VERSION ""

NS_ :

BS_:

BU_: ABS_BASE ATCM_DMSM GENERIC_GWMWakeup PBM IPMB TCU_TBS FDSM GSM TRCM GWM _delete ABS_ESC HUD IPMA CCM SASM PSCM SCCM HCM ATCM SUMA_RLM ATCM_FFSM PCU SECM VDM TBM OCS GENERIC TCCM TSTR RCM

BO_ 963 BCM_Lamp_Stat_HS2: 8 GWM
 SG_ Illuminated_Entry_Stat : 63|2@0+ (1,0) [0|3] "SED"  GENERIC
 SG_ Dr_Courtesy_Light_Stat : 49|2@0+ (1,0) [0|3] "SED"  GENERIC
 SG_ Courtesy_Delay_Status : 51|2@0+ (1,0) [0|3] "SED"  GENERIC
 SG_ ImpactEvntFdbck_D_Stat : 53|2@0+ (1,0) [0|3] "SED"  RCM
 SG_ WrlssAcsyChrgInhbt_B_Rq : 40|1@0+ (1,0) [0|1] "SED"  GENERIC
 SG_ DrTgateLck_D_Stat : 61|2@0+ (1,0) [0|3] "SED"  GENERIC
 SG_ PudLampPsngr_D_Rq : 57|2@0+ (1,0) [0|3] "SED"  GENERIC
 SG_ HeadLampLoOut_B_Stat : 32|1@0+ (1,0) [0|1] "SED"  GENERIC
 SG_ CrnrLghtRight_Pc_Rq : 47|7@0+ (1,0) [0|100] "percent"  HCM,GENERIC
 SG_ CrnrLghtLeft_Pc_Rq : 39|7@0+ (1,0) [0|100] "percent"  HCM,GENERIC
 SG_ HeadLghtHiFdbck_D_Stat : 55|2@0+ (1,0) [0|3] "SED"  SCCM
 SG_ PrkLightChime_B_Rq : 25|1@0+ (1,0) [0|1] "SED"  GENERIC
 SG_ TrnNotInPrkChime_B_Rq : 24|1@0+ (1,0) [0|1] "SED"  GENERIC
 SG_ KeyInIgnWarn_B_Cmd : 27|1@0+ (1,0) [0|1] "SED"  GENERIC
 SG_ HomeSafeLtChime_B_Rq : 28|1@0+ (1,0) [0|1] "SED"  GENERIC
 SG_ StopLghtOn_B_Stat : 8|1@0+ (1,0) [0|1] "SED"  ABS_BASE,HCM,ABS_ESC
 SG_ RvrseLghtOn_B_Stat : 9|1@0+ (1,0) [0|1] "SED"  GENERIC
 SG_ PrkLght_D_Stat : 13|2@0+ (1,0) [0|3] "SED"  GENERIC
 SG_ HeadLghtSwtch_D_Stat : 15|2@0+ (1,0) [0|3] "SED"  HCM,IPMA
 SG_ HeadLampLoFrOn_B_Stat : 2|1@0+ (1,0) [0|1] "SED"  IPMA,HCM,SCCM
 SG_ HeadLampLoFlOn_B_Stat : 3|1@0+ (1,0) [0|1] "SED"  IPMA,HCM,SCCM
 SG_ HeadLampLoActv_B_Stat : 4|1@0+ (1,0) [0|1] "SED"  HCM,IPMA
 SG_ Headlamp_On_Wrning_Cmd : 29|1@0+ (1,0) [0|1] "SED"  GENERIC
 SG_ HeadLghtHiOn_B_Stat : 1|1@0+ (1,0) [0|1] "SED"  HCM,IPMA
 SG_ Park_Brake_Chime_Rqst : 26|1@0+ (1,0) [0|1] "SED"  GENERIC
 SG_ BrkWarnInd_B_Rq : 20|1@0+ (1,0) [0|1] "SED"  GENERIC
 SG_ Brk_Fluid_Lvl_Low : 31|2@0+ (1,0) [0|3] "SED"  GENERIC
 SG_ ReducedGuard_D_Stat : 19|2@0+ (1,0) [0|3] "SED"  GENERIC
 SG_ Perimeter_Alarm_Status : 17|2@0+ (1,0) [0|3] "SED"  TCU_TBS,GENERIC
 SG_ PudLampDrv_D_Rq : 59|2@0+ (1,0) [0|3] "SED"  GENERIC
 SG_ Courtesy_BSave_Stat : 7|2@0+ (1,0) [0|3] "SED"  GENERIC
 SG_ DayRnngLampOn_B_Stat : 5|1@0+ (1,0) [0|1] "SED"  HCM,IPMA
 SG_ WndwGlbl_D_Cmd : 23|3@0+ (1,0) [0|7] "SED"  GENERIC
 SG_ PudLamp_D_Rq : 11|2@0+ (1,0) [0|3] "SED"  GENERIC
 SG_ PerimeterAlarmChimeRq : 0|1@0+ (1,0) [0|1] "SED"  GENERIC

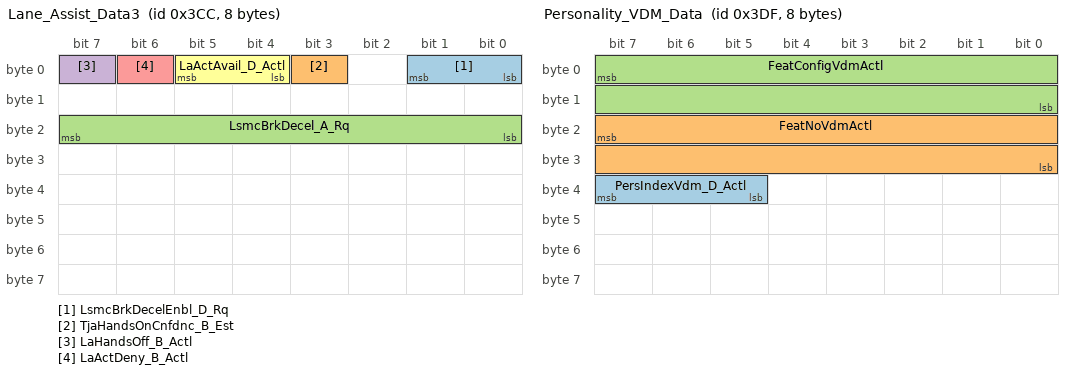
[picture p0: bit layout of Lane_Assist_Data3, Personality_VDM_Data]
BO_ 972 Lane_Assist_Data3: 8 PSCM
 SG_ LsmcBrkDecelEnbl_D_Rq : 1|2@0+ (1,0) [0|3] "SED"  ABS_BASE,ABS_ESC
 SG_ TjaHandsOnCnfdnc_B_Est : 3|1@0+ (1,0) [0|1] "SED"  IPMA
 SG_ LsmcBrkDecel_A_Rq : 23|8@0+ (0.1,0) [0|25.5] "m/s^2"  ABS_BASE,ABS_ESC
 SG_ LaHandsOff_B_Actl : 7|1@0+ (1,0) [0|1] "SED"  GWM,IPMA
 SG_ LaActDeny_B_Actl : 6|1@0+ (1,0) [0|1] "SED"  IPMA,GWM
 SG_ LaActAvail_D_Actl : 5|2@0+ (1,0) [0|3] "SED"  IPMA,GWM

BO_ 991 Personality_VDM_Data: 8 VDM
 SG_ PersIndexVdm_D_Actl : 39|3@0+ (1,0) [0|7] "SED"  GWM
 SG_ FeatNoVdmActl : 23|16@0+ (1,0) [0|65535] "Number"  GWM
 SG_ FeatConfigVdmActl : 7|16@0+ (1,0) [0|65535] "Undefined"  GWM

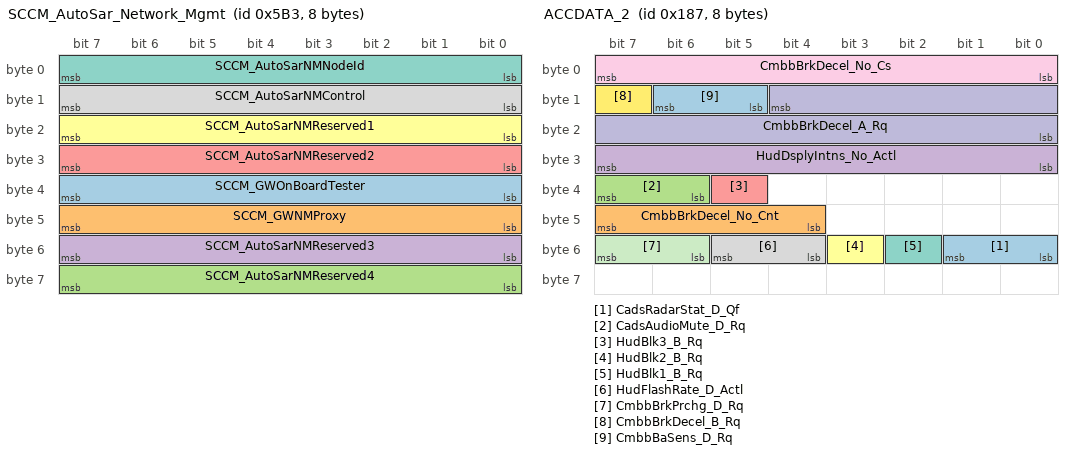
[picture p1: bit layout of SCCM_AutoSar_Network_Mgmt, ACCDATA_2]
BO_ 1459 SCCM_AutoSar_Network_Mgmt: 8 SCCM
 SG_ SCCM_GWOnBoardTester : 39|8@0+ (1,0) [0|255] "unitless"  GWM
 SG_ SCCM_GWNMProxy : 47|8@0+ (1,0) [0|255] "unitless"  GWM
 SG_ SCCM_AutoSarNMReserved4 : 63|8@0+ (1,0) [0|255] "unitless"  GWM
 SG_ SCCM_AutoSarNMReserved3 : 55|8@0+ (1,0) [0|255] "unitless"  GWM
 SG_ SCCM_AutoSarNMReserved2 : 31|8@0+ (1,0) [0|255] "unitless"  GWM
 SG_ SCCM_AutoSarNMReserved1 : 23|8@0+ (1,0) [0|255] "unitless"  GWM
 SG_ SCCM_AutoSarNMNodeId : 7|8@0+ (1,0) [0|255] "unitless"  GWM
 SG_ SCCM_AutoSarNMControl : 15|8@0+ (1,0) [0|255] "unitless"  GWM

BO_ 391 ACCDATA_2: 8 IPMA
 SG_ CadsRadarStat_D_Qf : 49|2@0+ (1,0) [0|3] "SED"  IPMA
 SG_ CmbbBrkDecel_No_Cnt : 47|4@0+ (1,0) [0|15] "Unitless"  ABS_BASE,ABS_ESC
 SG_ CadsAudioMute_D_Rq : 39|2@0+ (1,0) [0|3] "SED"  GWM
 SG_ HudDsplyIntns_No_Actl : 31|8@0+ (0.5,0) [0|100] "%"  HUD
 SG_ HudBlk3_B_Rq : 37|1@0+ (1,0) [0|1] "SED"  HUD
 SG_ HudBlk2_B_Rq : 51|1@0+ (1,0) [0|1] "SED"  HUD
 SG_ HudBlk1_B_Rq : 50|1@0+ (1,0) [0|1] "SED"  HUD
 SG_ HudFlashRate_D_Actl : 53|2@0+ (1,0) [0|3] "SED"  HUD,IPMA
 SG_ CmbbBrkDecel_No_Cs : 7|8@0+ (1,0) [0|255] "Unitless"  ABS_BASE,ABS_ESC
 SG_ CmbbBrkDecel_A_Rq : 12|13@0+ (0.0039,-20) [-20|11.9449] "m/s^2"  ABS_BASE,GWM,ABS_ESC,RCM
 SG_ CmbbBrkPrchg_D_Rq : 55|2@0+ (1,0) [0|3] "SED"  ABS_BASE,GWM,ABS_ESC,RCM
 SG_ CmbbBrkDecel_B_Rq : 15|1@0+ (1,0) [0|1] "SED"  ABS_BASE,GWM,ABS_ESC,RCM
 SG_ CmbbBaSens_D_Rq : 14|2@0+ (1,0) [0|3] "SED"  ABS_BASE,GWM,ABS_ESC,RCM

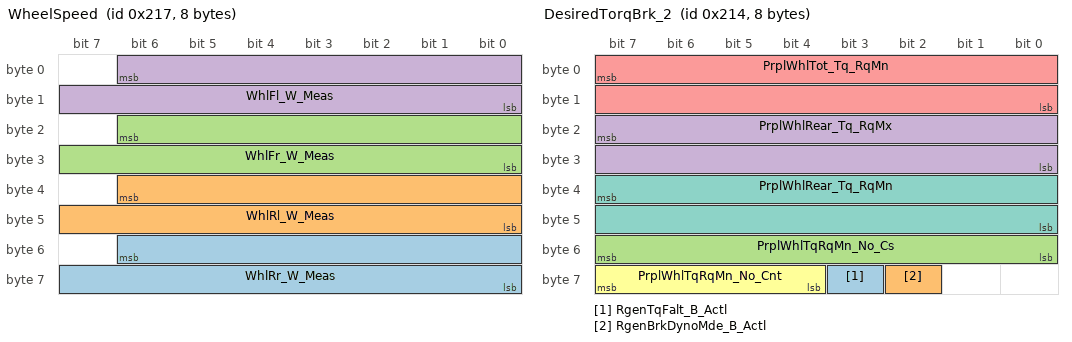
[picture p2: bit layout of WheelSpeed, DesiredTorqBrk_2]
BO_ 535 WheelSpeed: 8 ABS_ESC
 SG_ WhlRr_W_Meas : 54|15@0+ (0.01,0) [0|327.65] "rad/s"  IPMA,IPMB,PBM,TCCM,PSCM,GWM,CCM
 SG_ WhlRl_W_Meas : 38|15@0+ (0.01,0) [0|327.65] "rad/s"  IPMA,IPMB,PBM,TCCM,PSCM,GWM,CCM
 SG_ WhlFr_W_Meas : 22|15@0+ (0.01,0) [0|327.65] "rad/s"  IPMA,IPMB,PBM,TCCM,PSCM,GWM,CCM
 SG_ WhlFl_W_Meas : 6|15@0+ (0.01,0) [0|327.65] "rad/s"  IPMA,IPMB,PBM,TCCM,PSCM,GWM,CCM

BO_ 532 DesiredTorqBrk_2: 8 ABS_ESC
 SG_ RgenTqFalt_B_Actl : 59|1@0+ (1,0) [0|1] "SED"  GWM
 SG_ RgenBrkDynoMde_B_Actl : 58|1@0+ (1,0) [0|1] "SED"  GWM
 SG_ PrplWhlTqRqMn_No_Cs : 55|8@0+ (1,0) [0|255] "Unitless"  GWM
 SG_ PrplWhlRear_Tq_RqMx : 23|16@0+ (4,-131072) [-131072|131068] "Nm"  GWM
 SG_ PrplWhlTot_Tq_RqMn : 7|16@0+ (4,-131072) [-131072|131068] "Nm"  GWM
 SG_ PrplWhlTqRqMn_No_Cnt : 63|4@0+ (1,0) [0|15] "Unitless"  GWM
 SG_ PrplWhlRear_Tq_RqMn : 39|16@0+ (4,-131072) [-131072|131068] "Nm"  GWM

BO_ 531 DesiredTorqBrk: 8 ABS_ESC
 SG_ VehStop_D_Stat : 28|2@0+ (1,0) [0|3] "SED"  GWM,CCM,FDSM,IPMA
 SG_ TracCtlPtActv_B_Actl : 31|1@0+ (1,0) [0|1] "SED"  IPMA,GWM,VDM,TCCM,RCM,CCM
 SG_ LscmbbMntr_B_Err : 17|1@0+ (1,0) [0|1] "SED"  GWM
 SG_ LscmbbBrkDis_B_Actl : 19|1@0+ (1,0) [0|1] "SED"  FDSM,GWM
 SG_ LscmbbDeny_B_ActlBrk : 18|1@0+ (1,0) [0|1] "SED"  FDSM,GWM
 SG_ PrkBrkYwLamp_D_Rq : 38|2@0+ (1,0) [0|3] "SED"  GWM
 SG_ PrkBrkRedLamp_D_Rq : 30|2@0+ (1,0) [0|3] "SED"  GWM
 SG_ VehicleStationary : 39|1@0+ (1,0) [0|1] "SED"  IPMA,GWM,CCM,FDSM
 SG_ LscmbbBrkDecel_B_Actl : 20|1@0+ (1,0) [0|1] "SED"  FDSM,GWM
 SG_ AbsActv_B_Actl : 45|1@0+ (1,0) [0|1] "SED"  IPMA,PBM,SASM,TBM,RCM,CCM,GWM,PSCM,TRCM,VDM
 SG_ StabCtlBrkActv_B_Actl : 23|1@0+ (1,0) [0|1] "SED"  IPMA,SASM,TCCM,PSCM,VDM,GWM,RCM,CCM
 SG_ CmbbBrkPrchg_B_Actl : 59|1@0+ (1,0) [0|1] "SED"  IPMA,TBM,GWM,CCM
 SG_ CmbbBrkDecel_B_Actl : 58|1@0+ (1,0) [0|1] "SED"  IPMA,TBM,GWM,CCM
 SG_ CmbbBaSensInc_B_Actl : 57|1@0+ (1,0) [0|1] "SED"  IPMA,GWM,CCM
 SG_ AccBrkWarm_B_Actl : 63|1@0+ (1,0) [0|1] "SED"  IPMA,GWM,CCM
 SG_ AccBrkTotTqMn_B_Actl : 62|1@0+ (1,0) [0|1] "SED"  IPMA,TBM,GWM,CCM
 SG_ AccBrkPrchgActv_B_Actl : 61|1@0+ (1,0) [0|1] "SED"  IPMA,GWM,CCM
 SG_ AccBrkDis_B_Actl : 44|1@0+ (1,0) [0|1] "SED"  IPMA,GWM,CCM
 SG_ AccBrkDeny_B_Actl : 42|1@0+ (1,0) [0|1] "SED"  IPMA,GWM,CCM
 SG_ AccBrkActv_B_Actl : 43|1@0+ (1,0) [0|1] "SED"  IPMA,GWM,CCM
 SG_ PrplDrgCtlActv_B_Actl : 46|1@0+ (1,0) [0|1] "SED"  GWM
 SG_ PrplWhlTot_Tq_RqMx : 7|16@0+ (4,-131072) [-131072|131068] "Nm"  TCCM,GWM
 SG_ LscmbbBaSensInc_B_Actl : 21|1@0+ (1,0) [0|1] "SED"  FDSM,GWM
 SG_ CmbbBrkDis_B_Actl : 56|1@0+ (1,0) [0|1] "SED"  IPMA,PSCM,GWM,CCM
 SG_ CmbbDeny_B_ActlBrk : 60|1@0+ (1,0) [0|1] "SED"  IPMA,PSCM,GWM,CCM
 SG_ CcDis_B_Cmd : 47|1@0+ (1,0) [0|1] "SED"  GWM
 SG_ VehLongOvrGnd_A_Est : 41|10@0+ (0.035,-17.9) [-17.9|17.835] "m/s^2"  IPMA,VDM,TCCM,TBM,GWM,FDSM,CCM
 SG_ LscmbBrkPrchg_B_Actl : 16|1@0+ (1,0) [0|1] "SED"  FDSM,GWM
 SG_ AccStopActv_B_ActlBrk : 22|1@0+ (1,0) [0|1] "SED"  IPMA,CCM,GWM
 SG_ AccDis_B_ActlEpb : 32|1@0+ (1,0) [0|1] "SED"  IPMA,GWM,CCM
 SG_ PrkBrkMsgTxt_D_Rq : 36|4@0+ (1,0) [0|15] "SED"  GWM
 SG_ PrkBrkStatus : 26|3@0+ (1,0) [0|7] "SED"  GSM,IPMB,IPMA,CCM,GWM

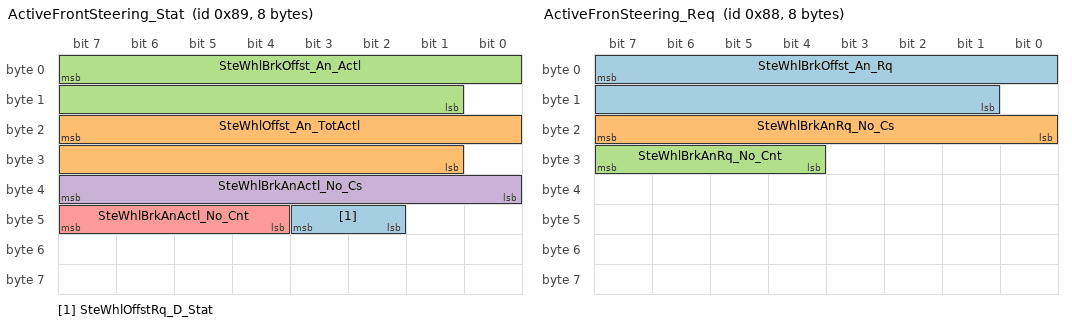
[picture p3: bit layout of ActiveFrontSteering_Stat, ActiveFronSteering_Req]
BO_ 137 ActiveFrontSteering_Stat: 8 SASM
 SG_ SteWhlOffstRq_D_Stat : 43|2@0+ (1,0) [0|3] "SED"  ABS_BASE,ABS_ESC
 SG_ SteWhlOffst_An_TotActl : 23|15@0+ (0.1,-1600) [-1600|1676.5] "degrees"  ABS_BASE,ABS_ESC
 SG_ SteWhlBrkOffst_An_Actl : 7|15@0+ (0.1,-1600) [-1600|1676.5] "degrees"  ABS_BASE,GWM,ABS_ESC
 SG_ SteWhlBrkAnActl_No_Cs : 39|8@0+ (1,0) [0|255] "Unitless"  ABS_BASE,ABS_ESC
 SG_ SteWhlBrkAnActl_No_Cnt : 47|4@0+ (1,0) [0|15] "Unitless"  ABS_BASE,ABS_ESC

BO_ 136 ActiveFronSteering_Req: 8 ABS_ESC
 SG_ SteWhlBrkOffst_An_Rq : 7|15@0+ (0.1,-1600) [-1600|1676.5] "degrees"  SASM
 SG_ SteWhlBrkAnRq_No_Cs : 23|8@0+ (1,0) [0|255] "Unitless"  SASM
 SG_ SteWhlBrkAnRq_No_Cnt : 31|4@0+ (1,0) [0|15] "Unitless"  SASM

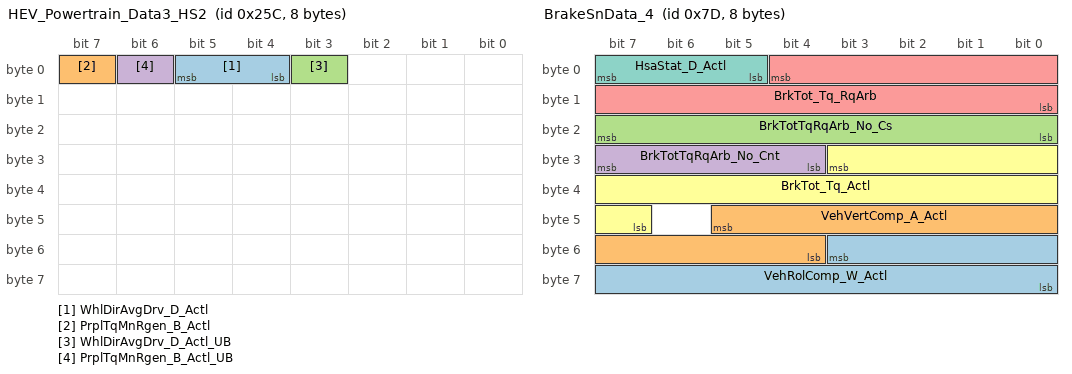
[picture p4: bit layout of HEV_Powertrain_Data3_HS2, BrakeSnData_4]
BO_ 604 HEV_Powertrain_Data3_HS2: 8 GWM
 SG_ WhlDirAvgDrv_D_Actl : 5|2@0+ (1,0) [0|3] "SED"  ABS_ESC,ABS_BASE,FDSM
 SG_ PrplTqMnRgen_B_Actl : 7|1@0+ (1,0) [0|1] "SED"  ABS_ESC,ABS_BASE
 SG_ WhlDirAvgDrv_D_Actl_UB : 3|1@0+ (1,0) [0|1] "SED"  ABS_BASE,ABS_ESC,FDSM
 SG_ PrplTqMnRgen_B_Actl_UB : 6|1@0+ (1,0) [0|1] "SED"  ABS_BASE,ABS_ESC

BO_ 2015 TesterFunctionalReq_H2: 8 TSTR
 SG_ TesterFunctionalReq : 7|64@0+ (1,0) [0|1.84467E+019] ""  SUMA_RLM,ABS_BASE,SECM,ATCM_FFSM,IPMB,SASM,HCM,ATCM_DMSM,TCU_TBS,FDSM,PBM,RCM,GSM,TRCM,PCU,OCS,TCCM,CCM,ABS_ESC,ATCM,HUD,IPMA,PSCM,SCCM,TBM,VDM,GWM

BO_ 125 BrakeSnData_4: 8 ABS_ESC
 SG_ VehRolComp_W_Actl : 51|12@0+ (0.03663,-75) [-75|74.92659] "degrees/sec"  PSCM,VDM,GWM
 SG_ VehVertComp_A_Actl : 45|10@0+ (0.035,-17.9) [-17.9|17.835] "m/s^2"  PSCM,GWM,VDM
 SG_ BrkTotTqRqArb_No_Cs : 23|8@0+ (1,0) [0|255] "Unitless"  TBM,GWM
 SG_ BrkTotTqRqArb_No_Cnt : 31|4@0+ (1,0) [0|15] "Unitless"  TBM,GWM
 SG_ BrkTot_Tq_RqArb : 4|13@0+ (4,0) [0|32756] "Nm"  HCM,IPMA,TBM,VDM,GWM,CCM
 SG_ BrkTot_Tq_Actl : 27|13@0+ (4,0) [0|32756] "Nm"  PSCM,PBM,RCM,FDSM,GWM
 SG_ HsaStat_D_Actl : 7|3@0+ (1,0) [0|7] "SED"  GWM

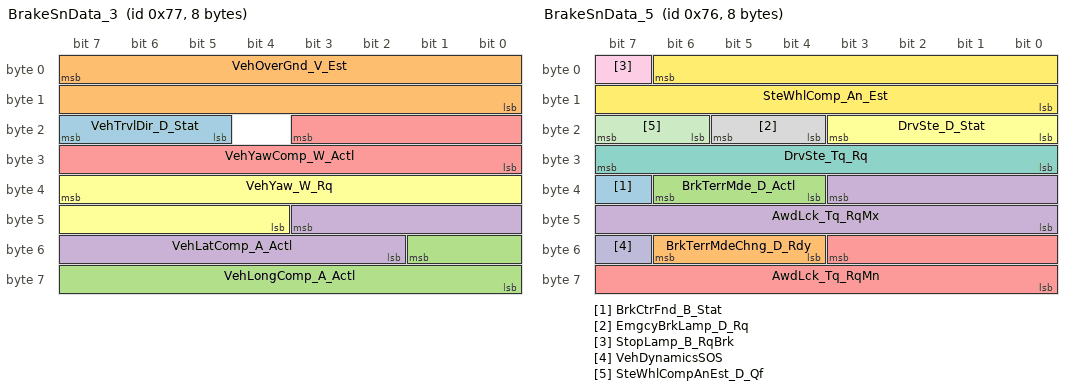
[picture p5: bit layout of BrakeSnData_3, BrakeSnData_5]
BO_ 119 BrakeSnData_3: 8 ABS_ESC
 SG_ VehTrvlDir_D_Stat : 23|3@0+ (1,0) [0|7] "SED"  SASM
 SG_ VehOverGnd_V_Est : 7|16@0+ (0.01,0) [0|655.33] "kph"  IPMA,SASM,PSCM,TCCM,GWM,CCM,FDSM
 SG_ VehLongComp_A_Actl : 49|10@0+ (0.035,-17.9) [-17.9|17.835] "m/s^2"  PBM,PSCM,VDM,GWM
 SG_ VehLatComp_A_Actl : 43|10@0+ (0.035,-17.9) [-17.9|17.835] "m/s^2"  CCM,TCCM,PSCM,FDSM,VDM,GWM
 SG_ VehYawComp_W_Actl : 19|12@0+ (0.03663,-75) [-75|74.92659] "deg/s"  IPMA,VDM,SASM,TCCM,PSCM,FDSM,GWM,CCM
 SG_ VehYaw_W_Rq : 39|12@0+ (0.03663,-75) [-75|74.92659] "deg/s"  GWM

BO_ 118 BrakeSnData_5: 8 ABS_ESC
 SG_ BrkCtrFnd_B_Stat : 39|1@0+ (1,0) [0|1] "SED"  GENERIC
 SG_ BrkTerrMdeChng_D_Rdy : 54|3@0+ (1,0) [0|7] "SED"  GENERIC
 SG_ BrkTerrMde_D_Actl : 38|3@0+ (1,0) [0|7] "SED"  GENERIC
 SG_ AwdLck_Tq_RqMx : 35|12@0+ (1,0) [0|4095] "Nm"  GENERIC
 SG_ AwdLck_Tq_RqMn : 51|12@0+ (1,0) [0|4095] "Nm"  GENERIC
 SG_ DrvSte_D_Stat : 19|4@0+ (1,0) [0|15] "SED"  PSCM,GWM
 SG_ DrvSte_Tq_Rq : 31|8@0+ (0.0625,-8) [-8|7.8125] "Nm"  PSCM,GWM
 SG_ EmgcyBrkLamp_D_Rq : 21|2@0+ (1,0) [0|3] "SED"  GWM
 SG_ StopLamp_B_RqBrk : 7|1@0+ (1,0) [0|1] "SED"  GWM,FDSM
 SG_ VehDynamicsSOS : 55|1@0+ (1,0) [0|1] "SED"  GWM
 SG_ SteWhlCompAnEst_D_Qf : 23|2@0+ (1,0) [0|3] "SED"  IPMA,RCM,GWM
 SG_ SteWhlComp_An_Est : 6|15@0+ (0.1,-1600) [-1600|1676.7] "deg"  IPMA,RCM,GWM

BO_ 1713 ABS_Rapid_Data_Response_2: 8 ABS_ESC
 SG_ UUDTABSResponse2 : 7|64@0+ (1,0) [0|1.844674407371E+019] "unitless"  TSTR

BO_ 1712 ABS_Rapid_Data_Response_1: 8 ABS_ESC
 SG_ UUDTABSResponse1 : 7|64@0+ (1,0) [0|1.844674407371E+019] "unitless"  TSTR

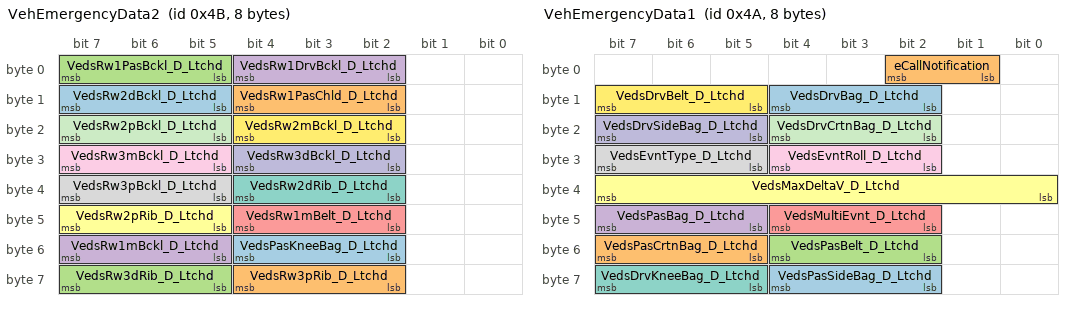
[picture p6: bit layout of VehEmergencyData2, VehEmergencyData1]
BO_ 75 VehEmergencyData2: 8 RCM
 SG_ VedsPasKneeBag_D_Ltchd : 52|3@0+ (1,0) [0|7] "SED"  GWM
 SG_ VedsRw3pRib_D_Ltchd : 60|3@0+ (1,0) [0|7] "SED"  GWM
 SG_ VedsRw3dRib_D_Ltchd : 63|3@0+ (1,0) [0|7] "SED"  GWM
 SG_ VedsRw1mBckl_D_Ltchd : 55|3@0+ (1,0) [0|7] "SED"  GWM
 SG_ VedsRw1mBelt_D_Ltchd : 44|3@0+ (1,0) [0|7] "SED"  GWM
 SG_ VedsRw2pRib_D_Ltchd : 47|3@0+ (1,0) [0|7] "SED"  GWM
 SG_ VedsRw2dRib_D_Ltchd : 36|3@0+ (1,0) [0|7] "SED"  GWM
 SG_ VedsRw3pBckl_D_Ltchd : 39|3@0+ (1,0) [0|7] "SED"  GWM
 SG_ VedsRw3mBckl_D_Ltchd : 31|3@0+ (1,0) [0|7] "SED"  GWM
 SG_ VedsRw3dBckl_D_Ltchd : 28|3@0+ (1,0) [0|7] "SED"  GWM
 SG_ VedsRw2pBckl_D_Ltchd : 23|3@0+ (1,0) [0|7] "SED"  GWM
 SG_ VedsRw2mBckl_D_Ltchd : 20|3@0+ (1,0) [0|7] "SED"  GWM
 SG_ VedsRw2dBckl_D_Ltchd : 15|3@0+ (1,0) [0|7] "SED"  GWM
 SG_ VedsRw1PasChld_D_Ltchd : 12|3@0+ (1,0) [0|7] "SED"  GWM
 SG_ VedsRw1PasBckl_D_Ltchd : 7|3@0+ (1,0) [0|7] "SED"  GWM
 SG_ VedsRw1DrvBckl_D_Ltchd : 4|3@0+ (1,0) [0|7] "SED"  GWM

BO_ 74 VehEmergencyData1: 8 RCM
 SG_ VedsPasSideBag_D_Ltchd : 60|3@0+ (1,0) [0|7] "SED"  GWM
 SG_ VedsPasCrtnBag_D_Ltchd : 55|3@0+ (1,0) [0|7] "SED"  GWM
 SG_ VedsPasBelt_D_Ltchd : 52|3@0+ (1,0) [0|7] "SED"  GWM
 SG_ VedsPasBag_D_Ltchd : 47|3@0+ (1,0) [0|7] "SED"  GWM
 SG_ VedsMultiEvnt_D_Ltchd : 44|3@0+ (1,0) [0|7] "SED"  GWM
 SG_ VedsMaxDeltaV_D_Ltchd : 39|8@0+ (1,0) [0|255] "kph"  GWM
 SG_ VedsDrvKneeBag_D_Ltchd : 63|3@0+ (1,0) [0|7] "SED"  GWM
 SG_ VedsEvntType_D_Ltchd : 31|3@0+ (1,0) [0|7] "SED"  GWM
 SG_ VedsEvntRoll_D_Ltchd : 28|3@0+ (1,0) [0|7] "SED"  GWM
 SG_ VedsDrvSideBag_D_Ltchd : 23|3@0+ (1,0) [0|7] "SED"  GWM
 SG_ VedsDrvCrtnBag_D_Ltchd : 20|3@0+ (1,0) [0|7] "SED"  GWM
 SG_ VedsDrvBelt_D_Ltchd : 15|3@0+ (1,0) [0|7] "SED"  GWM
 SG_ VedsDrvBag_D_Ltchd : 12|3@0+ (1,0) [0|7] "SED"  GWM
 SG_ eCallNotification : 2|2@0+ (1,0) [0|3] "SED"  GWM

BO_TX_BU_ 972 : SASM,SCCM,PSCM;
BO_TX_BU_ 991 : SASM,VDM;
BO_TX_BU_ 391 : CCM,IPMA;
BO_TX_BU_ 535 : ABS_BASE,ABS_ESC;
BO_TX_BU_ 532 : ABS_BASE,ABS_ESC;
BO_TX_BU_ 531 : ABS_BASE,GENERIC_GWMWakeup,ABS_ESC;
BO_TX_BU_ 136 : ABS_BASE,ABS_ESC;
BO_TX_BU_ 125 : ABS_BASE,ABS_ESC;
BO_TX_BU_ 119 : ABS_BASE,ABS_ESC;
BO_TX_BU_ 118 : ABS_BASE,ABS_ESC;
BO_TX_BU_ 1713 : ABS_BASE,ABS_ESC;
BO_TX_BU_ 1712 : ABS_BASE,ABS_ESC;
CM_ SG_ 391 CmbbBrkDecel_A_Rq "ABSGenSigTimeoutTime=1000";
CM_ SG_ 391 CmbbBrkPrchg_D_Rq "ABSGenSigTimeoutTime=1000";
CM_ SG_ 391 CmbbBrkDecel_B_Rq "ABSGenSigTimeoutTime=1000";
CM_ SG_ 391 CmbbBaSens_D_Rq "ABSGenSigTimeoutTime=1000";
CM_ BO_ 532 "IC is NOT to use data in this message for displays, Used data from 415 instead.";
CM_ BO_ 531 "When PBM is present use 0x41B for PrkMsgTxt_D_Rq, PrkBrkRedLamp_D_Rq, PrkBrkYwLamp_D_Rq source signals otherwise ABS will source from 0x213.";
CM_ SG_ 531 VehLongOvrGnd_A_Est "CCMGenSigTimeoutTime=1000";
CM_ BO_ 2015 "OBDII Request ($7DF) messages are for FNOS 1.0.1 only.
Diagnostic Functional Addressing ($7DF) and Dual Rate Periodic messages are for FNOS I3 only.";
CM_ SG_ 118 SteWhlCompAnEst_D_Qf "Legacy signal not supported, reserving bit locations for commodity BCM, PAM, RCM dbc files.  GWM to Tx Init value, no valid data. ";
CM_ SG_ 118 SteWhlComp_An_Est "Legacy signal not supported, reserving bit locations for commodity BCM, PAM, RCM dbc files.  GWM to Tx Init value, no valid data. ";
CM_ BO_ 74 "Reserve eCallNotification message";
BA_DEF_ SG_  "GenSigTimeoutTime_GWM" INT 0 100000;
BA_DEF_ BO_  "FrameGatewayNetwork" STRING ;
BA_DEF_ BO_  "FrameGatewayMS1" HEX 0 1407;
BA_DEF_ BO_  "FrameGatewayHS3" HEX 0 1407;
BA_DEF_ BO_  "FrameGatewayHS1" HEX 0 1407;
BA_DEF_ BO_  "NetworkInitialization" ENUM  "No","Yes";
BA_DEF_ BO_  "FrameGatewayId" HEX 0 1407;
BA_DEF_ BO_  "EventRateOfChange" INT 10 10000;
BA_DEF_ BO_  "GenMsgStartDelayTime" INT 0 10000;
BA_DEF_ BO_  "GenMsgNrOfRepetition" INT 0 100;
BA_DEF_ BO_  "GenMsgDelayTime" INT 0 1000;
BA_DEF_ BO_  "GenMsgCycleTime" INT 0 100000;
BA_DEF_ BO_  "GenMsgSendType" ENUM  "FixedPeriodic","Event","EnabledPeriodic","NotUsed","NotUsed","EventPeriodic","NotUsed","NotUsed","NoMsgSendType";
BA_DEF_ SG_  "U_U611_U625_MY20_Phev_Tx" ENUM  "No","Yes";
BA_DEF_ SG_  "U_CX482_CX483_MY20_Hev_Tx" ENUM  "No","Yes";
BA_DEF_ SG_  "U_CX482_CX483_MY20_Gas_Tx" ENUM  "No","Yes";
BA_DEF_ SG_  "U_CX482_CX483_MY20_Diesel_Tx" ENUM  "No","Yes";
BA_DEF_ SG_  "U_U611_U625_MY20_Hev_Tx" ENUM  "No","Yes";
BA_DEF_ SG_  "U_U611_U625_MY20_Gas_Tx" ENUM  "No","Yes";
BA_DEF_ SG_  "U_U611_U625_MY20_Diesel_Tx" ENUM  "No","Yes";
BA_DEF_ SG_  "U_LC1_B500_MY18_Gas_Tx" ENUM  "No","Yes";
BA_DEF_ SG_  "U_LC1_B500_MY18_Diesel_Tx" ENUM  "No","Yes";
BA_DEF_ SG_  "U_B500_MY18_Diesel_Tx" ENUM  "No","Yes";
BA_DEF_ SG_  "U_B500_MY18_Gas_Tx" ENUM  "No","Yes";
BA_DEF_ SG_  "U_C490_MY18_Tx" ENUM  "No","Yes";
BA_DEF_ SG_  "U_B562_MY18_Gas_Tx" ENUM  "No","Yes";
BA_DEF_ SG_  "U_C519_MY18_5_Gas_Tx" ENUM  "No","Yes";
BA_DEF_ SG_  "U_C519_MY18_5_Diesel_Tx" ENUM  "No","Yes";
BA_DEF_ SG_  "U_B515_MCA_MY17_Gas_Tx" ENUM  "No","Yes";
BA_DEF_ SG_  "U_B515_MCA_MY17_Diesel_Tx" ENUM  "No","Yes";
BA_DEF_ SG_  "U_B479_MY17_Diesel_Tx" ENUM  "No","Yes";
BA_DEF_ SG_  "U_B479_MY17_Gas_Tx" ENUM  "No","Yes";
BA_DEF_ SG_  "U_B562LC_MY15_Gas_Tx" ENUM  "No","Yes";
BA_DEF_ SG_  "U_B562LC_MY15_Diesel_Tx" ENUM  "No","Yes";
BA_DEF_ SG_  "U_U611_U625_MY20_Phev_Rx" ENUM  "No","Yes";
BA_DEF_ SG_  "U_CX482_CX483_MY20_Hev_Rx" ENUM  "No","Yes";
BA_DEF_ SG_  "U_CX482_CX483_MY20_Gas_Rx" ENUM  "No","Yes";
BA_DEF_ SG_  "U_CX482_CX483_MY20_Diesel_Rx" ENUM  "No","Yes";
BA_DEF_ SG_  "U_U611_U625_MY20_Hev_Rx" ENUM  "No","Yes";
BA_DEF_ SG_  "U_U611_U625_MY20_Gas_Rx" ENUM  "No","Yes";
BA_DEF_ SG_  "U_U611_U625_MY20_Diesel_Rx" ENUM  "No","Yes";
BA_DEF_ SG_  "U_B500_MY18_Diesel_Rx" ENUM  "No","Yes";
BA_DEF_ SG_  "U_B500_MY18_Gas_Rx" ENUM  "No","Yes";
BA_DEF_ SG_  "U_C490_MY18_Rx" ENUM  "No","Yes";
BA_DEF_ SG_  "U_B562_MY18_Gas_Rx" ENUM  "No","Yes";
BA_DEF_ SG_  "U_C519_MY18_5_Gas_Rx" ENUM  "No","Yes";
BA_DEF_ SG_  "U_C519_MY18_5_Diesel_Rx" ENUM  "No","Yes";
BA_DEF_ SG_  "U_B515_MCA_MY17_Gas_Rx" ENUM  "No","Yes";
BA_DEF_ SG_  "U_B515_MCA_MY17_Diesel_Rx" ENUM  "No","Yes";
BA_DEF_ SG_  "U_B479_MY17_Diesel_Rx" ENUM  "No","Yes";
BA_DEF_ SG_  "U_B479_MY17_Gas_Rx" ENUM  "No","Yes";
BA_DEF_ SG_  "U_B562LC_MY15_Gas_Rx" ENUM  "No","Yes";
BA_DEF_ SG_  "U_B562LC_MY15_Diesel_Rx" ENUM  "No","Yes";
BA_DEF_ SG_  "ContentDependant" ENUM  "No","Yes";
BA_DEF_ SG_  "GenSigStartValue" INT 0 1000000000;
BA_DEF_ SG_  "UsedOnPgmDBC" ENUM  "No","Yes";
BA_DEF_ SG_  "CrossOver_InfoCAN" ENUM  "No","Yes";
BA_DEF_ SG_  "WakeupSignal" ENUM  "No","Yes";
BA_DEF_ SG_  "GenSigMissingSourceValue" INT 0 1000000000;
BA_DEF_ SG_  "GenSigSendType" ENUM  "Cyclic","OnWrite","vector_leerstring","OnChange","vector_leerstring","IfActive","vector_leerstring","NoSigSendType";
BA_DEF_ BO_  "GenMsgRoutingTimeoutTime" INT 0 1000;
BA_DEF_ BO_  "MessageGateway" ENUM  "No","Yes";
BA_DEF_ BO_  "NmAsrMessage" ENUM  "No","Yes";
BA_DEF_ BO_  "TpApplType" STRING ;
BA_DEF_ BO_  "DiagState" ENUM  "No","Yes";
BA_DEF_ BO_  "DiagRequest" ENUM  "No","Yes";
BA_DEF_ BO_  "DiagResponse" ENUM  "No","Yes";
BA_DEF_ BO_  "GenMsgILSupport" ENUM  "No","Yes";
BA_DEF_DEF_  "GenSigTimeoutTime_GWM" 0;
BA_DEF_DEF_  "FrameGatewayNetwork" "NONE";
BA_DEF_DEF_  "FrameGatewayMS1" 0;
BA_DEF_DEF_  "FrameGatewayHS3" 0;
BA_DEF_DEF_  "FrameGatewayHS1" 0;
BA_DEF_DEF_  "NetworkInitialization" "Yes";
BA_DEF_DEF_  "FrameGatewayId" 0;
BA_DEF_DEF_  "EventRateOfChange" 10000;
BA_DEF_DEF_  "GenMsgStartDelayTime" 0;
BA_DEF_DEF_  "GenMsgNrOfRepetition" 1;
BA_DEF_DEF_  "GenMsgDelayTime" 20;
BA_DEF_DEF_  "GenMsgCycleTime" 0;
BA_DEF_DEF_  "GenMsgSendType" "NoMsgSendType";
BA_DEF_DEF_  "U_U611_U625_MY20_Phev_Tx" "No";
BA_DEF_DEF_  "U_CX482_CX483_MY20_Hev_Tx" "No";
BA_DEF_DEF_  "U_CX482_CX483_MY20_Gas_Tx" "No";
BA_DEF_DEF_  "U_CX482_CX483_MY20_Diesel_Tx" "No";
BA_DEF_DEF_  "U_U611_U625_MY20_Hev_Tx" "No";
BA_DEF_DEF_  "U_U611_U625_MY20_Gas_Tx" "No";
BA_DEF_DEF_  "U_U611_U625_MY20_Diesel_Tx" "No";
BA_DEF_DEF_  "U_LC1_B500_MY18_Gas_Tx" "No";
BA_DEF_DEF_  "U_LC1_B500_MY18_Diesel_Tx" "No";
BA_DEF_DEF_  "U_B500_MY18_Diesel_Tx" "No";
BA_DEF_DEF_  "U_B500_MY18_Gas_Tx" "No";
BA_DEF_DEF_  "U_C490_MY18_Tx" "No";
BA_DEF_DEF_  "U_B562_MY18_Gas_Tx" "No";
BA_DEF_DEF_  "U_C519_MY18_5_Gas_Tx" "No";
BA_DEF_DEF_  "U_C519_MY18_5_Diesel_Tx" "No";
BA_DEF_DEF_  "U_B515_MCA_MY17_Gas_Tx" "No";
BA_DEF_DEF_  "U_B515_MCA_MY17_Diesel_Tx" "No";
BA_DEF_DEF_  "U_B479_MY17_Diesel_Tx" "No";
BA_DEF_DEF_  "U_B479_MY17_Gas_Tx" "No";
BA_DEF_DEF_  "U_B562LC_MY15_Gas_Tx" "No";
BA_DEF_DEF_  "U_B562LC_MY15_Diesel_Tx" "No";
BA_DEF_DEF_  "U_U611_U625_MY20_Phev_Rx" "No";
BA_DEF_DEF_  "U_CX482_CX483_MY20_Hev_Rx" "No";
BA_DEF_DEF_  "U_CX482_CX483_MY20_Gas_Rx" "No";
BA_DEF_DEF_  "U_CX482_CX483_MY20_Diesel_Rx" "No";
BA_DEF_DEF_  "U_U611_U625_MY20_Hev_Rx" "No";
BA_DEF_DEF_  "U_U611_U625_MY20_Gas_Rx" "No";
BA_DEF_DEF_  "U_U611_U625_MY20_Diesel_Rx" "No";
BA_DEF_DEF_  "U_B500_MY18_Diesel_Rx" "No";
BA_DEF_DEF_  "U_B500_MY18_Gas_Rx" "No";
BA_DEF_DEF_  "U_C490_MY18_Rx" "No";
BA_DEF_DEF_  "U_B562_MY18_Gas_Rx" "No";
BA_DEF_DEF_  "U_C519_MY18_5_Gas_Rx" "No";
BA_DEF_DEF_  "U_C519_MY18_5_Diesel_Rx" "No";
BA_DEF_DEF_  "U_B515_MCA_MY17_Gas_Rx" "No";
BA_DEF_DEF_  "U_B515_MCA_MY17_Diesel_Rx" "No";
BA_DEF_DEF_  "U_B479_MY17_Diesel_Rx" "No";
BA_DEF_DEF_  "U_B479_MY17_Gas_Rx" "No";
BA_DEF_DEF_  "U_B562LC_MY15_Gas_Rx" "No";
BA_DEF_DEF_  "U_B562LC_MY15_Diesel_Rx" "No";
BA_DEF_DEF_  "ContentDependant" "No";
BA_DEF_DEF_  "GenSigStartValue" 0;
BA_DEF_DEF_  "UsedOnPgmDBC" "Yes";
BA_DEF_DEF_  "CrossOver_InfoCAN" "No";
BA_DEF_DEF_  "WakeupSignal" "No";
BA_DEF_DEF_  "GenSigMissingSourceValue" 0;
BA_DEF_DEF_  "GenSigSendType" "NoSigSendType";
BA_DEF_DEF_  "GenMsgRoutingTimeoutTime" 0;
BA_DEF_DEF_  "MessageGateway" "No";
BA_DEF_DEF_  "NmAsrMessage" "No";
BA_DEF_DEF_  "TpApplType" "";
BA_DEF_DEF_  "DiagState" "No";
BA_DEF_DEF_  "DiagRequest" "No";
BA_DEF_DEF_  "DiagResponse" "No";
BA_DEF_DEF_  "GenMsgILSupport" "Yes";
BA_ "FrameGatewayNetwork" BO_ 963 "HS1_CAN";
BA_ "FrameGatewayHS1" BO_ 963 963;
BA_ "FrameGatewayId" BO_ 963 963;
BA_ "GenMsgStartDelayTime" BO_ 963 300;
BA_ "GenMsgDelayTime" BO_ 972 10;
BA_ "GenMsgCycleTime" BO_ 972 30;
BA_ "GenMsgSendType" BO_ 972 0;
BA_ "GenMsgCycleTime" BO_ 991 1000;
BA_ "GenMsgSendType" BO_ 991 5;
BA_ "NetworkInitialization" BO_ 1459 0;
BA_ "GenMsgCycleTime" BO_ 1459 1000;
BA_ "GenMsgSendType" BO_ 1459 0;
BA_ "NmAsrMessage" BO_ 1459 1;
BA_ "GenMsgILSupport" BO_ 1459 0;
BA_ "GenMsgDelayTime" BO_ 391 10;
BA_ "GenMsgCycleTime" BO_ 391 20;
BA_ "GenMsgSendType" BO_ 391 0;
BA_ "GenMsgDelayTime" BO_ 535 0;
BA_ "GenMsgCycleTime" BO_ 535 10;
BA_ "GenMsgSendType" BO_ 535 0;
BA_ "GenMsgDelayTime" BO_ 532 10;
BA_ "GenMsgCycleTime" BO_ 532 20;
BA_ "GenMsgSendType" BO_ 532 0;
BA_ "GenMsgDelayTime" BO_ 531 10;
BA_ "GenMsgCycleTime" BO_ 531 20;
BA_ "GenMsgSendType" BO_ 531 0;
BA_ "FrameGatewayNetwork" BO_ 137 "HS2_CAN";
BA_ "FrameGatewayId" BO_ 137 137;
BA_ "GenMsgDelayTime" BO_ 137 0;
BA_ "GenMsgCycleTime" BO_ 137 10;
BA_ "GenMsgSendType" BO_ 137 0;
BA_ "GenMsgDelayTime" BO_ 136 0;
BA_ "GenMsgCycleTime" BO_ 136 10;
BA_ "GenMsgSendType" BO_ 136 0;
BA_ "GenMsgCycleTime" BO_ 604 100;
BA_ "GenMsgSendType" BO_ 604 5;
BA_ "NetworkInitialization" BO_ 2015 0;
BA_ "GenMsgDelayTime" BO_ 2015 0;
BA_ "GenMsgSendType" BO_ 2015 1;
BA_ "DiagState" BO_ 2015 1;
BA_ "GenMsgILSupport" BO_ 2015 0;
BA_ "GenMsgDelayTime" BO_ 125 10;
BA_ "GenMsgCycleTime" BO_ 125 20;
BA_ "GenMsgSendType" BO_ 125 0;
BA_ "GenMsgDelayTime" BO_ 119 10;
BA_ "GenMsgCycleTime" BO_ 119 20;
BA_ "GenMsgSendType" BO_ 119 0;
BA_ "GenMsgCycleTime" BO_ 118 500;
BA_ "GenMsgSendType" BO_ 118 5;
BA_ "NetworkInitialization" BO_ 1713 0;
BA_ "GenMsgDelayTime" BO_ 1713 10;
BA_ "GenMsgSendType" BO_ 1713 1;
BA_ "TpApplType" BO_ 1713 "DiagUUDTResponse";
BA_ "GenMsgILSupport" BO_ 1713 0;
BA_ "NetworkInitialization" BO_ 1712 0;
BA_ "GenMsgDelayTime" BO_ 1712 10;
BA_ "GenMsgSendType" BO_ 1712 1;
BA_ "TpApplType" BO_ 1712 "DiagUUDTResponse";
BA_ "GenMsgILSupport" BO_ 1712 0;
BA_ "GenMsgDelayTime" BO_ 75 10;
BA_ "GenMsgCycleTime" BO_ 75 100;
BA_ "GenMsgSendType" BO_ 75 5;
BA_ "GenMsgDelayTime" BO_ 74 10;
BA_ "GenMsgCycleTime" BO_ 74 100;
BA_ "GenMsgSendType" BO_ 74 5;
BA_ "U_CX482_CX483_MY20_Hev_Rx" SG_ 963 ImpactEvntFdbck_D_Stat 1;
BA_ "U_CX482_CX483_MY20_Gas_Rx" SG_ 963 ImpactEvntFdbck_D_Stat 1;
BA_ "U_CX482_CX483_MY20_Diesel_Rx" SG_ 963 ImpactEvntFdbck_D_Stat 1;
BA_ "U_U611_U625_MY20_Hev_Rx" SG_ 963 ImpactEvntFdbck_D_Stat 1;
BA_ "U_U611_U625_MY20_Gas_Rx" SG_ 963 ImpactEvntFdbck_D_Stat 1;
BA_ "U_U611_U625_MY20_Diesel_Rx" SG_ 963 ImpactEvntFdbck_D_Stat 1;
BA_ "U_B500_MY18_Diesel_Rx" SG_ 963 ImpactEvntFdbck_D_Stat 1;
BA_ "U_B500_MY18_Gas_Rx" SG_ 963 ImpactEvntFdbck_D_Stat 1;
BA_ "U_C490_MY18_Rx" SG_ 963 ImpactEvntFdbck_D_Stat 1;
BA_ "U_B562_MY18_Gas_Rx" SG_ 963 ImpactEvntFdbck_D_Stat 1;
BA_ "U_C519_MY18_5_Gas_Rx" SG_ 963 ImpactEvntFdbck_D_Stat 1;
BA_ "U_C519_MY18_5_Diesel_Rx" SG_ 963 ImpactEvntFdbck_D_Stat 1;
BA_ "U_B515_MCA_MY17_Gas_Rx" SG_ 963 ImpactEvntFdbck_D_Stat 1;
BA_ "U_B515_MCA_MY17_Diesel_Rx" SG_ 963 ImpactEvntFdbck_D_Stat 1;
BA_ "U_B479_MY17_Diesel_Rx" SG_ 963 ImpactEvntFdbck_D_Stat 1;
BA_ "U_B479_MY17_Gas_Rx" SG_ 963 ImpactEvntFdbck_D_Stat 1;
BA_ "CrossOver_InfoCAN" SG_ 963 ImpactEvntFdbck_D_Stat 1;
BA_ "WakeupSignal" SG_ 963 ImpactEvntFdbck_D_Stat 1;
BA_ "CrossOver_InfoCAN" SG_ 963 HeadLampLoOut_B_Stat 1;
BA_ "U_CX482_CX483_MY20_Hev_Rx" SG_ 963 CrnrLghtRight_Pc_Rq 1;
BA_ "U_CX482_CX483_MY20_Gas_Rx" SG_ 963 CrnrLghtRight_Pc_Rq 1;
BA_ "U_CX482_CX483_MY20_Diesel_Rx" SG_ 963 CrnrLghtRight_Pc_Rq 1;
BA_ "U_C519_MY18_5_Gas_Rx" SG_ 963 CrnrLghtRight_Pc_Rq 1;
BA_ "U_C519_MY18_5_Diesel_Rx" SG_ 963 CrnrLghtRight_Pc_Rq 1;
BA_ "CrossOver_InfoCAN" SG_ 963 CrnrLghtRight_Pc_Rq 1;
BA_ "U_CX482_CX483_MY20_Hev_Rx" SG_ 963 CrnrLghtLeft_Pc_Rq 1;
BA_ "U_CX482_CX483_MY20_Gas_Rx" SG_ 963 CrnrLghtLeft_Pc_Rq 1;
BA_ "U_CX482_CX483_MY20_Diesel_Rx" SG_ 963 CrnrLghtLeft_Pc_Rq 1;
BA_ "U_C519_MY18_5_Gas_Rx" SG_ 963 CrnrLghtLeft_Pc_Rq 1;
BA_ "U_C519_MY18_5_Diesel_Rx" SG_ 963 CrnrLghtLeft_Pc_Rq 1;
BA_ "CrossOver_InfoCAN" SG_ 963 CrnrLghtLeft_Pc_Rq 1;
BA_ "U_U611_U625_MY20_Phev_Rx" SG_ 963 HeadLghtHiFdbck_D_Stat 1;
BA_ "U_CX482_CX483_MY20_Hev_Rx" SG_ 963 HeadLghtHiFdbck_D_Stat 1;
BA_ "U_CX482_CX483_MY20_Gas_Rx" SG_ 963 HeadLghtHiFdbck_D_Stat 1;
BA_ "U_CX482_CX483_MY20_Diesel_Rx" SG_ 963 HeadLghtHiFdbck_D_Stat 1;
BA_ "U_U611_U625_MY20_Hev_Rx" SG_ 963 HeadLghtHiFdbck_D_Stat 1;
BA_ "U_U611_U625_MY20_Gas_Rx" SG_ 963 HeadLghtHiFdbck_D_Stat 1;
BA_ "U_U611_U625_MY20_Diesel_Rx" SG_ 963 HeadLghtHiFdbck_D_Stat 1;
BA_ "U_B500_MY18_Diesel_Rx" SG_ 963 HeadLghtHiFdbck_D_Stat 1;
BA_ "U_B500_MY18_Gas_Rx" SG_ 963 HeadLghtHiFdbck_D_Stat 1;
BA_ "U_C519_MY18_5_Gas_Rx" SG_ 963 HeadLghtHiFdbck_D_Stat 1;
BA_ "U_C519_MY18_5_Diesel_Rx" SG_ 963 HeadLghtHiFdbck_D_Stat 1;
BA_ "U_B515_MCA_MY17_Gas_Rx" SG_ 963 HeadLghtHiFdbck_D_Stat 1;
BA_ "U_B515_MCA_MY17_Diesel_Rx" SG_ 963 HeadLghtHiFdbck_D_Stat 1;
BA_ "U_B479_MY17_Diesel_Rx" SG_ 963 HeadLghtHiFdbck_D_Stat 1;
BA_ "U_B479_MY17_Gas_Rx" SG_ 963 HeadLghtHiFdbck_D_Stat 1;
BA_ "CrossOver_InfoCAN" SG_ 963 HeadLghtHiFdbck_D_Stat 1;
BA_ "CrossOver_InfoCAN" SG_ 963 PrkLightChime_B_Rq 1;
BA_ "CrossOver_InfoCAN" SG_ 963 TrnNotInPrkChime_B_Rq 1;
BA_ "CrossOver_InfoCAN" SG_ 963 KeyInIgnWarn_B_Cmd 1;
BA_ "WakeupSignal" SG_ 963 KeyInIgnWarn_B_Cmd 1;
BA_ "CrossOver_InfoCAN" SG_ 963 HomeSafeLtChime_B_Rq 1;
BA_ "WakeupSignal" SG_ 963 HomeSafeLtChime_B_Rq 1;
BA_ "U_CX482_CX483_MY20_Hev_Rx" SG_ 963 StopLghtOn_B_Stat 1;
BA_ "U_CX482_CX483_MY20_Gas_Rx" SG_ 963 StopLghtOn_B_Stat 1;
BA_ "U_CX482_CX483_MY20_Diesel_Rx" SG_ 963 StopLghtOn_B_Stat 1;
BA_ "U_U611_U625_MY20_Hev_Rx" SG_ 963 StopLghtOn_B_Stat 1;
BA_ "U_U611_U625_MY20_Gas_Rx" SG_ 963 StopLghtOn_B_Stat 1;
BA_ "U_U611_U625_MY20_Diesel_Rx" SG_ 963 StopLghtOn_B_Stat 1;
BA_ "U_C519_MY18_5_Gas_Rx" SG_ 963 StopLghtOn_B_Stat 1;
BA_ "U_C519_MY18_5_Diesel_Rx" SG_ 963 StopLghtOn_B_Stat 1;
BA_ "U_B515_MCA_MY17_Gas_Rx" SG_ 963 StopLghtOn_B_Stat 1;
BA_ "U_B515_MCA_MY17_Diesel_Rx" SG_ 963 StopLghtOn_B_Stat 1;
BA_ "U_B479_MY17_Diesel_Rx" SG_ 963 StopLghtOn_B_Stat 1;
BA_ "U_B479_MY17_Gas_Rx" SG_ 963 StopLghtOn_B_Stat 1;
BA_ "CrossOver_InfoCAN" SG_ 963 StopLghtOn_B_Stat 1;
BA_ "WakeupSignal" SG_ 963 StopLghtOn_B_Stat 1;
BA_ "CrossOver_InfoCAN" SG_ 963 RvrseLghtOn_B_Stat 1;
BA_ "CrossOver_InfoCAN" SG_ 963 PrkLght_D_Stat 1;
BA_ "WakeupSignal" SG_ 963 PrkLght_D_Stat 1;
BA_ "U_CX482_CX483_MY20_Hev_Rx" SG_ 963 HeadLghtSwtch_D_Stat 1;
BA_ "U_CX482_CX483_MY20_Gas_Rx" SG_ 963 HeadLghtSwtch_D_Stat 1;
BA_ "U_CX482_CX483_MY20_Diesel_Rx" SG_ 963 HeadLghtSwtch_D_Stat 1;
BA_ "U_U611_U625_MY20_Hev_Rx" SG_ 963 HeadLghtSwtch_D_Stat 1;
BA_ "U_U611_U625_MY20_Gas_Rx" SG_ 963 HeadLghtSwtch_D_Stat 1;
BA_ "U_U611_U625_MY20_Diesel_Rx" SG_ 963 HeadLghtSwtch_D_Stat 1;
BA_ "U_C519_MY18_5_Gas_Rx" SG_ 963 HeadLghtSwtch_D_Stat 1;
BA_ "U_C519_MY18_5_Diesel_Rx" SG_ 963 HeadLghtSwtch_D_Stat 1;
BA_ "U_B479_MY17_Diesel_Rx" SG_ 963 HeadLghtSwtch_D_Stat 1;
BA_ "U_B479_MY17_Gas_Rx" SG_ 963 HeadLghtSwtch_D_Stat 1;
BA_ "GenSigStartValue" SG_ 963 HeadLghtSwtch_D_Stat 2;
BA_ "CrossOver_InfoCAN" SG_ 963 HeadLghtSwtch_D_Stat 1;
BA_ "WakeupSignal" SG_ 963 HeadLghtSwtch_D_Stat 1;
BA_ "U_U611_U625_MY20_Phev_Rx" SG_ 963 HeadLampLoFrOn_B_Stat 1;
BA_ "U_CX482_CX483_MY20_Hev_Rx" SG_ 963 HeadLampLoFrOn_B_Stat 1;
BA_ "U_CX482_CX483_MY20_Gas_Rx" SG_ 963 HeadLampLoFrOn_B_Stat 1;
BA_ "U_CX482_CX483_MY20_Diesel_Rx" SG_ 963 HeadLampLoFrOn_B_Stat 1;
BA_ "U_U611_U625_MY20_Hev_Rx" SG_ 963 HeadLampLoFrOn_B_Stat 1;
BA_ "U_U611_U625_MY20_Gas_Rx" SG_ 963 HeadLampLoFrOn_B_Stat 1;
BA_ "U_U611_U625_MY20_Diesel_Rx" SG_ 963 HeadLampLoFrOn_B_Stat 1;
BA_ "U_B500_MY18_Diesel_Rx" SG_ 963 HeadLampLoFrOn_B_Stat 1;
BA_ "U_B500_MY18_Gas_Rx" SG_ 963 HeadLampLoFrOn_B_Stat 1;
BA_ "U_C519_MY18_5_Gas_Rx" SG_ 963 HeadLampLoFrOn_B_Stat 1;
BA_ "U_C519_MY18_5_Diesel_Rx" SG_ 963 HeadLampLoFrOn_B_Stat 1;
BA_ "U_B515_MCA_MY17_Gas_Rx" SG_ 963 HeadLampLoFrOn_B_Stat 1;
BA_ "U_B515_MCA_MY17_Diesel_Rx" SG_ 963 HeadLampLoFrOn_B_Stat 1;
BA_ "U_B479_MY17_Diesel_Rx" SG_ 963 HeadLampLoFrOn_B_Stat 1;
BA_ "U_B479_MY17_Gas_Rx" SG_ 963 HeadLampLoFrOn_B_Stat 1;
BA_ "GenSigStartValue" SG_ 963 HeadLampLoFrOn_B_Stat 1;
BA_ "CrossOver_InfoCAN" SG_ 963 HeadLampLoFrOn_B_Stat 1;
BA_ "U_U611_U625_MY20_Phev_Rx" SG_ 963 HeadLampLoFlOn_B_Stat 1;
BA_ "U_CX482_CX483_MY20_Hev_Rx" SG_ 963 HeadLampLoFlOn_B_Stat 1;
BA_ "U_CX482_CX483_MY20_Gas_Rx" SG_ 963 HeadLampLoFlOn_B_Stat 1;
BA_ "U_CX482_CX483_MY20_Diesel_Rx" SG_ 963 HeadLampLoFlOn_B_Stat 1;
BA_ "U_U611_U625_MY20_Hev_Rx" SG_ 963 HeadLampLoFlOn_B_Stat 1;
BA_ "U_U611_U625_MY20_Gas_Rx" SG_ 963 HeadLampLoFlOn_B_Stat 1;
BA_ "U_U611_U625_MY20_Diesel_Rx" SG_ 963 HeadLampLoFlOn_B_Stat 1;
BA_ "U_B500_MY18_Diesel_Rx" SG_ 963 HeadLampLoFlOn_B_Stat 1;
BA_ "U_B500_MY18_Gas_Rx" SG_ 963 HeadLampLoFlOn_B_Stat 1;
BA_ "U_C519_MY18_5_Gas_Rx" SG_ 963 HeadLampLoFlOn_B_Stat 1;
BA_ "U_C519_MY18_5_Diesel_Rx" SG_ 963 HeadLampLoFlOn_B_Stat 1;
BA_ "U_B515_MCA_MY17_Gas_Rx" SG_ 963 HeadLampLoFlOn_B_Stat 1;
BA_ "U_B515_MCA_MY17_Diesel_Rx" SG_ 963 HeadLampLoFlOn_B_Stat 1;
BA_ "U_B479_MY17_Diesel_Rx" SG_ 963 HeadLampLoFlOn_B_Stat 1;
BA_ "U_B479_MY17_Gas_Rx" SG_ 963 HeadLampLoFlOn_B_Stat 1;
BA_ "GenSigStartValue" SG_ 963 HeadLampLoFlOn_B_Stat 1;
BA_ "CrossOver_InfoCAN" SG_ 963 HeadLampLoFlOn_B_Stat 1;
BA_ "U_CX482_CX483_MY20_Hev_Rx" SG_ 963 HeadLampLoActv_B_Stat 1;
BA_ "U_CX482_CX483_MY20_Gas_Rx" SG_ 963 HeadLampLoActv_B_Stat 1;
BA_ "U_CX482_CX483_MY20_Diesel_Rx" SG_ 963 HeadLampLoActv_B_Stat 1;
BA_ "U_U611_U625_MY20_Hev_Rx" SG_ 963 HeadLampLoActv_B_Stat 1;
BA_ "U_U611_U625_MY20_Gas_Rx" SG_ 963 HeadLampLoActv_B_Stat 1;
BA_ "U_U611_U625_MY20_Diesel_Rx" SG_ 963 HeadLampLoActv_B_Stat 1;
BA_ "U_C519_MY18_5_Gas_Rx" SG_ 963 HeadLampLoActv_B_Stat 1;
BA_ "U_C519_MY18_5_Diesel_Rx" SG_ 963 HeadLampLoActv_B_Stat 1;
BA_ "U_B479_MY17_Diesel_Rx" SG_ 963 HeadLampLoActv_B_Stat 1;
BA_ "U_B479_MY17_Gas_Rx" SG_ 963 HeadLampLoActv_B_Stat 1;
BA_ "GenSigStartValue" SG_ 963 HeadLampLoActv_B_Stat 1;
BA_ "CrossOver_InfoCAN" SG_ 963 HeadLampLoActv_B_Stat 1;
BA_ "CrossOver_InfoCAN" SG_ 963 Headlamp_On_Wrning_Cmd 1;
BA_ "WakeupSignal" SG_ 963 Headlamp_On_Wrning_Cmd 1;
BA_ "U_CX482_CX483_MY20_Hev_Rx" SG_ 963 HeadLghtHiOn_B_Stat 1;
BA_ "U_CX482_CX483_MY20_Gas_Rx" SG_ 963 HeadLghtHiOn_B_Stat 1;
BA_ "U_CX482_CX483_MY20_Diesel_Rx" SG_ 963 HeadLghtHiOn_B_Stat 1;
BA_ "U_U611_U625_MY20_Hev_Rx" SG_ 963 HeadLghtHiOn_B_Stat 1;
BA_ "U_U611_U625_MY20_Gas_Rx" SG_ 963 HeadLghtHiOn_B_Stat 1;
BA_ "U_U611_U625_MY20_Diesel_Rx" SG_ 963 HeadLghtHiOn_B_Stat 1;
BA_ "U_C519_MY18_5_Gas_Rx" SG_ 963 HeadLghtHiOn_B_Stat 1;
BA_ "U_C519_MY18_5_Diesel_Rx" SG_ 963 HeadLghtHiOn_B_Stat 1;
BA_ "U_B479_MY17_Diesel_Rx" SG_ 963 HeadLghtHiOn_B_Stat 1;
BA_ "U_B479_MY17_Gas_Rx" SG_ 963 HeadLghtHiOn_B_Stat 1;
BA_ "CrossOver_InfoCAN" SG_ 963 HeadLghtHiOn_B_Stat 1;
BA_ "WakeupSignal" SG_ 963 HeadLghtHiOn_B_Stat 1;
BA_ "CrossOver_InfoCAN" SG_ 963 Park_Brake_Chime_Rqst 1;
BA_ "CrossOver_InfoCAN" SG_ 963 BrkWarnInd_B_Rq 1;
BA_ "WakeupSignal" SG_ 963 BrkWarnInd_B_Rq 1;
BA_ "CrossOver_InfoCAN" SG_ 963 Brk_Fluid_Lvl_Low 1;
BA_ "CrossOver_InfoCAN" SG_ 963 ReducedGuard_D_Stat 1;
BA_ "CrossOver_InfoCAN" SG_ 963 Perimeter_Alarm_Status 1;
BA_ "WakeupSignal" SG_ 963 Perimeter_Alarm_Status 1;
BA_ "GenSigStartValue" SG_ 963 Courtesy_BSave_Stat 1;
BA_ "CrossOver_InfoCAN" SG_ 963 Courtesy_BSave_Stat 1;
BA_ "WakeupSignal" SG_ 963 Courtesy_BSave_Stat 1;
BA_ "U_CX482_CX483_MY20_Hev_Rx" SG_ 963 DayRnngLampOn_B_Stat 1;
BA_ "U_CX482_CX483_MY20_Gas_Rx" SG_ 963 DayRnngLampOn_B_Stat 1;
BA_ "U_CX482_CX483_MY20_Diesel_Rx" SG_ 963 DayRnngLampOn_B_Stat 1;
BA_ "U_C519_MY18_5_Gas_Rx" SG_ 963 DayRnngLampOn_B_Stat 1;
BA_ "U_C519_MY18_5_Diesel_Rx" SG_ 963 DayRnngLampOn_B_Stat 1;
BA_ "CrossOver_InfoCAN" SG_ 963 DayRnngLampOn_B_Stat 1;
BA_ "CrossOver_InfoCAN" SG_ 963 WndwGlbl_D_Cmd 1;
BA_ "WakeupSignal" SG_ 963 WndwGlbl_D_Cmd 1;
BA_ "CrossOver_InfoCAN" SG_ 963 PudLamp_D_Rq 1;
BA_ "WakeupSignal" SG_ 963 PudLamp_D_Rq 1;
BA_ "CrossOver_InfoCAN" SG_ 963 PerimeterAlarmChimeRq 1;
BA_ "WakeupSignal" SG_ 963 PerimeterAlarmChimeRq 1;
BA_ "U_U611_U625_MY20_Phev_Tx" SG_ 972 LsmcBrkDecelEnbl_D_Rq 1;
BA_ "U_U611_U625_MY20_Hev_Tx" SG_ 972 LsmcBrkDecelEnbl_D_Rq 1;
BA_ "U_U611_U625_MY20_Gas_Tx" SG_ 972 LsmcBrkDecelEnbl_D_Rq 1;
BA_ "U_U611_U625_MY20_Diesel_Tx" SG_ 972 LsmcBrkDecelEnbl_D_Rq 1;
BA_ "U_U611_U625_MY20_Hev_Rx" SG_ 972 LsmcBrkDecelEnbl_D_Rq 1;
BA_ "U_U611_U625_MY20_Gas_Rx" SG_ 972 LsmcBrkDecelEnbl_D_Rq 1;
BA_ "U_U611_U625_MY20_Diesel_Rx" SG_ 972 LsmcBrkDecelEnbl_D_Rq 1;
BA_ "U_U611_U625_MY20_Phev_Tx" SG_ 972 TjaHandsOnCnfdnc_B_Est 1;
BA_ "U_CX482_CX483_MY20_Hev_Tx" SG_ 972 TjaHandsOnCnfdnc_B_Est 1;
BA_ "U_CX482_CX483_MY20_Gas_Tx" SG_ 972 TjaHandsOnCnfdnc_B_Est 1;
BA_ "U_CX482_CX483_MY20_Diesel_Tx" SG_ 972 TjaHandsOnCnfdnc_B_Est 1;
BA_ "U_U611_U625_MY20_Hev_Tx" SG_ 972 TjaHandsOnCnfdnc_B_Est 1;
BA_ "U_U611_U625_MY20_Gas_Tx" SG_ 972 TjaHandsOnCnfdnc_B_Est 1;
BA_ "U_U611_U625_MY20_Diesel_Tx" SG_ 972 TjaHandsOnCnfdnc_B_Est 1;
BA_ "U_C519_MY18_5_Gas_Tx" SG_ 972 TjaHandsOnCnfdnc_B_Est 1;
BA_ "U_C519_MY18_5_Diesel_Tx" SG_ 972 TjaHandsOnCnfdnc_B_Est 1;
BA_ "U_CX482_CX483_MY20_Hev_Rx" SG_ 972 TjaHandsOnCnfdnc_B_Est 1;
BA_ "U_CX482_CX483_MY20_Gas_Rx" SG_ 972 TjaHandsOnCnfdnc_B_Est 1;
BA_ "U_CX482_CX483_MY20_Diesel_Rx" SG_ 972 TjaHandsOnCnfdnc_B_Est 1;
BA_ "U_U611_U625_MY20_Hev_Rx" SG_ 972 TjaHandsOnCnfdnc_B_Est 1;
BA_ "U_U611_U625_MY20_Gas_Rx" SG_ 972 TjaHandsOnCnfdnc_B_Est 1;
BA_ "U_U611_U625_MY20_Diesel_Rx" SG_ 972 TjaHandsOnCnfdnc_B_Est 1;
BA_ "U_C519_MY18_5_Gas_Rx" SG_ 972 TjaHandsOnCnfdnc_B_Est 1;
BA_ "U_C519_MY18_5_Diesel_Rx" SG_ 972 TjaHandsOnCnfdnc_B_Est 1;
BA_ "GenSigStartValue" SG_ 972 TjaHandsOnCnfdnc_B_Est 1;
BA_ "U_U611_U625_MY20_Phev_Tx" SG_ 972 LsmcBrkDecel_A_Rq 1;
BA_ "U_U611_U625_MY20_Hev_Tx" SG_ 972 LsmcBrkDecel_A_Rq 1;
BA_ "U_U611_U625_MY20_Gas_Tx" SG_ 972 LsmcBrkDecel_A_Rq 1;
BA_ "U_U611_U625_MY20_Diesel_Tx" SG_ 972 LsmcBrkDecel_A_Rq 1;
BA_ "U_U611_U625_MY20_Hev_Rx" SG_ 972 LsmcBrkDecel_A_Rq 1;
BA_ "U_U611_U625_MY20_Gas_Rx" SG_ 972 LsmcBrkDecel_A_Rq 1;
BA_ "U_U611_U625_MY20_Diesel_Rx" SG_ 972 LsmcBrkDecel_A_Rq 1;
BA_ "U_U611_U625_MY20_Phev_Tx" SG_ 972 LaHandsOff_B_Actl 1;
BA_ "U_CX482_CX483_MY20_Hev_Tx" SG_ 972 LaHandsOff_B_Actl 1;
BA_ "U_CX482_CX483_MY20_Gas_Tx" SG_ 972 LaHandsOff_B_Actl 1;
BA_ "U_CX482_CX483_MY20_Diesel_Tx" SG_ 972 LaHandsOff_B_Actl 1;
BA_ "U_U611_U625_MY20_Hev_Tx" SG_ 972 LaHandsOff_B_Actl 1;
BA_ "U_U611_U625_MY20_Gas_Tx" SG_ 972 LaHandsOff_B_Actl 1;
BA_ "U_U611_U625_MY20_Diesel_Tx" SG_ 972 LaHandsOff_B_Actl 1;
BA_ "U_B500_MY18_Diesel_Tx" SG_ 972 LaHandsOff_B_Actl 1;
BA_ "U_B500_MY18_Gas_Tx" SG_ 972 LaHandsOff_B_Actl 1;
BA_ "U_C519_MY18_5_Gas_Tx" SG_ 972 LaHandsOff_B_Actl 1;
BA_ "U_C519_MY18_5_Diesel_Tx" SG_ 972 LaHandsOff_B_Actl 1;
BA_ "U_B479_MY17_Diesel_Tx" SG_ 972 LaHandsOff_B_Actl 1;
BA_ "U_B479_MY17_Gas_Tx" SG_ 972 LaHandsOff_B_Actl 1;
BA_ "U_CX482_CX483_MY20_Hev_Rx" SG_ 972 LaHandsOff_B_Actl 1;
BA_ "U_CX482_CX483_MY20_Gas_Rx" SG_ 972 LaHandsOff_B_Actl 1;
BA_ "U_CX482_CX483_MY20_Diesel_Rx" SG_ 972 LaHandsOff_B_Actl 1;
BA_ "U_U611_U625_MY20_Hev_Rx" SG_ 972 LaHandsOff_B_Actl 1;
BA_ "U_U611_U625_MY20_Gas_Rx" SG_ 972 LaHandsOff_B_Actl 1;
BA_ "U_U611_U625_MY20_Diesel_Rx" SG_ 972 LaHandsOff_B_Actl 1;
BA_ "U_C519_MY18_5_Gas_Rx" SG_ 972 LaHandsOff_B_Actl 1;
BA_ "U_C519_MY18_5_Diesel_Rx" SG_ 972 LaHandsOff_B_Actl 1;
BA_ "U_B479_MY17_Diesel_Rx" SG_ 972 LaHandsOff_B_Actl 1;
BA_ "U_B479_MY17_Gas_Rx" SG_ 972 LaHandsOff_B_Actl 1;
BA_ "GenSigStartValue" SG_ 972 LaHandsOff_B_Actl 1;
BA_ "CrossOver_InfoCAN" SG_ 972 LaHandsOff_B_Actl 1;
BA_ "U_U611_U625_MY20_Phev_Tx" SG_ 972 LaActDeny_B_Actl 1;
BA_ "U_CX482_CX483_MY20_Hev_Tx" SG_ 972 LaActDeny_B_Actl 1;
BA_ "U_CX482_CX483_MY20_Gas_Tx" SG_ 972 LaActDeny_B_Actl 1;
BA_ "U_CX482_CX483_MY20_Diesel_Tx" SG_ 972 LaActDeny_B_Actl 1;
BA_ "U_U611_U625_MY20_Hev_Tx" SG_ 972 LaActDeny_B_Actl 1;
BA_ "U_U611_U625_MY20_Gas_Tx" SG_ 972 LaActDeny_B_Actl 1;
BA_ "U_U611_U625_MY20_Diesel_Tx" SG_ 972 LaActDeny_B_Actl 1;
BA_ "U_B500_MY18_Diesel_Tx" SG_ 972 LaActDeny_B_Actl 1;
BA_ "U_B500_MY18_Gas_Tx" SG_ 972 LaActDeny_B_Actl 1;
BA_ "U_C519_MY18_5_Gas_Tx" SG_ 972 LaActDeny_B_Actl 1;
BA_ "U_C519_MY18_5_Diesel_Tx" SG_ 972 LaActDeny_B_Actl 1;
BA_ "U_B479_MY17_Diesel_Tx" SG_ 972 LaActDeny_B_Actl 1;
BA_ "U_B479_MY17_Gas_Tx" SG_ 972 LaActDeny_B_Actl 1;
BA_ "U_CX482_CX483_MY20_Hev_Rx" SG_ 972 LaActDeny_B_Actl 1;
BA_ "U_CX482_CX483_MY20_Gas_Rx" SG_ 972 LaActDeny_B_Actl 1;
BA_ "U_CX482_CX483_MY20_Diesel_Rx" SG_ 972 LaActDeny_B_Actl 1;
BA_ "U_U611_U625_MY20_Hev_Rx" SG_ 972 LaActDeny_B_Actl 1;
BA_ "U_U611_U625_MY20_Gas_Rx" SG_ 972 LaActDeny_B_Actl 1;
BA_ "U_U611_U625_MY20_Diesel_Rx" SG_ 972 LaActDeny_B_Actl 1;
BA_ "U_C519_MY18_5_Gas_Rx" SG_ 972 LaActDeny_B_Actl 1;
BA_ "U_C519_MY18_5_Diesel_Rx" SG_ 972 LaActDeny_B_Actl 1;
BA_ "U_B479_MY17_Diesel_Rx" SG_ 972 LaActDeny_B_Actl 1;
BA_ "U_B479_MY17_Gas_Rx" SG_ 972 LaActDeny_B_Actl 1;
BA_ "CrossOver_InfoCAN" SG_ 972 LaActDeny_B_Actl 1;
BA_ "U_U611_U625_MY20_Phev_Tx" SG_ 972 LaActAvail_D_Actl 1;
BA_ "U_CX482_CX483_MY20_Hev_Tx" SG_ 972 LaActAvail_D_Actl 1;
BA_ "U_CX482_CX483_MY20_Gas_Tx" SG_ 972 LaActAvail_D_Actl 1;
BA_ "U_CX482_CX483_MY20_Diesel_Tx" SG_ 972 LaActAvail_D_Actl 1;
BA_ "U_U611_U625_MY20_Hev_Tx" SG_ 972 LaActAvail_D_Actl 1;
BA_ "U_U611_U625_MY20_Gas_Tx" SG_ 972 LaActAvail_D_Actl 1;
BA_ "U_U611_U625_MY20_Diesel_Tx" SG_ 972 LaActAvail_D_Actl 1;
BA_ "U_B500_MY18_Diesel_Tx" SG_ 972 LaActAvail_D_Actl 1;
BA_ "U_B500_MY18_Gas_Tx" SG_ 972 LaActAvail_D_Actl 1;
BA_ "U_C519_MY18_5_Gas_Tx" SG_ 972 LaActAvail_D_Actl 1;
BA_ "U_C519_MY18_5_Diesel_Tx" SG_ 972 LaActAvail_D_Actl 1;
BA_ "U_B479_MY17_Diesel_Tx" SG_ 972 LaActAvail_D_Actl 1;
BA_ "U_B479_MY17_Gas_Tx" SG_ 972 LaActAvail_D_Actl 1;
BA_ "U_CX482_CX483_MY20_Hev_Rx" SG_ 972 LaActAvail_D_Actl 1;
BA_ "U_CX482_CX483_MY20_Gas_Rx" SG_ 972 LaActAvail_D_Actl 1;
BA_ "U_CX482_CX483_MY20_Diesel_Rx" SG_ 972 LaActAvail_D_Actl 1;
BA_ "U_U611_U625_MY20_Hev_Rx" SG_ 972 LaActAvail_D_Actl 1;
BA_ "U_U611_U625_MY20_Gas_Rx" SG_ 972 LaActAvail_D_Actl 1;
BA_ "U_U611_U625_MY20_Diesel_Rx" SG_ 972 LaActAvail_D_Actl 1;
BA_ "U_C519_MY18_5_Gas_Rx" SG_ 972 LaActAvail_D_Actl 1;
BA_ "U_C519_MY18_5_Diesel_Rx" SG_ 972 LaActAvail_D_Actl 1;
BA_ "U_B479_MY17_Diesel_Rx" SG_ 972 LaActAvail_D_Actl 1;
BA_ "U_B479_MY17_Gas_Rx" SG_ 972 LaActAvail_D_Actl 1;
BA_ "CrossOver_InfoCAN" SG_ 972 LaActAvail_D_Actl 1;
BA_ "U_U611_U625_MY20_Hev_Tx" SG_ 991 PersIndexVdm_D_Actl 1;
BA_ "U_U611_U625_MY20_Gas_Tx" SG_ 991 PersIndexVdm_D_Actl 1;
BA_ "U_U611_U625_MY20_Diesel_Tx" SG_ 991 PersIndexVdm_D_Actl 1;
BA_ "GenSigSendType" SG_ 991 PersIndexVdm_D_Actl 3;
BA_ "GenSigStartValue" SG_ 991 PersIndexVdm_D_Actl 4;
BA_ "CrossOver_InfoCAN" SG_ 991 PersIndexVdm_D_Actl 1;
BA_ "U_U611_U625_MY20_Hev_Tx" SG_ 991 FeatNoVdmActl 1;
BA_ "U_U611_U625_MY20_Gas_Tx" SG_ 991 FeatNoVdmActl 1;
BA_ "U_U611_U625_MY20_Diesel_Tx" SG_ 991 FeatNoVdmActl 1;
BA_ "GenSigSendType" SG_ 991 FeatNoVdmActl 3;
BA_ "CrossOver_InfoCAN" SG_ 991 FeatNoVdmActl 1;
BA_ "U_U611_U625_MY20_Hev_Tx" SG_ 991 FeatConfigVdmActl 1;
BA_ "U_U611_U625_MY20_Gas_Tx" SG_ 991 FeatConfigVdmActl 1;
BA_ "U_U611_U625_MY20_Diesel_Tx" SG_ 991 FeatConfigVdmActl 1;
BA_ "GenSigSendType" SG_ 991 FeatConfigVdmActl 3;
BA_ "CrossOver_InfoCAN" SG_ 991 FeatConfigVdmActl 1;
BA_ "U_U611_U625_MY20_Phev_Tx" SG_ 1459 SCCM_GWOnBoardTester 1;
BA_ "U_U611_U625_MY20_Hev_Tx" SG_ 1459 SCCM_GWOnBoardTester 1;
BA_ "U_U611_U625_MY20_Gas_Tx" SG_ 1459 SCCM_GWOnBoardTester 1;
BA_ "U_U611_U625_MY20_Diesel_Tx" SG_ 1459 SCCM_GWOnBoardTester 1;
BA_ "U_B500_MY18_Diesel_Tx" SG_ 1459 SCCM_GWOnBoardTester 1;
BA_ "U_B500_MY18_Gas_Tx" SG_ 1459 SCCM_GWOnBoardTester 1;
BA_ "ContentDependant" SG_ 1459 SCCM_GWOnBoardTester 1;
BA_ "GenSigStartValue" SG_ 1459 SCCM_GWOnBoardTester 255;
BA_ "U_U611_U625_MY20_Phev_Tx" SG_ 1459 SCCM_GWNMProxy 1;
BA_ "U_U611_U625_MY20_Hev_Tx" SG_ 1459 SCCM_GWNMProxy 1;
BA_ "U_U611_U625_MY20_Gas_Tx" SG_ 1459 SCCM_GWNMProxy 1;
BA_ "U_U611_U625_MY20_Diesel_Tx" SG_ 1459 SCCM_GWNMProxy 1;
BA_ "U_B500_MY18_Diesel_Tx" SG_ 1459 SCCM_GWNMProxy 1;
BA_ "U_B500_MY18_Gas_Tx" SG_ 1459 SCCM_GWNMProxy 1;
BA_ "ContentDependant" SG_ 1459 SCCM_GWNMProxy 1;
BA_ "GenSigStartValue" SG_ 1459 SCCM_GWNMProxy 255;
BA_ "U_U611_U625_MY20_Phev_Tx" SG_ 1459 SCCM_AutoSarNMReserved4 1;
BA_ "U_U611_U625_MY20_Hev_Tx" SG_ 1459 SCCM_AutoSarNMReserved4 1;
BA_ "U_U611_U625_MY20_Gas_Tx" SG_ 1459 SCCM_AutoSarNMReserved4 1;
BA_ "U_U611_U625_MY20_Diesel_Tx" SG_ 1459 SCCM_AutoSarNMReserved4 1;
BA_ "U_B500_MY18_Diesel_Tx" SG_ 1459 SCCM_AutoSarNMReserved4 1;
BA_ "U_B500_MY18_Gas_Tx" SG_ 1459 SCCM_AutoSarNMReserved4 1;
BA_ "ContentDependant" SG_ 1459 SCCM_AutoSarNMReserved4 1;
BA_ "GenSigStartValue" SG_ 1459 SCCM_AutoSarNMReserved4 255;
BA_ "U_U611_U625_MY20_Phev_Tx" SG_ 1459 SCCM_AutoSarNMReserved3 1;
BA_ "U_U611_U625_MY20_Hev_Tx" SG_ 1459 SCCM_AutoSarNMReserved3 1;
BA_ "U_U611_U625_MY20_Gas_Tx" SG_ 1459 SCCM_AutoSarNMReserved3 1;
BA_ "U_U611_U625_MY20_Diesel_Tx" SG_ 1459 SCCM_AutoSarNMReserved3 1;
BA_ "U_B500_MY18_Diesel_Tx" SG_ 1459 SCCM_AutoSarNMReserved3 1;
BA_ "U_B500_MY18_Gas_Tx" SG_ 1459 SCCM_AutoSarNMReserved3 1;
BA_ "ContentDependant" SG_ 1459 SCCM_AutoSarNMReserved3 1;
BA_ "GenSigStartValue" SG_ 1459 SCCM_AutoSarNMReserved3 255;
BA_ "U_U611_U625_MY20_Phev_Tx" SG_ 1459 SCCM_AutoSarNMReserved2 1;
BA_ "U_U611_U625_MY20_Hev_Tx" SG_ 1459 SCCM_AutoSarNMReserved2 1;
BA_ "U_U611_U625_MY20_Gas_Tx" SG_ 1459 SCCM_AutoSarNMReserved2 1;
BA_ "U_U611_U625_MY20_Diesel_Tx" SG_ 1459 SCCM_AutoSarNMReserved2 1;
BA_ "U_B500_MY18_Diesel_Tx" SG_ 1459 SCCM_AutoSarNMReserved2 1;
BA_ "U_B500_MY18_Gas_Tx" SG_ 1459 SCCM_AutoSarNMReserved2 1;
BA_ "ContentDependant" SG_ 1459 SCCM_AutoSarNMReserved2 1;
BA_ "GenSigStartValue" SG_ 1459 SCCM_AutoSarNMReserved2 255;
BA_ "U_U611_U625_MY20_Phev_Tx" SG_ 1459 SCCM_AutoSarNMReserved1 1;
BA_ "U_U611_U625_MY20_Hev_Tx" SG_ 1459 SCCM_AutoSarNMReserved1 1;
BA_ "U_U611_U625_MY20_Gas_Tx" SG_ 1459 SCCM_AutoSarNMReserved1 1;
BA_ "U_U611_U625_MY20_Diesel_Tx" SG_ 1459 SCCM_AutoSarNMReserved1 1;
BA_ "U_B500_MY18_Diesel_Tx" SG_ 1459 SCCM_AutoSarNMReserved1 1;
BA_ "U_B500_MY18_Gas_Tx" SG_ 1459 SCCM_AutoSarNMReserved1 1;
BA_ "ContentDependant" SG_ 1459 SCCM_AutoSarNMReserved1 1;
BA_ "GenSigStartValue" SG_ 1459 SCCM_AutoSarNMReserved1 255;
BA_ "U_U611_U625_MY20_Phev_Tx" SG_ 1459 SCCM_AutoSarNMNodeId 1;
BA_ "U_U611_U625_MY20_Hev_Tx" SG_ 1459 SCCM_AutoSarNMNodeId 1;
BA_ "U_U611_U625_MY20_Gas_Tx" SG_ 1459 SCCM_AutoSarNMNodeId 1;
BA_ "U_U611_U625_MY20_Diesel_Tx" SG_ 1459 SCCM_AutoSarNMNodeId 1;
BA_ "U_B500_MY18_Diesel_Tx" SG_ 1459 SCCM_AutoSarNMNodeId 1;
BA_ "U_B500_MY18_Gas_Tx" SG_ 1459 SCCM_AutoSarNMNodeId 1;
BA_ "ContentDependant" SG_ 1459 SCCM_AutoSarNMNodeId 1;
BA_ "GenSigStartValue" SG_ 1459 SCCM_AutoSarNMNodeId 179;
BA_ "U_U611_U625_MY20_Phev_Tx" SG_ 1459 SCCM_AutoSarNMControl 1;
BA_ "U_U611_U625_MY20_Hev_Tx" SG_ 1459 SCCM_AutoSarNMControl 1;
BA_ "U_U611_U625_MY20_Gas_Tx" SG_ 1459 SCCM_AutoSarNMControl 1;
BA_ "U_U611_U625_MY20_Diesel_Tx" SG_ 1459 SCCM_AutoSarNMControl 1;
BA_ "U_B500_MY18_Diesel_Tx" SG_ 1459 SCCM_AutoSarNMControl 1;
BA_ "U_B500_MY18_Gas_Tx" SG_ 1459 SCCM_AutoSarNMControl 1;
BA_ "ContentDependant" SG_ 1459 SCCM_AutoSarNMControl 1;
BA_ "GenSigStartValue" SG_ 391 CadsRadarStat_D_Qf 1;
BA_ "U_CX482_CX483_MY20_Hev_Tx" SG_ 391 CmbbBrkDecel_No_Cnt 1;
BA_ "U_CX482_CX483_MY20_Gas_Tx" SG_ 391 CmbbBrkDecel_No_Cnt 1;
BA_ "U_CX482_CX483_MY20_Diesel_Tx" SG_ 391 CmbbBrkDecel_No_Cnt 1;
BA_ "U_U611_U625_MY20_Hev_Tx" SG_ 391 CmbbBrkDecel_No_Cnt 1;
BA_ "U_U611_U625_MY20_Gas_Tx" SG_ 391 CmbbBrkDecel_No_Cnt 1;
BA_ "U_U611_U625_MY20_Diesel_Tx" SG_ 391 CmbbBrkDecel_No_Cnt 1;
BA_ "U_C519_MY18_5_Gas_Tx" SG_ 391 CmbbBrkDecel_No_Cnt 1;
BA_ "U_C519_MY18_5_Diesel_Tx" SG_ 391 CmbbBrkDecel_No_Cnt 1;
BA_ "U_B479_MY17_Diesel_Tx" SG_ 391 CmbbBrkDecel_No_Cnt 1;
BA_ "U_B479_MY17_Gas_Tx" SG_ 391 CmbbBrkDecel_No_Cnt 1;
BA_ "U_CX482_CX483_MY20_Hev_Rx" SG_ 391 CmbbBrkDecel_No_Cnt 1;
BA_ "U_CX482_CX483_MY20_Gas_Rx" SG_ 391 CmbbBrkDecel_No_Cnt 1;
BA_ "U_CX482_CX483_MY20_Diesel_Rx" SG_ 391 CmbbBrkDecel_No_Cnt 1;
BA_ "U_U611_U625_MY20_Hev_Rx" SG_ 391 CmbbBrkDecel_No_Cnt 1;
BA_ "U_U611_U625_MY20_Gas_Rx" SG_ 391 CmbbBrkDecel_No_Cnt 1;
BA_ "U_U611_U625_MY20_Diesel_Rx" SG_ 391 CmbbBrkDecel_No_Cnt 1;
BA_ "U_C519_MY18_5_Gas_Rx" SG_ 391 CmbbBrkDecel_No_Cnt 1;
BA_ "U_C519_MY18_5_Diesel_Rx" SG_ 391 CmbbBrkDecel_No_Cnt 1;
BA_ "U_B479_MY17_Diesel_Rx" SG_ 391 CmbbBrkDecel_No_Cnt 1;
BA_ "U_B479_MY17_Gas_Rx" SG_ 391 CmbbBrkDecel_No_Cnt 1;
BA_ "CrossOver_InfoCAN" SG_ 391 CadsAudioMute_D_Rq 1;
BA_ "U_CX482_CX483_MY20_Hev_Tx" SG_ 391 HudDsplyIntns_No_Actl 1;
BA_ "U_CX482_CX483_MY20_Gas_Tx" SG_ 391 HudDsplyIntns_No_Actl 1;
BA_ "U_CX482_CX483_MY20_Diesel_Tx" SG_ 391 HudDsplyIntns_No_Actl 1;
BA_ "U_U611_U625_MY20_Hev_Tx" SG_ 391 HudDsplyIntns_No_Actl 1;
BA_ "U_U611_U625_MY20_Gas_Tx" SG_ 391 HudDsplyIntns_No_Actl 1;
BA_ "U_U611_U625_MY20_Diesel_Tx" SG_ 391 HudDsplyIntns_No_Actl 1;
BA_ "U_C519_MY18_5_Gas_Tx" SG_ 391 HudDsplyIntns_No_Actl 1;
BA_ "U_C519_MY18_5_Diesel_Tx" SG_ 391 HudDsplyIntns_No_Actl 1;
BA_ "U_B479_MY17_Diesel_Tx" SG_ 391 HudDsplyIntns_No_Actl 1;
BA_ "U_B479_MY17_Gas_Tx" SG_ 391 HudDsplyIntns_No_Actl 1;
BA_ "U_U611_U625_MY20_Phev_Rx" SG_ 391 HudDsplyIntns_No_Actl 1;
BA_ "U_U611_U625_MY20_Hev_Rx" SG_ 391 HudDsplyIntns_No_Actl 1;
BA_ "U_U611_U625_MY20_Gas_Rx" SG_ 391 HudDsplyIntns_No_Actl 1;
BA_ "U_U611_U625_MY20_Diesel_Rx" SG_ 391 HudDsplyIntns_No_Actl 1;
BA_ "U_CX482_CX483_MY20_Hev_Tx" SG_ 391 HudBlk3_B_Rq 1;
BA_ "U_CX482_CX483_MY20_Gas_Tx" SG_ 391 HudBlk3_B_Rq 1;
BA_ "U_CX482_CX483_MY20_Diesel_Tx" SG_ 391 HudBlk3_B_Rq 1;
BA_ "U_U611_U625_MY20_Hev_Tx" SG_ 391 HudBlk3_B_Rq 1;
BA_ "U_U611_U625_MY20_Gas_Tx" SG_ 391 HudBlk3_B_Rq 1;
BA_ "U_U611_U625_MY20_Diesel_Tx" SG_ 391 HudBlk3_B_Rq 1;
BA_ "U_C519_MY18_5_Gas_Tx" SG_ 391 HudBlk3_B_Rq 1;
BA_ "U_C519_MY18_5_Diesel_Tx" SG_ 391 HudBlk3_B_Rq 1;
BA_ "U_B479_MY17_Diesel_Tx" SG_ 391 HudBlk3_B_Rq 1;
BA_ "U_B479_MY17_Gas_Tx" SG_ 391 HudBlk3_B_Rq 1;
BA_ "U_U611_U625_MY20_Phev_Rx" SG_ 391 HudBlk3_B_Rq 1;
BA_ "U_U611_U625_MY20_Hev_Rx" SG_ 391 HudBlk3_B_Rq 1;
BA_ "U_U611_U625_MY20_Gas_Rx" SG_ 391 HudBlk3_B_Rq 1;
BA_ "U_U611_U625_MY20_Diesel_Rx" SG_ 391 HudBlk3_B_Rq 1;
BA_ "U_CX482_CX483_MY20_Hev_Tx" SG_ 391 HudBlk2_B_Rq 1;
BA_ "U_CX482_CX483_MY20_Gas_Tx" SG_ 391 HudBlk2_B_Rq 1;
BA_ "U_CX482_CX483_MY20_Diesel_Tx" SG_ 391 HudBlk2_B_Rq 1;
BA_ "U_U611_U625_MY20_Hev_Tx" SG_ 391 HudBlk2_B_Rq 1;
BA_ "U_U611_U625_MY20_Gas_Tx" SG_ 391 HudBlk2_B_Rq 1;
BA_ "U_U611_U625_MY20_Diesel_Tx" SG_ 391 HudBlk2_B_Rq 1;
BA_ "U_C519_MY18_5_Gas_Tx" SG_ 391 HudBlk2_B_Rq 1;
BA_ "U_C519_MY18_5_Diesel_Tx" SG_ 391 HudBlk2_B_Rq 1;
BA_ "U_B479_MY17_Diesel_Tx" SG_ 391 HudBlk2_B_Rq 1;
BA_ "U_B479_MY17_Gas_Tx" SG_ 391 HudBlk2_B_Rq 1;
BA_ "U_U611_U625_MY20_Phev_Rx" SG_ 391 HudBlk2_B_Rq 1;
BA_ "U_U611_U625_MY20_Hev_Rx" SG_ 391 HudBlk2_B_Rq 1;
BA_ "U_U611_U625_MY20_Gas_Rx" SG_ 391 HudBlk2_B_Rq 1;
BA_ "U_U611_U625_MY20_Diesel_Rx" SG_ 391 HudBlk2_B_Rq 1;
BA_ "U_CX482_CX483_MY20_Hev_Tx" SG_ 391 HudBlk1_B_Rq 1;
BA_ "U_CX482_CX483_MY20_Gas_Tx" SG_ 391 HudBlk1_B_Rq 1;
BA_ "U_CX482_CX483_MY20_Diesel_Tx" SG_ 391 HudBlk1_B_Rq 1;
BA_ "U_U611_U625_MY20_Hev_Tx" SG_ 391 HudBlk1_B_Rq 1;
BA_ "U_U611_U625_MY20_Gas_Tx" SG_ 391 HudBlk1_B_Rq 1;
BA_ "U_U611_U625_MY20_Diesel_Tx" SG_ 391 HudBlk1_B_Rq 1;
BA_ "U_C519_MY18_5_Gas_Tx" SG_ 391 HudBlk1_B_Rq 1;
BA_ "U_C519_MY18_5_Diesel_Tx" SG_ 391 HudBlk1_B_Rq 1;
BA_ "U_B479_MY17_Diesel_Tx" SG_ 391 HudBlk1_B_Rq 1;
BA_ "U_B479_MY17_Gas_Tx" SG_ 391 HudBlk1_B_Rq 1;
BA_ "U_U611_U625_MY20_Phev_Rx" SG_ 391 HudBlk1_B_Rq 1;
BA_ "U_U611_U625_MY20_Hev_Rx" SG_ 391 HudBlk1_B_Rq 1;
BA_ "U_U611_U625_MY20_Gas_Rx" SG_ 391 HudBlk1_B_Rq 1;
BA_ "U_U611_U625_MY20_Diesel_Rx" SG_ 391 HudBlk1_B_Rq 1;
BA_ "U_CX482_CX483_MY20_Hev_Tx" SG_ 391 HudFlashRate_D_Actl 1;
BA_ "U_CX482_CX483_MY20_Gas_Tx" SG_ 391 HudFlashRate_D_Actl 1;
BA_ "U_CX482_CX483_MY20_Diesel_Tx" SG_ 391 HudFlashRate_D_Actl 1;
BA_ "U_U611_U625_MY20_Hev_Tx" SG_ 391 HudFlashRate_D_Actl 1;
BA_ "U_U611_U625_MY20_Gas_Tx" SG_ 391 HudFlashRate_D_Actl 1;
BA_ "U_U611_U625_MY20_Diesel_Tx" SG_ 391 HudFlashRate_D_Actl 1;
BA_ "U_C519_MY18_5_Gas_Tx" SG_ 391 HudFlashRate_D_Actl 1;
BA_ "U_C519_MY18_5_Diesel_Tx" SG_ 391 HudFlashRate_D_Actl 1;
BA_ "U_B479_MY17_Diesel_Tx" SG_ 391 HudFlashRate_D_Actl 1;
BA_ "U_B479_MY17_Gas_Tx" SG_ 391 HudFlashRate_D_Actl 1;
BA_ "U_U611_U625_MY20_Phev_Rx" SG_ 391 HudFlashRate_D_Actl 1;
BA_ "U_U611_U625_MY20_Hev_Rx" SG_ 391 HudFlashRate_D_Actl 1;
BA_ "U_U611_U625_MY20_Gas_Rx" SG_ 391 HudFlashRate_D_Actl 1;
BA_ "U_U611_U625_MY20_Diesel_Rx" SG_ 391 HudFlashRate_D_Actl 1;
BA_ "U_CX482_CX483_MY20_Hev_Tx" SG_ 391 CmbbBrkDecel_No_Cs 1;
BA_ "U_CX482_CX483_MY20_Gas_Tx" SG_ 391 CmbbBrkDecel_No_Cs 1;
BA_ "U_CX482_CX483_MY20_Diesel_Tx" SG_ 391 CmbbBrkDecel_No_Cs 1;
BA_ "U_U611_U625_MY20_Hev_Tx" SG_ 391 CmbbBrkDecel_No_Cs 1;
BA_ "U_U611_U625_MY20_Gas_Tx" SG_ 391 CmbbBrkDecel_No_Cs 1;
BA_ "U_U611_U625_MY20_Diesel_Tx" SG_ 391 CmbbBrkDecel_No_Cs 1;
BA_ "U_C519_MY18_5_Gas_Tx" SG_ 391 CmbbBrkDecel_No_Cs 1;
BA_ "U_C519_MY18_5_Diesel_Tx" SG_ 391 CmbbBrkDecel_No_Cs 1;
BA_ "U_B479_MY17_Diesel_Tx" SG_ 391 CmbbBrkDecel_No_Cs 1;
BA_ "U_B479_MY17_Gas_Tx" SG_ 391 CmbbBrkDecel_No_Cs 1;
BA_ "U_CX482_CX483_MY20_Hev_Rx" SG_ 391 CmbbBrkDecel_No_Cs 1;
BA_ "U_CX482_CX483_MY20_Gas_Rx" SG_ 391 CmbbBrkDecel_No_Cs 1;
BA_ "U_CX482_CX483_MY20_Diesel_Rx" SG_ 391 CmbbBrkDecel_No_Cs 1;
BA_ "U_U611_U625_MY20_Hev_Rx" SG_ 391 CmbbBrkDecel_No_Cs 1;
BA_ "U_U611_U625_MY20_Gas_Rx" SG_ 391 CmbbBrkDecel_No_Cs 1;
BA_ "U_U611_U625_MY20_Diesel_Rx" SG_ 391 CmbbBrkDecel_No_Cs 1;
BA_ "U_C519_MY18_5_Gas_Rx" SG_ 391 CmbbBrkDecel_No_Cs 1;
BA_ "U_C519_MY18_5_Diesel_Rx" SG_ 391 CmbbBrkDecel_No_Cs 1;
BA_ "U_B479_MY17_Diesel_Rx" SG_ 391 CmbbBrkDecel_No_Cs 1;
BA_ "U_B479_MY17_Gas_Rx" SG_ 391 CmbbBrkDecel_No_Cs 1;
BA_ "U_CX482_CX483_MY20_Hev_Tx" SG_ 391 CmbbBrkDecel_A_Rq 1;
BA_ "U_CX482_CX483_MY20_Gas_Tx" SG_ 391 CmbbBrkDecel_A_Rq 1;
BA_ "U_CX482_CX483_MY20_Diesel_Tx" SG_ 391 CmbbBrkDecel_A_Rq 1;
BA_ "U_U611_U625_MY20_Hev_Tx" SG_ 391 CmbbBrkDecel_A_Rq 1;
BA_ "U_U611_U625_MY20_Gas_Tx" SG_ 391 CmbbBrkDecel_A_Rq 1;
BA_ "U_U611_U625_MY20_Diesel_Tx" SG_ 391 CmbbBrkDecel_A_Rq 1;
BA_ "U_C519_MY18_5_Gas_Tx" SG_ 391 CmbbBrkDecel_A_Rq 1;
BA_ "U_C519_MY18_5_Diesel_Tx" SG_ 391 CmbbBrkDecel_A_Rq 1;
BA_ "U_B479_MY17_Diesel_Tx" SG_ 391 CmbbBrkDecel_A_Rq 1;
BA_ "U_B479_MY17_Gas_Tx" SG_ 391 CmbbBrkDecel_A_Rq 1;
BA_ "U_CX482_CX483_MY20_Hev_Rx" SG_ 391 CmbbBrkDecel_A_Rq 1;
BA_ "U_CX482_CX483_MY20_Gas_Rx" SG_ 391 CmbbBrkDecel_A_Rq 1;
BA_ "U_CX482_CX483_MY20_Diesel_Rx" SG_ 391 CmbbBrkDecel_A_Rq 1;
BA_ "U_U611_U625_MY20_Hev_Rx" SG_ 391 CmbbBrkDecel_A_Rq 1;
BA_ "U_U611_U625_MY20_Gas_Rx" SG_ 391 CmbbBrkDecel_A_Rq 1;
BA_ "U_U611_U625_MY20_Diesel_Rx" SG_ 391 CmbbBrkDecel_A_Rq 1;
BA_ "U_C519_MY18_5_Gas_Rx" SG_ 391 CmbbBrkDecel_A_Rq 1;
BA_ "U_C519_MY18_5_Diesel_Rx" SG_ 391 CmbbBrkDecel_A_Rq 1;
BA_ "U_B479_MY17_Diesel_Rx" SG_ 391 CmbbBrkDecel_A_Rq 1;
BA_ "U_B479_MY17_Gas_Rx" SG_ 391 CmbbBrkDecel_A_Rq 1;
BA_ "GenSigStartValue" SG_ 391 CmbbBrkDecel_A_Rq 5129;
BA_ "U_CX482_CX483_MY20_Hev_Tx" SG_ 391 CmbbBrkPrchg_D_Rq 1;
BA_ "U_CX482_CX483_MY20_Gas_Tx" SG_ 391 CmbbBrkPrchg_D_Rq 1;
BA_ "U_CX482_CX483_MY20_Diesel_Tx" SG_ 391 CmbbBrkPrchg_D_Rq 1;
BA_ "U_U611_U625_MY20_Hev_Tx" SG_ 391 CmbbBrkPrchg_D_Rq 1;
BA_ "U_U611_U625_MY20_Gas_Tx" SG_ 391 CmbbBrkPrchg_D_Rq 1;
BA_ "U_U611_U625_MY20_Diesel_Tx" SG_ 391 CmbbBrkPrchg_D_Rq 1;
BA_ "U_C519_MY18_5_Gas_Tx" SG_ 391 CmbbBrkPrchg_D_Rq 1;
BA_ "U_C519_MY18_5_Diesel_Tx" SG_ 391 CmbbBrkPrchg_D_Rq 1;
BA_ "U_B479_MY17_Diesel_Tx" SG_ 391 CmbbBrkPrchg_D_Rq 1;
BA_ "U_B479_MY17_Gas_Tx" SG_ 391 CmbbBrkPrchg_D_Rq 1;
BA_ "U_CX482_CX483_MY20_Hev_Rx" SG_ 391 CmbbBrkPrchg_D_Rq 1;
BA_ "U_CX482_CX483_MY20_Gas_Rx" SG_ 391 CmbbBrkPrchg_D_Rq 1;
BA_ "U_CX482_CX483_MY20_Diesel_Rx" SG_ 391 CmbbBrkPrchg_D_Rq 1;
BA_ "U_U611_U625_MY20_Hev_Rx" SG_ 391 CmbbBrkPrchg_D_Rq 1;
BA_ "U_U611_U625_MY20_Gas_Rx" SG_ 391 CmbbBrkPrchg_D_Rq 1;
BA_ "U_U611_U625_MY20_Diesel_Rx" SG_ 391 CmbbBrkPrchg_D_Rq 1;
BA_ "U_C519_MY18_5_Gas_Rx" SG_ 391 CmbbBrkPrchg_D_Rq 1;
BA_ "U_C519_MY18_5_Diesel_Rx" SG_ 391 CmbbBrkPrchg_D_Rq 1;
BA_ "U_B479_MY17_Diesel_Rx" SG_ 391 CmbbBrkPrchg_D_Rq 1;
BA_ "U_B479_MY17_Gas_Rx" SG_ 391 CmbbBrkPrchg_D_Rq 1;
BA_ "U_CX482_CX483_MY20_Hev_Tx" SG_ 391 CmbbBrkDecel_B_Rq 1;
BA_ "U_CX482_CX483_MY20_Gas_Tx" SG_ 391 CmbbBrkDecel_B_Rq 1;
BA_ "U_CX482_CX483_MY20_Diesel_Tx" SG_ 391 CmbbBrkDecel_B_Rq 1;
BA_ "U_U611_U625_MY20_Hev_Tx" SG_ 391 CmbbBrkDecel_B_Rq 1;
BA_ "U_U611_U625_MY20_Gas_Tx" SG_ 391 CmbbBrkDecel_B_Rq 1;
BA_ "U_U611_U625_MY20_Diesel_Tx" SG_ 391 CmbbBrkDecel_B_Rq 1;
BA_ "U_C519_MY18_5_Gas_Tx" SG_ 391 CmbbBrkDecel_B_Rq 1;
BA_ "U_C519_MY18_5_Diesel_Tx" SG_ 391 CmbbBrkDecel_B_Rq 1;
BA_ "U_B479_MY17_Diesel_Tx" SG_ 391 CmbbBrkDecel_B_Rq 1;
BA_ "U_B479_MY17_Gas_Tx" SG_ 391 CmbbBrkDecel_B_Rq 1;
BA_ "U_CX482_CX483_MY20_Hev_Rx" SG_ 391 CmbbBrkDecel_B_Rq 1;
BA_ "U_CX482_CX483_MY20_Gas_Rx" SG_ 391 CmbbBrkDecel_B_Rq 1;
BA_ "U_CX482_CX483_MY20_Diesel_Rx" SG_ 391 CmbbBrkDecel_B_Rq 1;
BA_ "U_U611_U625_MY20_Hev_Rx" SG_ 391 CmbbBrkDecel_B_Rq 1;
BA_ "U_U611_U625_MY20_Gas_Rx" SG_ 391 CmbbBrkDecel_B_Rq 1;
BA_ "U_U611_U625_MY20_Diesel_Rx" SG_ 391 CmbbBrkDecel_B_Rq 1;
BA_ "U_C519_MY18_5_Gas_Rx" SG_ 391 CmbbBrkDecel_B_Rq 1;
BA_ "U_C519_MY18_5_Diesel_Rx" SG_ 391 CmbbBrkDecel_B_Rq 1;
BA_ "U_B479_MY17_Diesel_Rx" SG_ 391 CmbbBrkDecel_B_Rq 1;
BA_ "U_B479_MY17_Gas_Rx" SG_ 391 CmbbBrkDecel_B_Rq 1;
BA_ "U_CX482_CX483_MY20_Hev_Tx" SG_ 391 CmbbBaSens_D_Rq 1;
BA_ "U_CX482_CX483_MY20_Gas_Tx" SG_ 391 CmbbBaSens_D_Rq 1;
BA_ "U_CX482_CX483_MY20_Diesel_Tx" SG_ 391 CmbbBaSens_D_Rq 1;
BA_ "U_U611_U625_MY20_Hev_Tx" SG_ 391 CmbbBaSens_D_Rq 1;
BA_ "U_U611_U625_MY20_Gas_Tx" SG_ 391 CmbbBaSens_D_Rq 1;
BA_ "U_U611_U625_MY20_Diesel_Tx" SG_ 391 CmbbBaSens_D_Rq 1;
BA_ "U_C519_MY18_5_Gas_Tx" SG_ 391 CmbbBaSens_D_Rq 1;
BA_ "U_C519_MY18_5_Diesel_Tx" SG_ 391 CmbbBaSens_D_Rq 1;
BA_ "U_B479_MY17_Diesel_Tx" SG_ 391 CmbbBaSens_D_Rq 1;
BA_ "U_B479_MY17_Gas_Tx" SG_ 391 CmbbBaSens_D_Rq 1;
BA_ "U_CX482_CX483_MY20_Hev_Rx" SG_ 391 CmbbBaSens_D_Rq 1;
BA_ "U_CX482_CX483_MY20_Gas_Rx" SG_ 391 CmbbBaSens_D_Rq 1;
BA_ "U_CX482_CX483_MY20_Diesel_Rx" SG_ 391 CmbbBaSens_D_Rq 1;
BA_ "U_U611_U625_MY20_Hev_Rx" SG_ 391 CmbbBaSens_D_Rq 1;
BA_ "U_U611_U625_MY20_Gas_Rx" SG_ 391 CmbbBaSens_D_Rq 1;
BA_ "U_U611_U625_MY20_Diesel_Rx" SG_ 391 CmbbBaSens_D_Rq 1;
BA_ "U_C519_MY18_5_Gas_Rx" SG_ 391 CmbbBaSens_D_Rq 1;
BA_ "U_C519_MY18_5_Diesel_Rx" SG_ 391 CmbbBaSens_D_Rq 1;
BA_ "U_B479_MY17_Diesel_Rx" SG_ 391 CmbbBaSens_D_Rq 1;
BA_ "U_B479_MY17_Gas_Rx" SG_ 391 CmbbBaSens_D_Rq 1;
BA_ "U_CX482_CX483_MY20_Hev_Tx" SG_ 535 WhlRr_W_Meas 1;
BA_ "U_CX482_CX483_MY20_Gas_Tx" SG_ 535 WhlRr_W_Meas 1;
BA_ "U_CX482_CX483_MY20_Diesel_Tx" SG_ 535 WhlRr_W_Meas 1;
BA_ "U_U611_U625_MY20_Hev_Tx" SG_ 535 WhlRr_W_Meas 1;
BA_ "U_U611_U625_MY20_Gas_Tx" SG_ 535 WhlRr_W_Meas 1;
BA_ "U_U611_U625_MY20_Diesel_Tx" SG_ 535 WhlRr_W_Meas 1;
BA_ "U_B500_MY18_Diesel_Tx" SG_ 535 WhlRr_W_Meas 1;
BA_ "U_B500_MY18_Gas_Tx" SG_ 535 WhlRr_W_Meas 1;
BA_ "U_C490_MY18_Tx" SG_ 535 WhlRr_W_Meas 1;
BA_ "U_B562_MY18_Gas_Tx" SG_ 535 WhlRr_W_Meas 1;
BA_ "U_C519_MY18_5_Gas_Tx" SG_ 535 WhlRr_W_Meas 1;
BA_ "U_C519_MY18_5_Diesel_Tx" SG_ 535 WhlRr_W_Meas 1;
BA_ "U_B515_MCA_MY17_Gas_Tx" SG_ 535 WhlRr_W_Meas 1;
BA_ "U_B515_MCA_MY17_Diesel_Tx" SG_ 535 WhlRr_W_Meas 1;
BA_ "U_B479_MY17_Diesel_Tx" SG_ 535 WhlRr_W_Meas 1;
BA_ "U_B479_MY17_Gas_Tx" SG_ 535 WhlRr_W_Meas 1;
BA_ "U_B562LC_MY15_Gas_Tx" SG_ 535 WhlRr_W_Meas 1;
BA_ "U_B562LC_MY15_Diesel_Tx" SG_ 535 WhlRr_W_Meas 1;
BA_ "U_U611_U625_MY20_Phev_Rx" SG_ 535 WhlRr_W_Meas 1;
BA_ "U_CX482_CX483_MY20_Hev_Rx" SG_ 535 WhlRr_W_Meas 1;
BA_ "U_CX482_CX483_MY20_Gas_Rx" SG_ 535 WhlRr_W_Meas 1;
BA_ "U_CX482_CX483_MY20_Diesel_Rx" SG_ 535 WhlRr_W_Meas 1;
BA_ "U_U611_U625_MY20_Hev_Rx" SG_ 535 WhlRr_W_Meas 1;
BA_ "U_U611_U625_MY20_Gas_Rx" SG_ 535 WhlRr_W_Meas 1;
BA_ "U_U611_U625_MY20_Diesel_Rx" SG_ 535 WhlRr_W_Meas 1;
BA_ "U_B500_MY18_Diesel_Rx" SG_ 535 WhlRr_W_Meas 1;
BA_ "U_B500_MY18_Gas_Rx" SG_ 535 WhlRr_W_Meas 1;
BA_ "U_C519_MY18_5_Gas_Rx" SG_ 535 WhlRr_W_Meas 1;
BA_ "U_C519_MY18_5_Diesel_Rx" SG_ 535 WhlRr_W_Meas 1;
BA_ "U_B479_MY17_Diesel_Rx" SG_ 535 WhlRr_W_Meas 1;
BA_ "U_B479_MY17_Gas_Rx" SG_ 535 WhlRr_W_Meas 1;
BA_ "U_CX482_CX483_MY20_Hev_Tx" SG_ 535 WhlRl_W_Meas 1;
BA_ "U_CX482_CX483_MY20_Gas_Tx" SG_ 535 WhlRl_W_Meas 1;
BA_ "U_CX482_CX483_MY20_Diesel_Tx" SG_ 535 WhlRl_W_Meas 1;
BA_ "U_U611_U625_MY20_Hev_Tx" SG_ 535 WhlRl_W_Meas 1;
BA_ "U_U611_U625_MY20_Gas_Tx" SG_ 535 WhlRl_W_Meas 1;
BA_ "U_U611_U625_MY20_Diesel_Tx" SG_ 535 WhlRl_W_Meas 1;
BA_ "U_B500_MY18_Diesel_Tx" SG_ 535 WhlRl_W_Meas 1;
BA_ "U_B500_MY18_Gas_Tx" SG_ 535 WhlRl_W_Meas 1;
BA_ "U_C490_MY18_Tx" SG_ 535 WhlRl_W_Meas 1;
BA_ "U_B562_MY18_Gas_Tx" SG_ 535 WhlRl_W_Meas 1;
BA_ "U_C519_MY18_5_Gas_Tx" SG_ 535 WhlRl_W_Meas 1;
BA_ "U_C519_MY18_5_Diesel_Tx" SG_ 535 WhlRl_W_Meas 1;
BA_ "U_B515_MCA_MY17_Gas_Tx" SG_ 535 WhlRl_W_Meas 1;
BA_ "U_B515_MCA_MY17_Diesel_Tx" SG_ 535 WhlRl_W_Meas 1;
BA_ "U_B479_MY17_Diesel_Tx" SG_ 535 WhlRl_W_Meas 1;
BA_ "U_B479_MY17_Gas_Tx" SG_ 535 WhlRl_W_Meas 1;
BA_ "U_B562LC_MY15_Gas_Tx" SG_ 535 WhlRl_W_Meas 1;
BA_ "U_B562LC_MY15_Diesel_Tx" SG_ 535 WhlRl_W_Meas 1;
BA_ "U_U611_U625_MY20_Phev_Rx" SG_ 535 WhlRl_W_Meas 1;
BA_ "U_CX482_CX483_MY20_Hev_Rx" SG_ 535 WhlRl_W_Meas 1;
BA_ "U_CX482_CX483_MY20_Gas_Rx" SG_ 535 WhlRl_W_Meas 1;
BA_ "U_CX482_CX483_MY20_Diesel_Rx" SG_ 535 WhlRl_W_Meas 1;
BA_ "U_U611_U625_MY20_Hev_Rx" SG_ 535 WhlRl_W_Meas 1;
BA_ "U_U611_U625_MY20_Gas_Rx" SG_ 535 WhlRl_W_Meas 1;
BA_ "U_U611_U625_MY20_Diesel_Rx" SG_ 535 WhlRl_W_Meas 1;
BA_ "U_B500_MY18_Diesel_Rx" SG_ 535 WhlRl_W_Meas 1;
BA_ "U_B500_MY18_Gas_Rx" SG_ 535 WhlRl_W_Meas 1;
BA_ "U_C519_MY18_5_Gas_Rx" SG_ 535 WhlRl_W_Meas 1;
BA_ "U_C519_MY18_5_Diesel_Rx" SG_ 535 WhlRl_W_Meas 1;
BA_ "U_B479_MY17_Diesel_Rx" SG_ 535 WhlRl_W_Meas 1;
BA_ "U_B479_MY17_Gas_Rx" SG_ 535 WhlRl_W_Meas 1;
BA_ "U_CX482_CX483_MY20_Hev_Tx" SG_ 535 WhlFr_W_Meas 1;
BA_ "U_CX482_CX483_MY20_Gas_Tx" SG_ 535 WhlFr_W_Meas 1;
BA_ "U_CX482_CX483_MY20_Diesel_Tx" SG_ 535 WhlFr_W_Meas 1;
BA_ "U_U611_U625_MY20_Hev_Tx" SG_ 535 WhlFr_W_Meas 1;
BA_ "U_U611_U625_MY20_Gas_Tx" SG_ 535 WhlFr_W_Meas 1;
BA_ "U_U611_U625_MY20_Diesel_Tx" SG_ 535 WhlFr_W_Meas 1;
BA_ "U_B500_MY18_Diesel_Tx" SG_ 535 WhlFr_W_Meas 1;
BA_ "U_B500_MY18_Gas_Tx" SG_ 535 WhlFr_W_Meas 1;
BA_ "U_C490_MY18_Tx" SG_ 535 WhlFr_W_Meas 1;
BA_ "U_B562_MY18_Gas_Tx" SG_ 535 WhlFr_W_Meas 1;
BA_ "U_C519_MY18_5_Gas_Tx" SG_ 535 WhlFr_W_Meas 1;
BA_ "U_C519_MY18_5_Diesel_Tx" SG_ 535 WhlFr_W_Meas 1;
BA_ "U_B515_MCA_MY17_Gas_Tx" SG_ 535 WhlFr_W_Meas 1;
BA_ "U_B515_MCA_MY17_Diesel_Tx" SG_ 535 WhlFr_W_Meas 1;
BA_ "U_B479_MY17_Diesel_Tx" SG_ 535 WhlFr_W_Meas 1;
BA_ "U_B479_MY17_Gas_Tx" SG_ 535 WhlFr_W_Meas 1;
BA_ "U_B562LC_MY15_Gas_Tx" SG_ 535 WhlFr_W_Meas 1;
BA_ "U_B562LC_MY15_Diesel_Tx" SG_ 535 WhlFr_W_Meas 1;
BA_ "U_U611_U625_MY20_Phev_Rx" SG_ 535 WhlFr_W_Meas 1;
BA_ "U_CX482_CX483_MY20_Hev_Rx" SG_ 535 WhlFr_W_Meas 1;
BA_ "U_CX482_CX483_MY20_Gas_Rx" SG_ 535 WhlFr_W_Meas 1;
BA_ "U_CX482_CX483_MY20_Diesel_Rx" SG_ 535 WhlFr_W_Meas 1;
BA_ "U_U611_U625_MY20_Hev_Rx" SG_ 535 WhlFr_W_Meas 1;
BA_ "U_U611_U625_MY20_Gas_Rx" SG_ 535 WhlFr_W_Meas 1;
BA_ "U_U611_U625_MY20_Diesel_Rx" SG_ 535 WhlFr_W_Meas 1;
BA_ "U_B500_MY18_Diesel_Rx" SG_ 535 WhlFr_W_Meas 1;
BA_ "U_B500_MY18_Gas_Rx" SG_ 535 WhlFr_W_Meas 1;
BA_ "U_C490_MY18_Rx" SG_ 535 WhlFr_W_Meas 1;
BA_ "U_B562_MY18_Gas_Rx" SG_ 535 WhlFr_W_Meas 1;
BA_ "U_B515_MCA_MY17_Gas_Rx" SG_ 535 WhlFr_W_Meas 1;
BA_ "U_B515_MCA_MY17_Diesel_Rx" SG_ 535 WhlFr_W_Meas 1;
BA_ "U_C519_MY18_5_Gas_Rx" SG_ 535 WhlFr_W_Meas 1;
BA_ "U_C519_MY18_5_Diesel_Rx" SG_ 535 WhlFr_W_Meas 1;
BA_ "U_B479_MY17_Diesel_Rx" SG_ 535 WhlFr_W_Meas 1;
BA_ "U_B479_MY17_Gas_Rx" SG_ 535 WhlFr_W_Meas 1;
BA_ "U_CX482_CX483_MY20_Hev_Tx" SG_ 535 WhlFl_W_Meas 1;
BA_ "U_CX482_CX483_MY20_Gas_Tx" SG_ 535 WhlFl_W_Meas 1;
BA_ "U_CX482_CX483_MY20_Diesel_Tx" SG_ 535 WhlFl_W_Meas 1;
BA_ "U_U611_U625_MY20_Hev_Tx" SG_ 535 WhlFl_W_Meas 1;
BA_ "U_U611_U625_MY20_Gas_Tx" SG_ 535 WhlFl_W_Meas 1;
BA_ "U_U611_U625_MY20_Diesel_Tx" SG_ 535 WhlFl_W_Meas 1;
BA_ "U_B500_MY18_Diesel_Tx" SG_ 535 WhlFl_W_Meas 1;
BA_ "U_B500_MY18_Gas_Tx" SG_ 535 WhlFl_W_Meas 1;
BA_ "U_C490_MY18_Tx" SG_ 535 WhlFl_W_Meas 1;
BA_ "U_B562_MY18_Gas_Tx" SG_ 535 WhlFl_W_Meas 1;
BA_ "U_C519_MY18_5_Gas_Tx" SG_ 535 WhlFl_W_Meas 1;
BA_ "U_C519_MY18_5_Diesel_Tx" SG_ 535 WhlFl_W_Meas 1;
BA_ "U_B515_MCA_MY17_Gas_Tx" SG_ 535 WhlFl_W_Meas 1;
BA_ "U_B515_MCA_MY17_Diesel_Tx" SG_ 535 WhlFl_W_Meas 1;
BA_ "U_B479_MY17_Diesel_Tx" SG_ 535 WhlFl_W_Meas 1;
BA_ "U_B479_MY17_Gas_Tx" SG_ 535 WhlFl_W_Meas 1;
BA_ "U_B562LC_MY15_Gas_Tx" SG_ 535 WhlFl_W_Meas 1;
BA_ "U_B562LC_MY15_Diesel_Tx" SG_ 535 WhlFl_W_Meas 1;
BA_ "U_U611_U625_MY20_Phev_Rx" SG_ 535 WhlFl_W_Meas 1;
BA_ "U_CX482_CX483_MY20_Hev_Rx" SG_ 535 WhlFl_W_Meas 1;
BA_ "U_CX482_CX483_MY20_Gas_Rx" SG_ 535 WhlFl_W_Meas 1;
BA_ "U_CX482_CX483_MY20_Diesel_Rx" SG_ 535 WhlFl_W_Meas 1;
BA_ "U_U611_U625_MY20_Hev_Rx" SG_ 535 WhlFl_W_Meas 1;
BA_ "U_U611_U625_MY20_Gas_Rx" SG_ 535 WhlFl_W_Meas 1;
BA_ "U_U611_U625_MY20_Diesel_Rx" SG_ 535 WhlFl_W_Meas 1;
BA_ "U_B500_MY18_Diesel_Rx" SG_ 535 WhlFl_W_Meas 1;
BA_ "U_B500_MY18_Gas_Rx" SG_ 535 WhlFl_W_Meas 1;
BA_ "U_C490_MY18_Rx" SG_ 535 WhlFl_W_Meas 1;
BA_ "U_B562_MY18_Gas_Rx" SG_ 535 WhlFl_W_Meas 1;
BA_ "U_B515_MCA_MY17_Gas_Rx" SG_ 535 WhlFl_W_Meas 1;
BA_ "U_B515_MCA_MY17_Diesel_Rx" SG_ 535 WhlFl_W_Meas 1;
BA_ "U_C519_MY18_5_Gas_Rx" SG_ 535 WhlFl_W_Meas 1;
BA_ "U_C519_MY18_5_Diesel_Rx" SG_ 535 WhlFl_W_Meas 1;
BA_ "U_B479_MY17_Diesel_Rx" SG_ 535 WhlFl_W_Meas 1;
BA_ "U_B479_MY17_Gas_Rx" SG_ 535 WhlFl_W_Meas 1;
BA_ "U_U611_U625_MY20_Hev_Tx" SG_ 532 RgenTqFalt_B_Actl 1;
BA_ "U_U611_U625_MY20_Gas_Tx" SG_ 532 RgenTqFalt_B_Actl 1;
BA_ "U_U611_U625_MY20_Diesel_Tx" SG_ 532 RgenTqFalt_B_Actl 1;
BA_ "U_U611_U625_MY20_Hev_Tx" SG_ 532 RgenBrkDynoMde_B_Actl 1;
BA_ "U_U611_U625_MY20_Gas_Tx" SG_ 532 RgenBrkDynoMde_B_Actl 1;
BA_ "U_U611_U625_MY20_Diesel_Tx" SG_ 532 RgenBrkDynoMde_B_Actl 1;
BA_ "U_CX482_CX483_MY20_Hev_Tx" SG_ 532 PrplWhlTqRqMn_No_Cs 1;
BA_ "U_CX482_CX483_MY20_Gas_Tx" SG_ 532 PrplWhlTqRqMn_No_Cs 1;
BA_ "U_CX482_CX483_MY20_Diesel_Tx" SG_ 532 PrplWhlTqRqMn_No_Cs 1;
BA_ "U_U611_U625_MY20_Hev_Tx" SG_ 532 PrplWhlTqRqMn_No_Cs 1;
BA_ "U_U611_U625_MY20_Gas_Tx" SG_ 532 PrplWhlTqRqMn_No_Cs 1;
BA_ "U_U611_U625_MY20_Diesel_Tx" SG_ 532 PrplWhlTqRqMn_No_Cs 1;
BA_ "U_B500_MY18_Diesel_Tx" SG_ 532 PrplWhlTqRqMn_No_Cs 1;
BA_ "U_B500_MY18_Gas_Tx" SG_ 532 PrplWhlTqRqMn_No_Cs 1;
BA_ "U_C519_MY18_5_Gas_Tx" SG_ 532 PrplWhlTqRqMn_No_Cs 1;
BA_ "U_C519_MY18_5_Diesel_Tx" SG_ 532 PrplWhlTqRqMn_No_Cs 1;
BA_ "U_B515_MCA_MY17_Gas_Tx" SG_ 532 PrplWhlTqRqMn_No_Cs 1;
BA_ "U_B515_MCA_MY17_Diesel_Tx" SG_ 532 PrplWhlTqRqMn_No_Cs 1;
BA_ "U_B479_MY17_Diesel_Tx" SG_ 532 PrplWhlTqRqMn_No_Cs 1;
BA_ "U_B479_MY17_Gas_Tx" SG_ 532 PrplWhlTqRqMn_No_Cs 1;
BA_ "U_B562LC_MY15_Gas_Tx" SG_ 532 PrplWhlTqRqMn_No_Cs 1;
BA_ "U_B562LC_MY15_Diesel_Tx" SG_ 532 PrplWhlTqRqMn_No_Cs 1;
BA_ "U_CX482_CX483_MY20_Hev_Tx" SG_ 532 PrplWhlRear_Tq_RqMx 1;
BA_ "U_CX482_CX483_MY20_Gas_Tx" SG_ 532 PrplWhlRear_Tq_RqMx 1;
BA_ "U_CX482_CX483_MY20_Diesel_Tx" SG_ 532 PrplWhlRear_Tq_RqMx 1;
BA_ "U_U611_U625_MY20_Hev_Tx" SG_ 532 PrplWhlRear_Tq_RqMx 1;
BA_ "U_U611_U625_MY20_Gas_Tx" SG_ 532 PrplWhlRear_Tq_RqMx 1;
BA_ "U_U611_U625_MY20_Diesel_Tx" SG_ 532 PrplWhlRear_Tq_RqMx 1;
BA_ "U_C519_MY18_5_Gas_Tx" SG_ 532 PrplWhlRear_Tq_RqMx 1;
BA_ "U_C519_MY18_5_Diesel_Tx" SG_ 532 PrplWhlRear_Tq_RqMx 1;
BA_ "U_B515_MCA_MY17_Gas_Tx" SG_ 532 PrplWhlRear_Tq_RqMx 1;
BA_ "U_B515_MCA_MY17_Diesel_Tx" SG_ 532 PrplWhlRear_Tq_RqMx 1;
BA_ "U_B479_MY17_Diesel_Tx" SG_ 532 PrplWhlRear_Tq_RqMx 1;
BA_ "U_B479_MY17_Gas_Tx" SG_ 532 PrplWhlRear_Tq_RqMx 1;
BA_ "U_CX482_CX483_MY20_Hev_Tx" SG_ 532 PrplWhlTot_Tq_RqMn 1;
BA_ "U_CX482_CX483_MY20_Gas_Tx" SG_ 532 PrplWhlTot_Tq_RqMn 1;
BA_ "U_CX482_CX483_MY20_Diesel_Tx" SG_ 532 PrplWhlTot_Tq_RqMn 1;
BA_ "U_U611_U625_MY20_Hev_Tx" SG_ 532 PrplWhlTot_Tq_RqMn 1;
BA_ "U_U611_U625_MY20_Gas_Tx" SG_ 532 PrplWhlTot_Tq_RqMn 1;
BA_ "U_U611_U625_MY20_Diesel_Tx" SG_ 532 PrplWhlTot_Tq_RqMn 1;
BA_ "U_B500_MY18_Diesel_Tx" SG_ 532 PrplWhlTot_Tq_RqMn 1;
BA_ "U_B500_MY18_Gas_Tx" SG_ 532 PrplWhlTot_Tq_RqMn 1;
BA_ "U_C519_MY18_5_Gas_Tx" SG_ 532 PrplWhlTot_Tq_RqMn 1;
BA_ "U_C519_MY18_5_Diesel_Tx" SG_ 532 PrplWhlTot_Tq_RqMn 1;
BA_ "U_B515_MCA_MY17_Gas_Tx" SG_ 532 PrplWhlTot_Tq_RqMn 1;
BA_ "U_B515_MCA_MY17_Diesel_Tx" SG_ 532 PrplWhlTot_Tq_RqMn 1;
BA_ "U_B479_MY17_Diesel_Tx" SG_ 532 PrplWhlTot_Tq_RqMn 1;
BA_ "U_B479_MY17_Gas_Tx" SG_ 532 PrplWhlTot_Tq_RqMn 1;
BA_ "U_B562LC_MY15_Gas_Tx" SG_ 532 PrplWhlTot_Tq_RqMn 1;
BA_ "U_B562LC_MY15_Diesel_Tx" SG_ 532 PrplWhlTot_Tq_RqMn 1;
BA_ "U_CX482_CX483_MY20_Hev_Tx" SG_ 532 PrplWhlTqRqMn_No_Cnt 1;
BA_ "U_CX482_CX483_MY20_Gas_Tx" SG_ 532 PrplWhlTqRqMn_No_Cnt 1;
BA_ "U_CX482_CX483_MY20_Diesel_Tx" SG_ 532 PrplWhlTqRqMn_No_Cnt 1;
BA_ "U_U611_U625_MY20_Hev_Tx" SG_ 532 PrplWhlTqRqMn_No_Cnt 1;
BA_ "U_U611_U625_MY20_Gas_Tx" SG_ 532 PrplWhlTqRqMn_No_Cnt 1;
BA_ "U_U611_U625_MY20_Diesel_Tx" SG_ 532 PrplWhlTqRqMn_No_Cnt 1;
BA_ "U_B500_MY18_Diesel_Tx" SG_ 532 PrplWhlTqRqMn_No_Cnt 1;
BA_ "U_B500_MY18_Gas_Tx" SG_ 532 PrplWhlTqRqMn_No_Cnt 1;
BA_ "U_C519_MY18_5_Gas_Tx" SG_ 532 PrplWhlTqRqMn_No_Cnt 1;
BA_ "U_C519_MY18_5_Diesel_Tx" SG_ 532 PrplWhlTqRqMn_No_Cnt 1;
BA_ "U_B515_MCA_MY17_Gas_Tx" SG_ 532 PrplWhlTqRqMn_No_Cnt 1;
BA_ "U_B515_MCA_MY17_Diesel_Tx" SG_ 532 PrplWhlTqRqMn_No_Cnt 1;
BA_ "U_B479_MY17_Diesel_Tx" SG_ 532 PrplWhlTqRqMn_No_Cnt 1;
BA_ "U_B479_MY17_Gas_Tx" SG_ 532 PrplWhlTqRqMn_No_Cnt 1;
BA_ "U_B562LC_MY15_Gas_Tx" SG_ 532 PrplWhlTqRqMn_No_Cnt 1;
BA_ "U_B562LC_MY15_Diesel_Tx" SG_ 532 PrplWhlTqRqMn_No_Cnt 1;
BA_ "U_CX482_CX483_MY20_Hev_Tx" SG_ 532 PrplWhlRear_Tq_RqMn 1;
BA_ "U_CX482_CX483_MY20_Gas_Tx" SG_ 532 PrplWhlRear_Tq_RqMn 1;
BA_ "U_CX482_CX483_MY20_Diesel_Tx" SG_ 532 PrplWhlRear_Tq_RqMn 1;
BA_ "U_U611_U625_MY20_Hev_Tx" SG_ 532 PrplWhlRear_Tq_RqMn 1;
BA_ "U_U611_U625_MY20_Gas_Tx" SG_ 532 PrplWhlRear_Tq_RqMn 1;
BA_ "U_U611_U625_MY20_Diesel_Tx" SG_ 532 PrplWhlRear_Tq_RqMn 1;
BA_ "U_C519_MY18_5_Gas_Tx" SG_ 532 PrplWhlRear_Tq_RqMn 1;
BA_ "U_C519_MY18_5_Diesel_Tx" SG_ 532 PrplWhlRear_Tq_RqMn 1;
BA_ "U_B515_MCA_MY17_Gas_Tx" SG_ 532 PrplWhlRear_Tq_RqMn 1;
BA_ "U_B515_MCA_MY17_Diesel_Tx" SG_ 532 PrplWhlRear_Tq_RqMn 1;
BA_ "U_B479_MY17_Diesel_Tx" SG_ 532 PrplWhlRear_Tq_RqMn 1;
BA_ "U_B479_MY17_Gas_Tx" SG_ 532 PrplWhlRear_Tq_RqMn 1;
BA_ "GenSigTimeoutTime_GWM" SG_ 531 VehStop_D_Stat 60;
BA_ "U_CX482_CX483_MY20_Hev_Tx" SG_ 531 VehStop_D_Stat 1;
BA_ "U_CX482_CX483_MY20_Gas_Tx" SG_ 531 VehStop_D_Stat 1;
BA_ "U_CX482_CX483_MY20_Diesel_Tx" SG_ 531 VehStop_D_Stat 1;
BA_ "U_U611_U625_MY20_Hev_Tx" SG_ 531 VehStop_D_Stat 1;
BA_ "U_U611_U625_MY20_Gas_Tx" SG_ 531 VehStop_D_Stat 1;
BA_ "U_U611_U625_MY20_Diesel_Tx" SG_ 531 VehStop_D_Stat 1;
BA_ "U_B562_MY18_Gas_Tx" SG_ 531 VehStop_D_Stat 1;
BA_ "U_C519_MY18_5_Gas_Tx" SG_ 531 VehStop_D_Stat 1;
BA_ "U_C519_MY18_5_Diesel_Tx" SG_ 531 VehStop_D_Stat 1;
BA_ "U_B515_MCA_MY17_Gas_Tx" SG_ 531 VehStop_D_Stat 1;
BA_ "U_B515_MCA_MY17_Diesel_Tx" SG_ 531 VehStop_D_Stat 1;
BA_ "U_B479_MY17_Diesel_Tx" SG_ 531 VehStop_D_Stat 1;
BA_ "U_B479_MY17_Gas_Tx" SG_ 531 VehStop_D_Stat 1;
BA_ "U_CX482_CX483_MY20_Hev_Rx" SG_ 531 VehStop_D_Stat 1;
BA_ "U_CX482_CX483_MY20_Gas_Rx" SG_ 531 VehStop_D_Stat 1;
BA_ "U_CX482_CX483_MY20_Diesel_Rx" SG_ 531 VehStop_D_Stat 1;
BA_ "U_U611_U625_MY20_Hev_Rx" SG_ 531 VehStop_D_Stat 1;
BA_ "U_U611_U625_MY20_Gas_Rx" SG_ 531 VehStop_D_Stat 1;
BA_ "U_U611_U625_MY20_Diesel_Rx" SG_ 531 VehStop_D_Stat 1;
BA_ "U_C519_MY18_5_Gas_Rx" SG_ 531 VehStop_D_Stat 1;
BA_ "U_C519_MY18_5_Diesel_Rx" SG_ 531 VehStop_D_Stat 1;
BA_ "GenSigStartValue" SG_ 531 VehStop_D_Stat 2;
BA_ "GenSigTimeoutTime_GWM" SG_ 531 TracCtlPtActv_B_Actl 60;
BA_ "U_CX482_CX483_MY20_Hev_Tx" SG_ 531 TracCtlPtActv_B_Actl 1;
BA_ "U_CX482_CX483_MY20_Gas_Tx" SG_ 531 TracCtlPtActv_B_Actl 1;
BA_ "U_CX482_CX483_MY20_Diesel_Tx" SG_ 531 TracCtlPtActv_B_Actl 1;
BA_ "U_U611_U625_MY20_Hev_Tx" SG_ 531 TracCtlPtActv_B_Actl 1;
BA_ "U_U611_U625_MY20_Gas_Tx" SG_ 531 TracCtlPtActv_B_Actl 1;
BA_ "U_U611_U625_MY20_Diesel_Tx" SG_ 531 TracCtlPtActv_B_Actl 1;
BA_ "U_B500_MY18_Diesel_Tx" SG_ 531 TracCtlPtActv_B_Actl 1;
BA_ "U_B500_MY18_Gas_Tx" SG_ 531 TracCtlPtActv_B_Actl 1;
BA_ "U_C490_MY18_Tx" SG_ 531 TracCtlPtActv_B_Actl 1;
BA_ "U_B562_MY18_Gas_Tx" SG_ 531 TracCtlPtActv_B_Actl 1;
BA_ "U_C519_MY18_5_Gas_Tx" SG_ 531 TracCtlPtActv_B_Actl 1;
BA_ "U_C519_MY18_5_Diesel_Tx" SG_ 531 TracCtlPtActv_B_Actl 1;
BA_ "U_B515_MCA_MY17_Gas_Tx" SG_ 531 TracCtlPtActv_B_Actl 1;
BA_ "U_B515_MCA_MY17_Diesel_Tx" SG_ 531 TracCtlPtActv_B_Actl 1;
BA_ "U_B479_MY17_Diesel_Tx" SG_ 531 TracCtlPtActv_B_Actl 1;
BA_ "U_B479_MY17_Gas_Tx" SG_ 531 TracCtlPtActv_B_Actl 1;
BA_ "U_B562LC_MY15_Gas_Tx" SG_ 531 TracCtlPtActv_B_Actl 1;
BA_ "U_B562LC_MY15_Diesel_Tx" SG_ 531 TracCtlPtActv_B_Actl 1;
BA_ "U_U611_U625_MY20_Phev_Rx" SG_ 531 TracCtlPtActv_B_Actl 1;
BA_ "U_CX482_CX483_MY20_Hev_Rx" SG_ 531 TracCtlPtActv_B_Actl 1;
BA_ "U_CX482_CX483_MY20_Gas_Rx" SG_ 531 TracCtlPtActv_B_Actl 1;
BA_ "U_CX482_CX483_MY20_Diesel_Rx" SG_ 531 TracCtlPtActv_B_Actl 1;
BA_ "U_U611_U625_MY20_Hev_Rx" SG_ 531 TracCtlPtActv_B_Actl 1;
BA_ "U_U611_U625_MY20_Gas_Rx" SG_ 531 TracCtlPtActv_B_Actl 1;
BA_ "U_U611_U625_MY20_Diesel_Rx" SG_ 531 TracCtlPtActv_B_Actl 1;
BA_ "U_B500_MY18_Diesel_Rx" SG_ 531 TracCtlPtActv_B_Actl 1;
BA_ "U_B500_MY18_Gas_Rx" SG_ 531 TracCtlPtActv_B_Actl 1;
BA_ "U_C490_MY18_Rx" SG_ 531 TracCtlPtActv_B_Actl 1;
BA_ "U_B562_MY18_Gas_Rx" SG_ 531 TracCtlPtActv_B_Actl 1;
BA_ "U_B515_MCA_MY17_Gas_Rx" SG_ 531 TracCtlPtActv_B_Actl 1;
BA_ "U_B515_MCA_MY17_Diesel_Rx" SG_ 531 TracCtlPtActv_B_Actl 1;
BA_ "U_C519_MY18_5_Gas_Rx" SG_ 531 TracCtlPtActv_B_Actl 1;
BA_ "U_C519_MY18_5_Diesel_Rx" SG_ 531 TracCtlPtActv_B_Actl 1;
BA_ "U_B479_MY17_Diesel_Rx" SG_ 531 TracCtlPtActv_B_Actl 1;
BA_ "U_B479_MY17_Gas_Rx" SG_ 531 TracCtlPtActv_B_Actl 1;
BA_ "CrossOver_InfoCAN" SG_ 531 TracCtlPtActv_B_Actl 1;
BA_ "GenSigTimeoutTime_GWM" SG_ 531 LscmbbMntr_B_Err 60;
BA_ "U_U611_U625_MY20_Hev_Tx" SG_ 531 LscmbbMntr_B_Err 1;
BA_ "U_U611_U625_MY20_Gas_Tx" SG_ 531 LscmbbMntr_B_Err 1;
BA_ "U_U611_U625_MY20_Diesel_Tx" SG_ 531 LscmbbMntr_B_Err 1;
BA_ "U_B515_MCA_MY17_Gas_Tx" SG_ 531 LscmbbMntr_B_Err 1;
BA_ "U_B515_MCA_MY17_Diesel_Tx" SG_ 531 LscmbbMntr_B_Err 1;
BA_ "U_B562LC_MY15_Gas_Tx" SG_ 531 LscmbbMntr_B_Err 1;
BA_ "U_B562LC_MY15_Diesel_Tx" SG_ 531 LscmbbMntr_B_Err 1;
BA_ "CrossOver_InfoCAN" SG_ 531 LscmbbMntr_B_Err 1;
BA_ "GenSigTimeoutTime_GWM" SG_ 531 LscmbbBrkDis_B_Actl 60;
BA_ "U_U611_U625_MY20_Hev_Tx" SG_ 531 LscmbbBrkDis_B_Actl 1;
BA_ "U_U611_U625_MY20_Gas_Tx" SG_ 531 LscmbbBrkDis_B_Actl 1;
BA_ "U_U611_U625_MY20_Diesel_Tx" SG_ 531 LscmbbBrkDis_B_Actl 1;
BA_ "U_B515_MCA_MY17_Gas_Tx" SG_ 531 LscmbbBrkDis_B_Actl 1;
BA_ "U_B515_MCA_MY17_Diesel_Tx" SG_ 531 LscmbbBrkDis_B_Actl 1;
BA_ "U_B562LC_MY15_Gas_Tx" SG_ 531 LscmbbBrkDis_B_Actl 1;
BA_ "U_B562LC_MY15_Diesel_Tx" SG_ 531 LscmbbBrkDis_B_Actl 1;
BA_ "CrossOver_InfoCAN" SG_ 531 LscmbbBrkDis_B_Actl 1;
BA_ "GenSigTimeoutTime_GWM" SG_ 531 LscmbbDeny_B_ActlBrk 60;
BA_ "U_U611_U625_MY20_Hev_Tx" SG_ 531 LscmbbDeny_B_ActlBrk 1;
BA_ "U_U611_U625_MY20_Gas_Tx" SG_ 531 LscmbbDeny_B_ActlBrk 1;
BA_ "U_U611_U625_MY20_Diesel_Tx" SG_ 531 LscmbbDeny_B_ActlBrk 1;
BA_ "U_B515_MCA_MY17_Gas_Tx" SG_ 531 LscmbbDeny_B_ActlBrk 1;
BA_ "U_B515_MCA_MY17_Diesel_Tx" SG_ 531 LscmbbDeny_B_ActlBrk 1;
BA_ "U_B562LC_MY15_Gas_Tx" SG_ 531 LscmbbDeny_B_ActlBrk 1;
BA_ "U_B562LC_MY15_Diesel_Tx" SG_ 531 LscmbbDeny_B_ActlBrk 1;
BA_ "CrossOver_InfoCAN" SG_ 531 LscmbbDeny_B_ActlBrk 1;
BA_ "GenSigTimeoutTime_GWM" SG_ 531 PrkBrkYwLamp_D_Rq 60;
BA_ "U_CX482_CX483_MY20_Hev_Tx" SG_ 531 PrkBrkYwLamp_D_Rq 1;
BA_ "U_CX482_CX483_MY20_Gas_Tx" SG_ 531 PrkBrkYwLamp_D_Rq 1;
BA_ "U_CX482_CX483_MY20_Diesel_Tx" SG_ 531 PrkBrkYwLamp_D_Rq 1;
BA_ "U_U611_U625_MY20_Hev_Tx" SG_ 531 PrkBrkYwLamp_D_Rq 1;
BA_ "U_U611_U625_MY20_Gas_Tx" SG_ 531 PrkBrkYwLamp_D_Rq 1;
BA_ "U_U611_U625_MY20_Diesel_Tx" SG_ 531 PrkBrkYwLamp_D_Rq 1;
BA_ "U_C519_MY18_5_Gas_Tx" SG_ 531 PrkBrkYwLamp_D_Rq 1;
BA_ "U_C519_MY18_5_Diesel_Tx" SG_ 531 PrkBrkYwLamp_D_Rq 1;
BA_ "U_B562LC_MY15_Gas_Tx" SG_ 531 PrkBrkYwLamp_D_Rq 1;
BA_ "U_B562LC_MY15_Diesel_Tx" SG_ 531 PrkBrkYwLamp_D_Rq 1;
BA_ "U_B479_MY17_Gas_Rx" SG_ 531 PrkBrkYwLamp_D_Rq 1;
BA_ "CrossOver_InfoCAN" SG_ 531 PrkBrkYwLamp_D_Rq 1;
BA_ "WakeupSignal" SG_ 531 PrkBrkYwLamp_D_Rq 1;
BA_ "GenSigTimeoutTime_GWM" SG_ 531 PrkBrkRedLamp_D_Rq 60;
BA_ "U_CX482_CX483_MY20_Hev_Tx" SG_ 531 PrkBrkRedLamp_D_Rq 1;
BA_ "U_CX482_CX483_MY20_Gas_Tx" SG_ 531 PrkBrkRedLamp_D_Rq 1;
BA_ "U_CX482_CX483_MY20_Diesel_Tx" SG_ 531 PrkBrkRedLamp_D_Rq 1;
BA_ "U_U611_U625_MY20_Hev_Tx" SG_ 531 PrkBrkRedLamp_D_Rq 1;
BA_ "U_U611_U625_MY20_Gas_Tx" SG_ 531 PrkBrkRedLamp_D_Rq 1;
BA_ "U_U611_U625_MY20_Diesel_Tx" SG_ 531 PrkBrkRedLamp_D_Rq 1;
BA_ "U_C519_MY18_5_Gas_Tx" SG_ 531 PrkBrkRedLamp_D_Rq 1;
BA_ "U_C519_MY18_5_Diesel_Tx" SG_ 531 PrkBrkRedLamp_D_Rq 1;
BA_ "U_B562LC_MY15_Gas_Tx" SG_ 531 PrkBrkRedLamp_D_Rq 1;
BA_ "U_B562LC_MY15_Diesel_Tx" SG_ 531 PrkBrkRedLamp_D_Rq 1;
BA_ "U_B479_MY17_Gas_Rx" SG_ 531 PrkBrkRedLamp_D_Rq 1;
BA_ "CrossOver_InfoCAN" SG_ 531 PrkBrkRedLamp_D_Rq 1;
BA_ "WakeupSignal" SG_ 531 PrkBrkRedLamp_D_Rq 1;
BA_ "GenSigTimeoutTime_GWM" SG_ 531 VehicleStationary 60;
BA_ "U_CX482_CX483_MY20_Hev_Tx" SG_ 531 VehicleStationary 1;
BA_ "U_CX482_CX483_MY20_Gas_Tx" SG_ 531 VehicleStationary 1;
BA_ "U_CX482_CX483_MY20_Diesel_Tx" SG_ 531 VehicleStationary 1;
BA_ "U_U611_U625_MY20_Hev_Tx" SG_ 531 VehicleStationary 1;
BA_ "U_U611_U625_MY20_Gas_Tx" SG_ 531 VehicleStationary 1;
BA_ "U_U611_U625_MY20_Diesel_Tx" SG_ 531 VehicleStationary 1;
BA_ "U_B500_MY18_Diesel_Tx" SG_ 531 VehicleStationary 1;
BA_ "U_B500_MY18_Gas_Tx" SG_ 531 VehicleStationary 1;
BA_ "U_C490_MY18_Tx" SG_ 531 VehicleStationary 1;
BA_ "U_B562_MY18_Gas_Tx" SG_ 531 VehicleStationary 1;
BA_ "U_C519_MY18_5_Gas_Tx" SG_ 531 VehicleStationary 1;
BA_ "U_C519_MY18_5_Diesel_Tx" SG_ 531 VehicleStationary 1;
BA_ "U_B515_MCA_MY17_Gas_Tx" SG_ 531 VehicleStationary 1;
BA_ "U_B515_MCA_MY17_Diesel_Tx" SG_ 531 VehicleStationary 1;
BA_ "U_B479_MY17_Diesel_Tx" SG_ 531 VehicleStationary 1;
BA_ "U_B479_MY17_Gas_Tx" SG_ 531 VehicleStationary 1;
BA_ "U_B562LC_MY15_Gas_Tx" SG_ 531 VehicleStationary 1;
BA_ "U_B562LC_MY15_Diesel_Tx" SG_ 531 VehicleStationary 1;
BA_ "U_CX482_CX483_MY20_Hev_Rx" SG_ 531 VehicleStationary 1;
BA_ "U_CX482_CX483_MY20_Gas_Rx" SG_ 531 VehicleStationary 1;
BA_ "U_CX482_CX483_MY20_Diesel_Rx" SG_ 531 VehicleStationary 1;
BA_ "U_U611_U625_MY20_Hev_Rx" SG_ 531 VehicleStationary 1;
BA_ "U_U611_U625_MY20_Gas_Rx" SG_ 531 VehicleStationary 1;
BA_ "U_U611_U625_MY20_Diesel_Rx" SG_ 531 VehicleStationary 1;
BA_ "U_C519_MY18_5_Gas_Rx" SG_ 531 VehicleStationary 1;
BA_ "U_C519_MY18_5_Diesel_Rx" SG_ 531 VehicleStationary 1;
BA_ "U_B479_MY17_Diesel_Rx" SG_ 531 VehicleStationary 1;
BA_ "U_B479_MY17_Gas_Rx" SG_ 531 VehicleStationary 1;
BA_ "CrossOver_InfoCAN" SG_ 531 VehicleStationary 1;
BA_ "GenSigTimeoutTime_GWM" SG_ 531 LscmbbBrkDecel_B_Actl 60;
BA_ "U_U611_U625_MY20_Hev_Tx" SG_ 531 LscmbbBrkDecel_B_Actl 1;
BA_ "U_U611_U625_MY20_Gas_Tx" SG_ 531 LscmbbBrkDecel_B_Actl 1;
BA_ "U_U611_U625_MY20_Diesel_Tx" SG_ 531 LscmbbBrkDecel_B_Actl 1;
BA_ "U_B515_MCA_MY17_Gas_Tx" SG_ 531 LscmbbBrkDecel_B_Actl 1;
BA_ "U_B515_MCA_MY17_Diesel_Tx" SG_ 531 LscmbbBrkDecel_B_Actl 1;
BA_ "U_B562LC_MY15_Gas_Tx" SG_ 531 LscmbbBrkDecel_B_Actl 1;
BA_ "U_B562LC_MY15_Diesel_Tx" SG_ 531 LscmbbBrkDecel_B_Actl 1;
BA_ "CrossOver_InfoCAN" SG_ 531 LscmbbBrkDecel_B_Actl 1;
BA_ "GenSigTimeoutTime_GWM" SG_ 531 AbsActv_B_Actl 60;
BA_ "U_CX482_CX483_MY20_Hev_Tx" SG_ 531 AbsActv_B_Actl 1;
BA_ "U_CX482_CX483_MY20_Gas_Tx" SG_ 531 AbsActv_B_Actl 1;
BA_ "U_CX482_CX483_MY20_Diesel_Tx" SG_ 531 AbsActv_B_Actl 1;
BA_ "U_U611_U625_MY20_Hev_Tx" SG_ 531 AbsActv_B_Actl 1;
BA_ "U_U611_U625_MY20_Gas_Tx" SG_ 531 AbsActv_B_Actl 1;
BA_ "U_U611_U625_MY20_Diesel_Tx" SG_ 531 AbsActv_B_Actl 1;
BA_ "U_B500_MY18_Diesel_Tx" SG_ 531 AbsActv_B_Actl 1;
BA_ "U_B500_MY18_Gas_Tx" SG_ 531 AbsActv_B_Actl 1;
BA_ "U_C490_MY18_Tx" SG_ 531 AbsActv_B_Actl 1;
BA_ "U_B562_MY18_Gas_Tx" SG_ 531 AbsActv_B_Actl 1;
BA_ "U_C519_MY18_5_Gas_Tx" SG_ 531 AbsActv_B_Actl 1;
BA_ "U_C519_MY18_5_Diesel_Tx" SG_ 531 AbsActv_B_Actl 1;
BA_ "U_B515_MCA_MY17_Gas_Tx" SG_ 531 AbsActv_B_Actl 1;
BA_ "U_B515_MCA_MY17_Diesel_Tx" SG_ 531 AbsActv_B_Actl 1;
BA_ "U_B479_MY17_Diesel_Tx" SG_ 531 AbsActv_B_Actl 1;
BA_ "U_B479_MY17_Gas_Tx" SG_ 531 AbsActv_B_Actl 1;
BA_ "U_B562LC_MY15_Gas_Tx" SG_ 531 AbsActv_B_Actl 1;
BA_ "U_B562LC_MY15_Diesel_Tx" SG_ 531 AbsActv_B_Actl 1;
BA_ "U_B515_MCA_MY17_Gas_Rx" SG_ 531 AbsActv_B_Actl 1;
BA_ "U_B515_MCA_MY17_Diesel_Rx" SG_ 531 AbsActv_B_Actl 1;
BA_ "U_CX482_CX483_MY20_Hev_Rx" SG_ 531 AbsActv_B_Actl 1;
BA_ "U_CX482_CX483_MY20_Gas_Rx" SG_ 531 AbsActv_B_Actl 1;
BA_ "U_CX482_CX483_MY20_Diesel_Rx" SG_ 531 AbsActv_B_Actl 1;
BA_ "U_B500_MY18_Diesel_Rx" SG_ 531 AbsActv_B_Actl 1;
BA_ "U_B500_MY18_Gas_Rx" SG_ 531 AbsActv_B_Actl 1;
BA_ "U_C490_MY18_Rx" SG_ 531 AbsActv_B_Actl 1;
BA_ "U_B562_MY18_Gas_Rx" SG_ 531 AbsActv_B_Actl 1;
BA_ "U_B479_MY17_Diesel_Rx" SG_ 531 AbsActv_B_Actl 1;
BA_ "U_B479_MY17_Gas_Rx" SG_ 531 AbsActv_B_Actl 1;
BA_ "U_U611_U625_MY20_Phev_Rx" SG_ 531 AbsActv_B_Actl 1;
BA_ "U_U611_U625_MY20_Hev_Rx" SG_ 531 AbsActv_B_Actl 1;
BA_ "U_U611_U625_MY20_Gas_Rx" SG_ 531 AbsActv_B_Actl 1;
BA_ "U_U611_U625_MY20_Diesel_Rx" SG_ 531 AbsActv_B_Actl 1;
BA_ "U_C519_MY18_5_Gas_Rx" SG_ 531 AbsActv_B_Actl 1;
BA_ "U_C519_MY18_5_Diesel_Rx" SG_ 531 AbsActv_B_Actl 1;
BA_ "CrossOver_InfoCAN" SG_ 531 AbsActv_B_Actl 1;
BA_ "GenSigTimeoutTime_GWM" SG_ 531 StabCtlBrkActv_B_Actl 60;
BA_ "U_CX482_CX483_MY20_Hev_Tx" SG_ 531 StabCtlBrkActv_B_Actl 1;
BA_ "U_CX482_CX483_MY20_Gas_Tx" SG_ 531 StabCtlBrkActv_B_Actl 1;
BA_ "U_CX482_CX483_MY20_Diesel_Tx" SG_ 531 StabCtlBrkActv_B_Actl 1;
BA_ "U_U611_U625_MY20_Hev_Tx" SG_ 531 StabCtlBrkActv_B_Actl 1;
BA_ "U_U611_U625_MY20_Gas_Tx" SG_ 531 StabCtlBrkActv_B_Actl 1;
BA_ "U_U611_U625_MY20_Diesel_Tx" SG_ 531 StabCtlBrkActv_B_Actl 1;
BA_ "U_B500_MY18_Diesel_Tx" SG_ 531 StabCtlBrkActv_B_Actl 1;
BA_ "U_B500_MY18_Gas_Tx" SG_ 531 StabCtlBrkActv_B_Actl 1;
BA_ "U_C490_MY18_Tx" SG_ 531 StabCtlBrkActv_B_Actl 1;
BA_ "U_B562_MY18_Gas_Tx" SG_ 531 StabCtlBrkActv_B_Actl 1;
BA_ "U_C519_MY18_5_Gas_Tx" SG_ 531 StabCtlBrkActv_B_Actl 1;
BA_ "U_C519_MY18_5_Diesel_Tx" SG_ 531 StabCtlBrkActv_B_Actl 1;
BA_ "U_B515_MCA_MY17_Gas_Tx" SG_ 531 StabCtlBrkActv_B_Actl 1;
BA_ "U_B515_MCA_MY17_Diesel_Tx" SG_ 531 StabCtlBrkActv_B_Actl 1;
BA_ "U_B479_MY17_Diesel_Tx" SG_ 531 StabCtlBrkActv_B_Actl 1;
BA_ "U_B479_MY17_Gas_Tx" SG_ 531 StabCtlBrkActv_B_Actl 1;
BA_ "U_B562LC_MY15_Gas_Tx" SG_ 531 StabCtlBrkActv_B_Actl 1;
BA_ "U_B562LC_MY15_Diesel_Tx" SG_ 531 StabCtlBrkActv_B_Actl 1;
BA_ "U_CX482_CX483_MY20_Hev_Rx" SG_ 531 StabCtlBrkActv_B_Actl 1;
BA_ "U_CX482_CX483_MY20_Gas_Rx" SG_ 531 StabCtlBrkActv_B_Actl 1;
BA_ "U_CX482_CX483_MY20_Diesel_Rx" SG_ 531 StabCtlBrkActv_B_Actl 1;
BA_ "U_B500_MY18_Diesel_Rx" SG_ 531 StabCtlBrkActv_B_Actl 1;
BA_ "U_B500_MY18_Gas_Rx" SG_ 531 StabCtlBrkActv_B_Actl 1;
BA_ "U_B515_MCA_MY17_Gas_Rx" SG_ 531 StabCtlBrkActv_B_Actl 1;
BA_ "U_B515_MCA_MY17_Diesel_Rx" SG_ 531 StabCtlBrkActv_B_Actl 1;
BA_ "U_U611_U625_MY20_Phev_Rx" SG_ 531 StabCtlBrkActv_B_Actl 1;
BA_ "U_U611_U625_MY20_Hev_Rx" SG_ 531 StabCtlBrkActv_B_Actl 1;
BA_ "U_U611_U625_MY20_Gas_Rx" SG_ 531 StabCtlBrkActv_B_Actl 1;
BA_ "U_U611_U625_MY20_Diesel_Rx" SG_ 531 StabCtlBrkActv_B_Actl 1;
BA_ "U_C519_MY18_5_Gas_Rx" SG_ 531 StabCtlBrkActv_B_Actl 1;
BA_ "U_C519_MY18_5_Diesel_Rx" SG_ 531 StabCtlBrkActv_B_Actl 1;
BA_ "U_B479_MY17_Diesel_Rx" SG_ 531 StabCtlBrkActv_B_Actl 1;
BA_ "U_B479_MY17_Gas_Rx" SG_ 531 StabCtlBrkActv_B_Actl 1;
BA_ "CrossOver_InfoCAN" SG_ 531 StabCtlBrkActv_B_Actl 1;
BA_ "GenSigTimeoutTime_GWM" SG_ 531 CmbbBrkPrchg_B_Actl 60;
BA_ "U_CX482_CX483_MY20_Hev_Tx" SG_ 531 CmbbBrkPrchg_B_Actl 1;
BA_ "U_CX482_CX483_MY20_Gas_Tx" SG_ 531 CmbbBrkPrchg_B_Actl 1;
BA_ "U_CX482_CX483_MY20_Diesel_Tx" SG_ 531 CmbbBrkPrchg_B_Actl 1;
BA_ "U_U611_U625_MY20_Hev_Tx" SG_ 531 CmbbBrkPrchg_B_Actl 1;
BA_ "U_U611_U625_MY20_Gas_Tx" SG_ 531 CmbbBrkPrchg_B_Actl 1;
BA_ "U_U611_U625_MY20_Diesel_Tx" SG_ 531 CmbbBrkPrchg_B_Actl 1;
BA_ "U_C519_MY18_5_Gas_Tx" SG_ 531 CmbbBrkPrchg_B_Actl 1;
BA_ "U_C519_MY18_5_Diesel_Tx" SG_ 531 CmbbBrkPrchg_B_Actl 1;
BA_ "U_B515_MCA_MY17_Gas_Tx" SG_ 531 CmbbBrkPrchg_B_Actl 1;
BA_ "U_B515_MCA_MY17_Diesel_Tx" SG_ 531 CmbbBrkPrchg_B_Actl 1;
BA_ "U_B479_MY17_Diesel_Tx" SG_ 531 CmbbBrkPrchg_B_Actl 1;
BA_ "U_B479_MY17_Gas_Tx" SG_ 531 CmbbBrkPrchg_B_Actl 1;
BA_ "U_B562LC_MY15_Gas_Tx" SG_ 531 CmbbBrkPrchg_B_Actl 1;
BA_ "U_B562LC_MY15_Diesel_Tx" SG_ 531 CmbbBrkPrchg_B_Actl 1;
BA_ "U_CX482_CX483_MY20_Hev_Rx" SG_ 531 CmbbBrkPrchg_B_Actl 1;
BA_ "U_CX482_CX483_MY20_Gas_Rx" SG_ 531 CmbbBrkPrchg_B_Actl 1;
BA_ "U_CX482_CX483_MY20_Diesel_Rx" SG_ 531 CmbbBrkPrchg_B_Actl 1;
BA_ "U_U611_U625_MY20_Hev_Rx" SG_ 531 CmbbBrkPrchg_B_Actl 1;
BA_ "U_U611_U625_MY20_Gas_Rx" SG_ 531 CmbbBrkPrchg_B_Actl 1;
BA_ "U_U611_U625_MY20_Diesel_Rx" SG_ 531 CmbbBrkPrchg_B_Actl 1;
BA_ "U_C519_MY18_5_Gas_Rx" SG_ 531 CmbbBrkPrchg_B_Actl 1;
BA_ "U_C519_MY18_5_Diesel_Rx" SG_ 531 CmbbBrkPrchg_B_Actl 1;
BA_ "U_B479_MY17_Diesel_Rx" SG_ 531 CmbbBrkPrchg_B_Actl 1;
BA_ "U_B479_MY17_Gas_Rx" SG_ 531 CmbbBrkPrchg_B_Actl 1;
BA_ "CrossOver_InfoCAN" SG_ 531 CmbbBrkPrchg_B_Actl 1;
BA_ "GenSigTimeoutTime_GWM" SG_ 531 CmbbBrkDecel_B_Actl 60;
BA_ "U_CX482_CX483_MY20_Hev_Tx" SG_ 531 CmbbBrkDecel_B_Actl 1;
BA_ "U_CX482_CX483_MY20_Gas_Tx" SG_ 531 CmbbBrkDecel_B_Actl 1;
BA_ "U_CX482_CX483_MY20_Diesel_Tx" SG_ 531 CmbbBrkDecel_B_Actl 1;
BA_ "U_U611_U625_MY20_Hev_Tx" SG_ 531 CmbbBrkDecel_B_Actl 1;
BA_ "U_U611_U625_MY20_Gas_Tx" SG_ 531 CmbbBrkDecel_B_Actl 1;
BA_ "U_U611_U625_MY20_Diesel_Tx" SG_ 531 CmbbBrkDecel_B_Actl 1;
BA_ "U_C519_MY18_5_Gas_Tx" SG_ 531 CmbbBrkDecel_B_Actl 1;
BA_ "U_C519_MY18_5_Diesel_Tx" SG_ 531 CmbbBrkDecel_B_Actl 1;
BA_ "U_B515_MCA_MY17_Gas_Tx" SG_ 531 CmbbBrkDecel_B_Actl 1;
BA_ "U_B515_MCA_MY17_Diesel_Tx" SG_ 531 CmbbBrkDecel_B_Actl 1;
BA_ "U_B479_MY17_Diesel_Tx" SG_ 531 CmbbBrkDecel_B_Actl 1;
BA_ "U_B479_MY17_Gas_Tx" SG_ 531 CmbbBrkDecel_B_Actl 1;
BA_ "U_B562LC_MY15_Gas_Tx" SG_ 531 CmbbBrkDecel_B_Actl 1;
BA_ "U_B562LC_MY15_Diesel_Tx" SG_ 531 CmbbBrkDecel_B_Actl 1;
BA_ "U_CX482_CX483_MY20_Hev_Rx" SG_ 531 CmbbBrkDecel_B_Actl 1;
BA_ "U_CX482_CX483_MY20_Gas_Rx" SG_ 531 CmbbBrkDecel_B_Actl 1;
BA_ "U_CX482_CX483_MY20_Diesel_Rx" SG_ 531 CmbbBrkDecel_B_Actl 1;
BA_ "U_U611_U625_MY20_Hev_Rx" SG_ 531 CmbbBrkDecel_B_Actl 1;
BA_ "U_U611_U625_MY20_Gas_Rx" SG_ 531 CmbbBrkDecel_B_Actl 1;
BA_ "U_U611_U625_MY20_Diesel_Rx" SG_ 531 CmbbBrkDecel_B_Actl 1;
BA_ "U_C519_MY18_5_Gas_Rx" SG_ 531 CmbbBrkDecel_B_Actl 1;
BA_ "U_C519_MY18_5_Diesel_Rx" SG_ 531 CmbbBrkDecel_B_Actl 1;
BA_ "U_B479_MY17_Diesel_Rx" SG_ 531 CmbbBrkDecel_B_Actl 1;
BA_ "U_B479_MY17_Gas_Rx" SG_ 531 CmbbBrkDecel_B_Actl 1;
BA_ "CrossOver_InfoCAN" SG_ 531 CmbbBrkDecel_B_Actl 1;
BA_ "GenSigTimeoutTime_GWM" SG_ 531 CmbbBaSensInc_B_Actl 60;
BA_ "U_CX482_CX483_MY20_Hev_Tx" SG_ 531 CmbbBaSensInc_B_Actl 1;
BA_ "U_CX482_CX483_MY20_Gas_Tx" SG_ 531 CmbbBaSensInc_B_Actl 1;
BA_ "U_CX482_CX483_MY20_Diesel_Tx" SG_ 531 CmbbBaSensInc_B_Actl 1;
BA_ "U_U611_U625_MY20_Hev_Tx" SG_ 531 CmbbBaSensInc_B_Actl 1;
BA_ "U_U611_U625_MY20_Gas_Tx" SG_ 531 CmbbBaSensInc_B_Actl 1;
BA_ "U_U611_U625_MY20_Diesel_Tx" SG_ 531 CmbbBaSensInc_B_Actl 1;
BA_ "U_C519_MY18_5_Gas_Tx" SG_ 531 CmbbBaSensInc_B_Actl 1;
BA_ "U_C519_MY18_5_Diesel_Tx" SG_ 531 CmbbBaSensInc_B_Actl 1;
BA_ "U_B515_MCA_MY17_Gas_Tx" SG_ 531 CmbbBaSensInc_B_Actl 1;
BA_ "U_B515_MCA_MY17_Diesel_Tx" SG_ 531 CmbbBaSensInc_B_Actl 1;
BA_ "U_B479_MY17_Diesel_Tx" SG_ 531 CmbbBaSensInc_B_Actl 1;
BA_ "U_B479_MY17_Gas_Tx" SG_ 531 CmbbBaSensInc_B_Actl 1;
BA_ "U_B562LC_MY15_Gas_Tx" SG_ 531 CmbbBaSensInc_B_Actl 1;
BA_ "U_B562LC_MY15_Diesel_Tx" SG_ 531 CmbbBaSensInc_B_Actl 1;
BA_ "U_CX482_CX483_MY20_Hev_Rx" SG_ 531 CmbbBaSensInc_B_Actl 1;
BA_ "U_CX482_CX483_MY20_Gas_Rx" SG_ 531 CmbbBaSensInc_B_Actl 1;
BA_ "U_CX482_CX483_MY20_Diesel_Rx" SG_ 531 CmbbBaSensInc_B_Actl 1;
BA_ "U_U611_U625_MY20_Hev_Rx" SG_ 531 CmbbBaSensInc_B_Actl 1;
BA_ "U_U611_U625_MY20_Gas_Rx" SG_ 531 CmbbBaSensInc_B_Actl 1;
BA_ "U_U611_U625_MY20_Diesel_Rx" SG_ 531 CmbbBaSensInc_B_Actl 1;
BA_ "U_C519_MY18_5_Gas_Rx" SG_ 531 CmbbBaSensInc_B_Actl 1;
BA_ "U_C519_MY18_5_Diesel_Rx" SG_ 531 CmbbBaSensInc_B_Actl 1;
BA_ "U_B479_MY17_Diesel_Rx" SG_ 531 CmbbBaSensInc_B_Actl 1;
BA_ "U_B479_MY17_Gas_Rx" SG_ 531 CmbbBaSensInc_B_Actl 1;
BA_ "CrossOver_InfoCAN" SG_ 531 CmbbBaSensInc_B_Actl 1;
BA_ "GenSigTimeoutTime_GWM" SG_ 531 AccBrkWarm_B_Actl 60;
BA_ "U_CX482_CX483_MY20_Hev_Tx" SG_ 531 AccBrkWarm_B_Actl 1;
BA_ "U_CX482_CX483_MY20_Gas_Tx" SG_ 531 AccBrkWarm_B_Actl 1;
BA_ "U_CX482_CX483_MY20_Diesel_Tx" SG_ 531 AccBrkWarm_B_Actl 1;
BA_ "U_U611_U625_MY20_Hev_Tx" SG_ 531 AccBrkWarm_B_Actl 1;
BA_ "U_U611_U625_MY20_Gas_Tx" SG_ 531 AccBrkWarm_B_Actl 1;
BA_ "U_U611_U625_MY20_Diesel_Tx" SG_ 531 AccBrkWarm_B_Actl 1;
BA_ "U_C519_MY18_5_Gas_Tx" SG_ 531 AccBrkWarm_B_Actl 1;
BA_ "U_C519_MY18_5_Diesel_Tx" SG_ 531 AccBrkWarm_B_Actl 1;
BA_ "U_B515_MCA_MY17_Gas_Tx" SG_ 531 AccBrkWarm_B_Actl 1;
BA_ "U_B515_MCA_MY17_Diesel_Tx" SG_ 531 AccBrkWarm_B_Actl 1;
BA_ "U_B479_MY17_Diesel_Tx" SG_ 531 AccBrkWarm_B_Actl 1;
BA_ "U_B479_MY17_Gas_Tx" SG_ 531 AccBrkWarm_B_Actl 1;
BA_ "U_B562LC_MY15_Gas_Tx" SG_ 531 AccBrkWarm_B_Actl 1;
BA_ "U_B562LC_MY15_Diesel_Tx" SG_ 531 AccBrkWarm_B_Actl 1;
BA_ "U_CX482_CX483_MY20_Hev_Rx" SG_ 531 AccBrkWarm_B_Actl 1;
BA_ "U_CX482_CX483_MY20_Gas_Rx" SG_ 531 AccBrkWarm_B_Actl 1;
BA_ "U_CX482_CX483_MY20_Diesel_Rx" SG_ 531 AccBrkWarm_B_Actl 1;
BA_ "U_U611_U625_MY20_Hev_Rx" SG_ 531 AccBrkWarm_B_Actl 1;
BA_ "U_U611_U625_MY20_Gas_Rx" SG_ 531 AccBrkWarm_B_Actl 1;
BA_ "U_U611_U625_MY20_Diesel_Rx" SG_ 531 AccBrkWarm_B_Actl 1;
BA_ "U_C519_MY18_5_Gas_Rx" SG_ 531 AccBrkWarm_B_Actl 1;
BA_ "U_C519_MY18_5_Diesel_Rx" SG_ 531 AccBrkWarm_B_Actl 1;
BA_ "U_B479_MY17_Diesel_Rx" SG_ 531 AccBrkWarm_B_Actl 1;
BA_ "U_B479_MY17_Gas_Rx" SG_ 531 AccBrkWarm_B_Actl 1;
BA_ "CrossOver_InfoCAN" SG_ 531 AccBrkWarm_B_Actl 1;
BA_ "GenSigTimeoutTime_GWM" SG_ 531 AccBrkTotTqMn_B_Actl 60;
BA_ "U_CX482_CX483_MY20_Hev_Tx" SG_ 531 AccBrkTotTqMn_B_Actl 1;
BA_ "U_CX482_CX483_MY20_Gas_Tx" SG_ 531 AccBrkTotTqMn_B_Actl 1;
BA_ "U_CX482_CX483_MY20_Diesel_Tx" SG_ 531 AccBrkTotTqMn_B_Actl 1;
BA_ "U_U611_U625_MY20_Hev_Tx" SG_ 531 AccBrkTotTqMn_B_Actl 1;
BA_ "U_U611_U625_MY20_Gas_Tx" SG_ 531 AccBrkTotTqMn_B_Actl 1;
BA_ "U_U611_U625_MY20_Diesel_Tx" SG_ 531 AccBrkTotTqMn_B_Actl 1;
BA_ "U_C519_MY18_5_Gas_Tx" SG_ 531 AccBrkTotTqMn_B_Actl 1;
BA_ "U_C519_MY18_5_Diesel_Tx" SG_ 531 AccBrkTotTqMn_B_Actl 1;
BA_ "U_B515_MCA_MY17_Gas_Tx" SG_ 531 AccBrkTotTqMn_B_Actl 1;
BA_ "U_B515_MCA_MY17_Diesel_Tx" SG_ 531 AccBrkTotTqMn_B_Actl 1;
BA_ "U_B479_MY17_Diesel_Tx" SG_ 531 AccBrkTotTqMn_B_Actl 1;
BA_ "U_B479_MY17_Gas_Tx" SG_ 531 AccBrkTotTqMn_B_Actl 1;
BA_ "U_B562LC_MY15_Gas_Tx" SG_ 531 AccBrkTotTqMn_B_Actl 1;
BA_ "U_B562LC_MY15_Diesel_Tx" SG_ 531 AccBrkTotTqMn_B_Actl 1;
BA_ "U_CX482_CX483_MY20_Hev_Rx" SG_ 531 AccBrkTotTqMn_B_Actl 1;
BA_ "U_CX482_CX483_MY20_Gas_Rx" SG_ 531 AccBrkTotTqMn_B_Actl 1;
BA_ "U_CX482_CX483_MY20_Diesel_Rx" SG_ 531 AccBrkTotTqMn_B_Actl 1;
BA_ "U_U611_U625_MY20_Hev_Rx" SG_ 531 AccBrkTotTqMn_B_Actl 1;
BA_ "U_U611_U625_MY20_Gas_Rx" SG_ 531 AccBrkTotTqMn_B_Actl 1;
BA_ "U_U611_U625_MY20_Diesel_Rx" SG_ 531 AccBrkTotTqMn_B_Actl 1;
BA_ "U_C519_MY18_5_Gas_Rx" SG_ 531 AccBrkTotTqMn_B_Actl 1;
BA_ "U_C519_MY18_5_Diesel_Rx" SG_ 531 AccBrkTotTqMn_B_Actl 1;
BA_ "U_B479_MY17_Diesel_Rx" SG_ 531 AccBrkTotTqMn_B_Actl 1;
BA_ "U_B479_MY17_Gas_Rx" SG_ 531 AccBrkTotTqMn_B_Actl 1;
BA_ "CrossOver_InfoCAN" SG_ 531 AccBrkTotTqMn_B_Actl 1;
BA_ "GenSigTimeoutTime_GWM" SG_ 531 AccBrkPrchgActv_B_Actl 60;
BA_ "U_CX482_CX483_MY20_Hev_Tx" SG_ 531 AccBrkPrchgActv_B_Actl 1;
BA_ "U_CX482_CX483_MY20_Gas_Tx" SG_ 531 AccBrkPrchgActv_B_Actl 1;
BA_ "U_CX482_CX483_MY20_Diesel_Tx" SG_ 531 AccBrkPrchgActv_B_Actl 1;
BA_ "U_U611_U625_MY20_Hev_Tx" SG_ 531 AccBrkPrchgActv_B_Actl 1;
BA_ "U_U611_U625_MY20_Gas_Tx" SG_ 531 AccBrkPrchgActv_B_Actl 1;
BA_ "U_U611_U625_MY20_Diesel_Tx" SG_ 531 AccBrkPrchgActv_B_Actl 1;
BA_ "U_C519_MY18_5_Gas_Tx" SG_ 531 AccBrkPrchgActv_B_Actl 1;
BA_ "U_C519_MY18_5_Diesel_Tx" SG_ 531 AccBrkPrchgActv_B_Actl 1;
BA_ "U_B515_MCA_MY17_Gas_Tx" SG_ 531 AccBrkPrchgActv_B_Actl 1;
BA_ "U_B515_MCA_MY17_Diesel_Tx" SG_ 531 AccBrkPrchgActv_B_Actl 1;
BA_ "U_B479_MY17_Diesel_Tx" SG_ 531 AccBrkPrchgActv_B_Actl 1;
BA_ "U_B479_MY17_Gas_Tx" SG_ 531 AccBrkPrchgActv_B_Actl 1;
BA_ "U_B562LC_MY15_Gas_Tx" SG_ 531 AccBrkPrchgActv_B_Actl 1;
BA_ "U_B562LC_MY15_Diesel_Tx" SG_ 531 AccBrkPrchgActv_B_Actl 1;
BA_ "U_CX482_CX483_MY20_Hev_Rx" SG_ 531 AccBrkPrchgActv_B_Actl 1;
BA_ "U_CX482_CX483_MY20_Gas_Rx" SG_ 531 AccBrkPrchgActv_B_Actl 1;
BA_ "U_CX482_CX483_MY20_Diesel_Rx" SG_ 531 AccBrkPrchgActv_B_Actl 1;
BA_ "U_U611_U625_MY20_Hev_Rx" SG_ 531 AccBrkPrchgActv_B_Actl 1;
BA_ "U_U611_U625_MY20_Gas_Rx" SG_ 531 AccBrkPrchgActv_B_Actl 1;
BA_ "U_U611_U625_MY20_Diesel_Rx" SG_ 531 AccBrkPrchgActv_B_Actl 1;
BA_ "U_C519_MY18_5_Gas_Rx" SG_ 531 AccBrkPrchgActv_B_Actl 1;
BA_ "U_C519_MY18_5_Diesel_Rx" SG_ 531 AccBrkPrchgActv_B_Actl 1;
BA_ "U_B479_MY17_Diesel_Rx" SG_ 531 AccBrkPrchgActv_B_Actl 1;
BA_ "U_B479_MY17_Gas_Rx" SG_ 531 AccBrkPrchgActv_B_Actl 1;
BA_ "CrossOver_InfoCAN" SG_ 531 AccBrkPrchgActv_B_Actl 1;
BA_ "GenSigTimeoutTime_GWM" SG_ 531 AccBrkDis_B_Actl 60;
BA_ "U_CX482_CX483_MY20_Hev_Tx" SG_ 531 AccBrkDis_B_Actl 1;
BA_ "U_CX482_CX483_MY20_Gas_Tx" SG_ 531 AccBrkDis_B_Actl 1;
BA_ "U_CX482_CX483_MY20_Diesel_Tx" SG_ 531 AccBrkDis_B_Actl 1;
BA_ "U_U611_U625_MY20_Hev_Tx" SG_ 531 AccBrkDis_B_Actl 1;
BA_ "U_U611_U625_MY20_Gas_Tx" SG_ 531 AccBrkDis_B_Actl 1;
BA_ "U_U611_U625_MY20_Diesel_Tx" SG_ 531 AccBrkDis_B_Actl 1;
BA_ "U_C519_MY18_5_Gas_Tx" SG_ 531 AccBrkDis_B_Actl 1;
BA_ "U_C519_MY18_5_Diesel_Tx" SG_ 531 AccBrkDis_B_Actl 1;
BA_ "U_B515_MCA_MY17_Gas_Tx" SG_ 531 AccBrkDis_B_Actl 1;
BA_ "U_B515_MCA_MY17_Diesel_Tx" SG_ 531 AccBrkDis_B_Actl 1;
BA_ "U_B479_MY17_Diesel_Tx" SG_ 531 AccBrkDis_B_Actl 1;
BA_ "U_B479_MY17_Gas_Tx" SG_ 531 AccBrkDis_B_Actl 1;
BA_ "U_B562LC_MY15_Gas_Tx" SG_ 531 AccBrkDis_B_Actl 1;
BA_ "U_B562LC_MY15_Diesel_Tx" SG_ 531 AccBrkDis_B_Actl 1;
BA_ "U_CX482_CX483_MY20_Hev_Rx" SG_ 531 AccBrkDis_B_Actl 1;
BA_ "U_CX482_CX483_MY20_Gas_Rx" SG_ 531 AccBrkDis_B_Actl 1;
BA_ "U_CX482_CX483_MY20_Diesel_Rx" SG_ 531 AccBrkDis_B_Actl 1;
BA_ "U_U611_U625_MY20_Hev_Rx" SG_ 531 AccBrkDis_B_Actl 1;
BA_ "U_U611_U625_MY20_Gas_Rx" SG_ 531 AccBrkDis_B_Actl 1;
BA_ "U_U611_U625_MY20_Diesel_Rx" SG_ 531 AccBrkDis_B_Actl 1;
BA_ "U_C519_MY18_5_Gas_Rx" SG_ 531 AccBrkDis_B_Actl 1;
BA_ "U_C519_MY18_5_Diesel_Rx" SG_ 531 AccBrkDis_B_Actl 1;
BA_ "U_B479_MY17_Diesel_Rx" SG_ 531 AccBrkDis_B_Actl 1;
BA_ "U_B479_MY17_Gas_Rx" SG_ 531 AccBrkDis_B_Actl 1;
BA_ "CrossOver_InfoCAN" SG_ 531 AccBrkDis_B_Actl 1;
BA_ "GenSigTimeoutTime_GWM" SG_ 531 AccBrkDeny_B_Actl 60;
BA_ "U_CX482_CX483_MY20_Hev_Tx" SG_ 531 AccBrkDeny_B_Actl 1;
BA_ "U_CX482_CX483_MY20_Gas_Tx" SG_ 531 AccBrkDeny_B_Actl 1;
BA_ "U_CX482_CX483_MY20_Diesel_Tx" SG_ 531 AccBrkDeny_B_Actl 1;
BA_ "U_U611_U625_MY20_Hev_Tx" SG_ 531 AccBrkDeny_B_Actl 1;
BA_ "U_U611_U625_MY20_Gas_Tx" SG_ 531 AccBrkDeny_B_Actl 1;
BA_ "U_U611_U625_MY20_Diesel_Tx" SG_ 531 AccBrkDeny_B_Actl 1;
BA_ "U_C519_MY18_5_Gas_Tx" SG_ 531 AccBrkDeny_B_Actl 1;
BA_ "U_C519_MY18_5_Diesel_Tx" SG_ 531 AccBrkDeny_B_Actl 1;
BA_ "U_B515_MCA_MY17_Gas_Tx" SG_ 531 AccBrkDeny_B_Actl 1;
BA_ "U_B515_MCA_MY17_Diesel_Tx" SG_ 531 AccBrkDeny_B_Actl 1;
BA_ "U_B479_MY17_Diesel_Tx" SG_ 531 AccBrkDeny_B_Actl 1;
BA_ "U_B479_MY17_Gas_Tx" SG_ 531 AccBrkDeny_B_Actl 1;
BA_ "U_B562LC_MY15_Gas_Tx" SG_ 531 AccBrkDeny_B_Actl 1;
BA_ "U_B562LC_MY15_Diesel_Tx" SG_ 531 AccBrkDeny_B_Actl 1;
BA_ "U_CX482_CX483_MY20_Hev_Rx" SG_ 531 AccBrkDeny_B_Actl 1;
BA_ "U_CX482_CX483_MY20_Gas_Rx" SG_ 531 AccBrkDeny_B_Actl 1;
BA_ "U_CX482_CX483_MY20_Diesel_Rx" SG_ 531 AccBrkDeny_B_Actl 1;
BA_ "U_U611_U625_MY20_Hev_Rx" SG_ 531 AccBrkDeny_B_Actl 1;
BA_ "U_U611_U625_MY20_Gas_Rx" SG_ 531 AccBrkDeny_B_Actl 1;
BA_ "U_U611_U625_MY20_Diesel_Rx" SG_ 531 AccBrkDeny_B_Actl 1;
BA_ "U_C519_MY18_5_Gas_Rx" SG_ 531 AccBrkDeny_B_Actl 1;
BA_ "U_C519_MY18_5_Diesel_Rx" SG_ 531 AccBrkDeny_B_Actl 1;
BA_ "U_B479_MY17_Diesel_Rx" SG_ 531 AccBrkDeny_B_Actl 1;
BA_ "U_B479_MY17_Gas_Rx" SG_ 531 AccBrkDeny_B_Actl 1;
BA_ "CrossOver_InfoCAN" SG_ 531 AccBrkDeny_B_Actl 1;
BA_ "GenSigTimeoutTime_GWM" SG_ 531 AccBrkActv_B_Actl 60;
BA_ "U_CX482_CX483_MY20_Hev_Tx" SG_ 531 AccBrkActv_B_Actl 1;
BA_ "U_CX482_CX483_MY20_Gas_Tx" SG_ 531 AccBrkActv_B_Actl 1;
BA_ "U_CX482_CX483_MY20_Diesel_Tx" SG_ 531 AccBrkActv_B_Actl 1;
BA_ "U_U611_U625_MY20_Hev_Tx" SG_ 531 AccBrkActv_B_Actl 1;
BA_ "U_U611_U625_MY20_Gas_Tx" SG_ 531 AccBrkActv_B_Actl 1;
BA_ "U_U611_U625_MY20_Diesel_Tx" SG_ 531 AccBrkActv_B_Actl 1;
BA_ "U_C519_MY18_5_Gas_Tx" SG_ 531 AccBrkActv_B_Actl 1;
BA_ "U_C519_MY18_5_Diesel_Tx" SG_ 531 AccBrkActv_B_Actl 1;
BA_ "U_B515_MCA_MY17_Gas_Tx" SG_ 531 AccBrkActv_B_Actl 1;
BA_ "U_B515_MCA_MY17_Diesel_Tx" SG_ 531 AccBrkActv_B_Actl 1;
BA_ "U_B479_MY17_Diesel_Tx" SG_ 531 AccBrkActv_B_Actl 1;
BA_ "U_B479_MY17_Gas_Tx" SG_ 531 AccBrkActv_B_Actl 1;
BA_ "U_B562LC_MY15_Gas_Tx" SG_ 531 AccBrkActv_B_Actl 1;
BA_ "U_B562LC_MY15_Diesel_Tx" SG_ 531 AccBrkActv_B_Actl 1;
BA_ "U_CX482_CX483_MY20_Hev_Rx" SG_ 531 AccBrkActv_B_Actl 1;
BA_ "U_CX482_CX483_MY20_Gas_Rx" SG_ 531 AccBrkActv_B_Actl 1;
BA_ "U_CX482_CX483_MY20_Diesel_Rx" SG_ 531 AccBrkActv_B_Actl 1;
BA_ "U_U611_U625_MY20_Hev_Rx" SG_ 531 AccBrkActv_B_Actl 1;
BA_ "U_U611_U625_MY20_Gas_Rx" SG_ 531 AccBrkActv_B_Actl 1;
BA_ "U_U611_U625_MY20_Diesel_Rx" SG_ 531 AccBrkActv_B_Actl 1;
BA_ "U_C519_MY18_5_Gas_Rx" SG_ 531 AccBrkActv_B_Actl 1;
BA_ "U_C519_MY18_5_Diesel_Rx" SG_ 531 AccBrkActv_B_Actl 1;
BA_ "U_B479_MY17_Diesel_Rx" SG_ 531 AccBrkActv_B_Actl 1;
BA_ "U_B479_MY17_Gas_Rx" SG_ 531 AccBrkActv_B_Actl 1;
BA_ "CrossOver_InfoCAN" SG_ 531 AccBrkActv_B_Actl 1;
BA_ "GenSigTimeoutTime_GWM" SG_ 531 PrplDrgCtlActv_B_Actl 60;
BA_ "U_CX482_CX483_MY20_Hev_Tx" SG_ 531 PrplDrgCtlActv_B_Actl 1;
BA_ "U_CX482_CX483_MY20_Gas_Tx" SG_ 531 PrplDrgCtlActv_B_Actl 1;
BA_ "U_CX482_CX483_MY20_Diesel_Tx" SG_ 531 PrplDrgCtlActv_B_Actl 1;
BA_ "U_U611_U625_MY20_Hev_Tx" SG_ 531 PrplDrgCtlActv_B_Actl 1;
BA_ "U_U611_U625_MY20_Gas_Tx" SG_ 531 PrplDrgCtlActv_B_Actl 1;
BA_ "U_U611_U625_MY20_Diesel_Tx" SG_ 531 PrplDrgCtlActv_B_Actl 1;
BA_ "U_B500_MY18_Diesel_Tx" SG_ 531 PrplDrgCtlActv_B_Actl 1;
BA_ "U_B500_MY18_Gas_Tx" SG_ 531 PrplDrgCtlActv_B_Actl 1;
BA_ "U_C519_MY18_5_Gas_Tx" SG_ 531 PrplDrgCtlActv_B_Actl 1;
BA_ "U_C519_MY18_5_Diesel_Tx" SG_ 531 PrplDrgCtlActv_B_Actl 1;
BA_ "U_B515_MCA_MY17_Gas_Tx" SG_ 531 PrplDrgCtlActv_B_Actl 1;
BA_ "U_B515_MCA_MY17_Diesel_Tx" SG_ 531 PrplDrgCtlActv_B_Actl 1;
BA_ "U_B479_MY17_Diesel_Tx" SG_ 531 PrplDrgCtlActv_B_Actl 1;
BA_ "U_B479_MY17_Gas_Tx" SG_ 531 PrplDrgCtlActv_B_Actl 1;
BA_ "U_B562LC_MY15_Gas_Tx" SG_ 531 PrplDrgCtlActv_B_Actl 1;
BA_ "U_B562LC_MY15_Diesel_Tx" SG_ 531 PrplDrgCtlActv_B_Actl 1;
BA_ "CrossOver_InfoCAN" SG_ 531 PrplDrgCtlActv_B_Actl 1;
BA_ "GenSigTimeoutTime_GWM" SG_ 531 PrplWhlTot_Tq_RqMx 60;
BA_ "U_CX482_CX483_MY20_Hev_Tx" SG_ 531 PrplWhlTot_Tq_RqMx 1;
BA_ "U_CX482_CX483_MY20_Gas_Tx" SG_ 531 PrplWhlTot_Tq_RqMx 1;
BA_ "U_CX482_CX483_MY20_Diesel_Tx" SG_ 531 PrplWhlTot_Tq_RqMx 1;
BA_ "U_U611_U625_MY20_Hev_Tx" SG_ 531 PrplWhlTot_Tq_RqMx 1;
BA_ "U_U611_U625_MY20_Gas_Tx" SG_ 531 PrplWhlTot_Tq_RqMx 1;
BA_ "U_U611_U625_MY20_Diesel_Tx" SG_ 531 PrplWhlTot_Tq_RqMx 1;
BA_ "U_B500_MY18_Diesel_Tx" SG_ 531 PrplWhlTot_Tq_RqMx 1;
BA_ "U_B500_MY18_Gas_Tx" SG_ 531 PrplWhlTot_Tq_RqMx 1;
BA_ "U_C490_MY18_Tx" SG_ 531 PrplWhlTot_Tq_RqMx 1;
BA_ "U_C519_MY18_5_Gas_Tx" SG_ 531 PrplWhlTot_Tq_RqMx 1;
BA_ "U_C519_MY18_5_Diesel_Tx" SG_ 531 PrplWhlTot_Tq_RqMx 1;
BA_ "U_B515_MCA_MY17_Gas_Tx" SG_ 531 PrplWhlTot_Tq_RqMx 1;
BA_ "U_B515_MCA_MY17_Diesel_Tx" SG_ 531 PrplWhlTot_Tq_RqMx 1;
BA_ "U_B479_MY17_Diesel_Tx" SG_ 531 PrplWhlTot_Tq_RqMx 1;
BA_ "U_B479_MY17_Gas_Tx" SG_ 531 PrplWhlTot_Tq_RqMx 1;
BA_ "U_B562LC_MY15_Gas_Tx" SG_ 531 PrplWhlTot_Tq_RqMx 1;
BA_ "U_B562LC_MY15_Diesel_Tx" SG_ 531 PrplWhlTot_Tq_RqMx 1;
BA_ "CrossOver_InfoCAN" SG_ 531 PrplWhlTot_Tq_RqMx 1;
BA_ "GenSigTimeoutTime_GWM" SG_ 531 LscmbbBaSensInc_B_Actl 60;
BA_ "U_U611_U625_MY20_Hev_Tx" SG_ 531 LscmbbBaSensInc_B_Actl 1;
BA_ "U_U611_U625_MY20_Gas_Tx" SG_ 531 LscmbbBaSensInc_B_Actl 1;
BA_ "U_U611_U625_MY20_Diesel_Tx" SG_ 531 LscmbbBaSensInc_B_Actl 1;
BA_ "U_B515_MCA_MY17_Gas_Tx" SG_ 531 LscmbbBaSensInc_B_Actl 1;
BA_ "U_B515_MCA_MY17_Diesel_Tx" SG_ 531 LscmbbBaSensInc_B_Actl 1;
BA_ "U_B562LC_MY15_Gas_Tx" SG_ 531 LscmbbBaSensInc_B_Actl 1;
BA_ "U_B562LC_MY15_Diesel_Tx" SG_ 531 LscmbbBaSensInc_B_Actl 1;
BA_ "CrossOver_InfoCAN" SG_ 531 LscmbbBaSensInc_B_Actl 1;
BA_ "GenSigTimeoutTime_GWM" SG_ 531 CmbbBrkDis_B_Actl 60;
BA_ "U_CX482_CX483_MY20_Hev_Tx" SG_ 531 CmbbBrkDis_B_Actl 1;
BA_ "U_CX482_CX483_MY20_Gas_Tx" SG_ 531 CmbbBrkDis_B_Actl 1;
BA_ "U_CX482_CX483_MY20_Diesel_Tx" SG_ 531 CmbbBrkDis_B_Actl 1;
BA_ "U_U611_U625_MY20_Hev_Tx" SG_ 531 CmbbBrkDis_B_Actl 1;
BA_ "U_U611_U625_MY20_Gas_Tx" SG_ 531 CmbbBrkDis_B_Actl 1;
BA_ "U_U611_U625_MY20_Diesel_Tx" SG_ 531 CmbbBrkDis_B_Actl 1;
BA_ "U_C519_MY18_5_Gas_Tx" SG_ 531 CmbbBrkDis_B_Actl 1;
BA_ "U_C519_MY18_5_Diesel_Tx" SG_ 531 CmbbBrkDis_B_Actl 1;
BA_ "U_B515_MCA_MY17_Gas_Tx" SG_ 531 CmbbBrkDis_B_Actl 1;
BA_ "U_B515_MCA_MY17_Diesel_Tx" SG_ 531 CmbbBrkDis_B_Actl 1;
BA_ "U_B479_MY17_Diesel_Tx" SG_ 531 CmbbBrkDis_B_Actl 1;
BA_ "U_B479_MY17_Gas_Tx" SG_ 531 CmbbBrkDis_B_Actl 1;
BA_ "U_B562LC_MY15_Gas_Tx" SG_ 531 CmbbBrkDis_B_Actl 1;
BA_ "U_B562LC_MY15_Diesel_Tx" SG_ 531 CmbbBrkDis_B_Actl 1;
BA_ "U_U611_U625_MY20_Phev_Rx" SG_ 531 CmbbBrkDis_B_Actl 1;
BA_ "U_CX482_CX483_MY20_Hev_Rx" SG_ 531 CmbbBrkDis_B_Actl 1;
BA_ "U_CX482_CX483_MY20_Gas_Rx" SG_ 531 CmbbBrkDis_B_Actl 1;
BA_ "U_CX482_CX483_MY20_Diesel_Rx" SG_ 531 CmbbBrkDis_B_Actl 1;
BA_ "U_U611_U625_MY20_Hev_Rx" SG_ 531 CmbbBrkDis_B_Actl 1;
BA_ "U_U611_U625_MY20_Gas_Rx" SG_ 531 CmbbBrkDis_B_Actl 1;
BA_ "U_U611_U625_MY20_Diesel_Rx" SG_ 531 CmbbBrkDis_B_Actl 1;
BA_ "U_C519_MY18_5_Gas_Rx" SG_ 531 CmbbBrkDis_B_Actl 1;
BA_ "U_C519_MY18_5_Diesel_Rx" SG_ 531 CmbbBrkDis_B_Actl 1;
BA_ "U_B479_MY17_Diesel_Rx" SG_ 531 CmbbBrkDis_B_Actl 1;
BA_ "U_B479_MY17_Gas_Rx" SG_ 531 CmbbBrkDis_B_Actl 1;
BA_ "CrossOver_InfoCAN" SG_ 531 CmbbBrkDis_B_Actl 1;
BA_ "GenSigTimeoutTime_GWM" SG_ 531 CmbbDeny_B_ActlBrk 60;
BA_ "U_CX482_CX483_MY20_Hev_Tx" SG_ 531 CmbbDeny_B_ActlBrk 1;
BA_ "U_CX482_CX483_MY20_Gas_Tx" SG_ 531 CmbbDeny_B_ActlBrk 1;
BA_ "U_CX482_CX483_MY20_Diesel_Tx" SG_ 531 CmbbDeny_B_ActlBrk 1;
BA_ "U_U611_U625_MY20_Hev_Tx" SG_ 531 CmbbDeny_B_ActlBrk 1;
BA_ "U_U611_U625_MY20_Gas_Tx" SG_ 531 CmbbDeny_B_ActlBrk 1;
BA_ "U_U611_U625_MY20_Diesel_Tx" SG_ 531 CmbbDeny_B_ActlBrk 1;
BA_ "U_C519_MY18_5_Gas_Tx" SG_ 531 CmbbDeny_B_ActlBrk 1;
BA_ "U_C519_MY18_5_Diesel_Tx" SG_ 531 CmbbDeny_B_ActlBrk 1;
BA_ "U_B515_MCA_MY17_Gas_Tx" SG_ 531 CmbbDeny_B_ActlBrk 1;
BA_ "U_B515_MCA_MY17_Diesel_Tx" SG_ 531 CmbbDeny_B_ActlBrk 1;
BA_ "U_B479_MY17_Diesel_Tx" SG_ 531 CmbbDeny_B_ActlBrk 1;
BA_ "U_B479_MY17_Gas_Tx" SG_ 531 CmbbDeny_B_ActlBrk 1;
BA_ "U_B562LC_MY15_Gas_Tx" SG_ 531 CmbbDeny_B_ActlBrk 1;
BA_ "U_B562LC_MY15_Diesel_Tx" SG_ 531 CmbbDeny_B_ActlBrk 1;
BA_ "U_U611_U625_MY20_Phev_Rx" SG_ 531 CmbbDeny_B_ActlBrk 1;
BA_ "U_CX482_CX483_MY20_Hev_Rx" SG_ 531 CmbbDeny_B_ActlBrk 1;
BA_ "U_CX482_CX483_MY20_Gas_Rx" SG_ 531 CmbbDeny_B_ActlBrk 1;
BA_ "U_CX482_CX483_MY20_Diesel_Rx" SG_ 531 CmbbDeny_B_ActlBrk 1;
BA_ "U_U611_U625_MY20_Hev_Rx" SG_ 531 CmbbDeny_B_ActlBrk 1;
BA_ "U_U611_U625_MY20_Gas_Rx" SG_ 531 CmbbDeny_B_ActlBrk 1;
BA_ "U_U611_U625_MY20_Diesel_Rx" SG_ 531 CmbbDeny_B_ActlBrk 1;
BA_ "U_C519_MY18_5_Gas_Rx" SG_ 531 CmbbDeny_B_ActlBrk 1;
BA_ "U_C519_MY18_5_Diesel_Rx" SG_ 531 CmbbDeny_B_ActlBrk 1;
BA_ "U_B479_MY17_Diesel_Rx" SG_ 531 CmbbDeny_B_ActlBrk 1;
BA_ "U_B479_MY17_Gas_Rx" SG_ 531 CmbbDeny_B_ActlBrk 1;
BA_ "CrossOver_InfoCAN" SG_ 531 CmbbDeny_B_ActlBrk 1;
BA_ "GenSigTimeoutTime_GWM" SG_ 531 CcDis_B_Cmd 60;
BA_ "U_CX482_CX483_MY20_Hev_Tx" SG_ 531 CcDis_B_Cmd 1;
BA_ "U_CX482_CX483_MY20_Gas_Tx" SG_ 531 CcDis_B_Cmd 1;
BA_ "U_CX482_CX483_MY20_Diesel_Tx" SG_ 531 CcDis_B_Cmd 1;
BA_ "U_U611_U625_MY20_Hev_Tx" SG_ 531 CcDis_B_Cmd 1;
BA_ "U_U611_U625_MY20_Gas_Tx" SG_ 531 CcDis_B_Cmd 1;
BA_ "U_U611_U625_MY20_Diesel_Tx" SG_ 531 CcDis_B_Cmd 1;
BA_ "U_C519_MY18_5_Gas_Tx" SG_ 531 CcDis_B_Cmd 1;
BA_ "U_C519_MY18_5_Diesel_Tx" SG_ 531 CcDis_B_Cmd 1;
BA_ "U_B515_MCA_MY17_Gas_Tx" SG_ 531 CcDis_B_Cmd 1;
BA_ "U_B515_MCA_MY17_Diesel_Tx" SG_ 531 CcDis_B_Cmd 1;
BA_ "U_B479_MY17_Diesel_Tx" SG_ 531 CcDis_B_Cmd 1;
BA_ "U_B479_MY17_Gas_Tx" SG_ 531 CcDis_B_Cmd 1;
BA_ "U_B562LC_MY15_Gas_Tx" SG_ 531 CcDis_B_Cmd 1;
BA_ "U_B562LC_MY15_Diesel_Tx" SG_ 531 CcDis_B_Cmd 1;
BA_ "CrossOver_InfoCAN" SG_ 531 CcDis_B_Cmd 1;
BA_ "GenSigTimeoutTime_GWM" SG_ 531 VehLongOvrGnd_A_Est 60;
BA_ "U_CX482_CX483_MY20_Hev_Tx" SG_ 531 VehLongOvrGnd_A_Est 1;
BA_ "U_CX482_CX483_MY20_Gas_Tx" SG_ 531 VehLongOvrGnd_A_Est 1;
BA_ "U_CX482_CX483_MY20_Diesel_Tx" SG_ 531 VehLongOvrGnd_A_Est 1;
BA_ "U_U611_U625_MY20_Hev_Tx" SG_ 531 VehLongOvrGnd_A_Est 1;
BA_ "U_U611_U625_MY20_Gas_Tx" SG_ 531 VehLongOvrGnd_A_Est 1;
BA_ "U_U611_U625_MY20_Diesel_Tx" SG_ 531 VehLongOvrGnd_A_Est 1;
BA_ "U_B500_MY18_Diesel_Tx" SG_ 531 VehLongOvrGnd_A_Est 1;
BA_ "U_B500_MY18_Gas_Tx" SG_ 531 VehLongOvrGnd_A_Est 1;
BA_ "U_C490_MY18_Tx" SG_ 531 VehLongOvrGnd_A_Est 1;
BA_ "U_B562_MY18_Gas_Tx" SG_ 531 VehLongOvrGnd_A_Est 1;
BA_ "U_C519_MY18_5_Gas_Tx" SG_ 531 VehLongOvrGnd_A_Est 1;
BA_ "U_C519_MY18_5_Diesel_Tx" SG_ 531 VehLongOvrGnd_A_Est 1;
BA_ "U_B515_MCA_MY17_Gas_Tx" SG_ 531 VehLongOvrGnd_A_Est 1;
BA_ "U_B515_MCA_MY17_Diesel_Tx" SG_ 531 VehLongOvrGnd_A_Est 1;
BA_ "U_B479_MY17_Diesel_Tx" SG_ 531 VehLongOvrGnd_A_Est 1;
BA_ "U_B479_MY17_Gas_Tx" SG_ 531 VehLongOvrGnd_A_Est 1;
BA_ "U_B562LC_MY15_Gas_Tx" SG_ 531 VehLongOvrGnd_A_Est 1;
BA_ "U_B562LC_MY15_Diesel_Tx" SG_ 531 VehLongOvrGnd_A_Est 1;
BA_ "U_CX482_CX483_MY20_Hev_Rx" SG_ 531 VehLongOvrGnd_A_Est 1;
BA_ "U_CX482_CX483_MY20_Gas_Rx" SG_ 531 VehLongOvrGnd_A_Est 1;
BA_ "U_CX482_CX483_MY20_Diesel_Rx" SG_ 531 VehLongOvrGnd_A_Est 1;
BA_ "U_U611_U625_MY20_Phev_Rx" SG_ 531 VehLongOvrGnd_A_Est 1;
BA_ "U_U611_U625_MY20_Hev_Rx" SG_ 531 VehLongOvrGnd_A_Est 1;
BA_ "U_U611_U625_MY20_Gas_Rx" SG_ 531 VehLongOvrGnd_A_Est 1;
BA_ "U_U611_U625_MY20_Diesel_Rx" SG_ 531 VehLongOvrGnd_A_Est 1;
BA_ "U_C519_MY18_5_Gas_Rx" SG_ 531 VehLongOvrGnd_A_Est 1;
BA_ "U_C519_MY18_5_Diesel_Rx" SG_ 531 VehLongOvrGnd_A_Est 1;
BA_ "U_B479_MY17_Diesel_Rx" SG_ 531 VehLongOvrGnd_A_Est 1;
BA_ "U_B479_MY17_Gas_Rx" SG_ 531 VehLongOvrGnd_A_Est 1;
BA_ "GenSigStartValue" SG_ 531 VehLongOvrGnd_A_Est 511;
BA_ "CrossOver_InfoCAN" SG_ 531 VehLongOvrGnd_A_Est 1;
BA_ "GenSigTimeoutTime_GWM" SG_ 531 LscmbBrkPrchg_B_Actl 60;
BA_ "U_U611_U625_MY20_Hev_Tx" SG_ 531 LscmbBrkPrchg_B_Actl 1;
BA_ "U_U611_U625_MY20_Gas_Tx" SG_ 531 LscmbBrkPrchg_B_Actl 1;
BA_ "U_U611_U625_MY20_Diesel_Tx" SG_ 531 LscmbBrkPrchg_B_Actl 1;
BA_ "U_B515_MCA_MY17_Gas_Tx" SG_ 531 LscmbBrkPrchg_B_Actl 1;
BA_ "U_B515_MCA_MY17_Diesel_Tx" SG_ 531 LscmbBrkPrchg_B_Actl 1;
BA_ "U_B562LC_MY15_Gas_Tx" SG_ 531 LscmbBrkPrchg_B_Actl 1;
BA_ "U_B562LC_MY15_Diesel_Tx" SG_ 531 LscmbBrkPrchg_B_Actl 1;
BA_ "CrossOver_InfoCAN" SG_ 531 LscmbBrkPrchg_B_Actl 1;
BA_ "GenSigTimeoutTime_GWM" SG_ 531 AccStopActv_B_ActlBrk 60;
BA_ "U_CX482_CX483_MY20_Hev_Tx" SG_ 531 AccStopActv_B_ActlBrk 1;
BA_ "U_CX482_CX483_MY20_Gas_Tx" SG_ 531 AccStopActv_B_ActlBrk 1;
BA_ "U_CX482_CX483_MY20_Diesel_Tx" SG_ 531 AccStopActv_B_ActlBrk 1;
BA_ "U_U611_U625_MY20_Hev_Tx" SG_ 531 AccStopActv_B_ActlBrk 1;
BA_ "U_U611_U625_MY20_Gas_Tx" SG_ 531 AccStopActv_B_ActlBrk 1;
BA_ "U_U611_U625_MY20_Diesel_Tx" SG_ 531 AccStopActv_B_ActlBrk 1;
BA_ "U_C519_MY18_5_Gas_Tx" SG_ 531 AccStopActv_B_ActlBrk 1;
BA_ "U_C519_MY18_5_Diesel_Tx" SG_ 531 AccStopActv_B_ActlBrk 1;
BA_ "U_B515_MCA_MY17_Gas_Tx" SG_ 531 AccStopActv_B_ActlBrk 1;
BA_ "U_B515_MCA_MY17_Diesel_Tx" SG_ 531 AccStopActv_B_ActlBrk 1;
BA_ "U_B479_MY17_Diesel_Tx" SG_ 531 AccStopActv_B_ActlBrk 1;
BA_ "U_B479_MY17_Gas_Tx" SG_ 531 AccStopActv_B_ActlBrk 1;
BA_ "U_B562LC_MY15_Gas_Tx" SG_ 531 AccStopActv_B_ActlBrk 1;
BA_ "U_B562LC_MY15_Diesel_Tx" SG_ 531 AccStopActv_B_ActlBrk 1;
BA_ "U_CX482_CX483_MY20_Hev_Rx" SG_ 531 AccStopActv_B_ActlBrk 1;
BA_ "U_CX482_CX483_MY20_Gas_Rx" SG_ 531 AccStopActv_B_ActlBrk 1;
BA_ "U_CX482_CX483_MY20_Diesel_Rx" SG_ 531 AccStopActv_B_ActlBrk 1;
BA_ "U_U611_U625_MY20_Hev_Rx" SG_ 531 AccStopActv_B_ActlBrk 1;
BA_ "U_U611_U625_MY20_Gas_Rx" SG_ 531 AccStopActv_B_ActlBrk 1;
BA_ "U_U611_U625_MY20_Diesel_Rx" SG_ 531 AccStopActv_B_ActlBrk 1;
BA_ "U_C519_MY18_5_Gas_Rx" SG_ 531 AccStopActv_B_ActlBrk 1;
BA_ "U_C519_MY18_5_Diesel_Rx" SG_ 531 AccStopActv_B_ActlBrk 1;
BA_ "U_B479_MY17_Diesel_Rx" SG_ 531 AccStopActv_B_ActlBrk 1;
BA_ "U_B479_MY17_Gas_Rx" SG_ 531 AccStopActv_B_ActlBrk 1;
BA_ "CrossOver_InfoCAN" SG_ 531 AccStopActv_B_ActlBrk 1;
BA_ "GenSigTimeoutTime_GWM" SG_ 531 AccDis_B_ActlEpb 60;
BA_ "U_CX482_CX483_MY20_Hev_Tx" SG_ 531 AccDis_B_ActlEpb 1;
BA_ "U_CX482_CX483_MY20_Gas_Tx" SG_ 531 AccDis_B_ActlEpb 1;
BA_ "U_CX482_CX483_MY20_Diesel_Tx" SG_ 531 AccDis_B_ActlEpb 1;
BA_ "U_U611_U625_MY20_Hev_Tx" SG_ 531 AccDis_B_ActlEpb 1;
BA_ "U_U611_U625_MY20_Gas_Tx" SG_ 531 AccDis_B_ActlEpb 1;
BA_ "U_U611_U625_MY20_Diesel_Tx" SG_ 531 AccDis_B_ActlEpb 1;
BA_ "U_C519_MY18_5_Gas_Tx" SG_ 531 AccDis_B_ActlEpb 1;
BA_ "U_C519_MY18_5_Diesel_Tx" SG_ 531 AccDis_B_ActlEpb 1;
BA_ "U_B515_MCA_MY17_Gas_Tx" SG_ 531 AccDis_B_ActlEpb 1;
BA_ "U_B515_MCA_MY17_Diesel_Tx" SG_ 531 AccDis_B_ActlEpb 1;
BA_ "U_B479_MY17_Diesel_Tx" SG_ 531 AccDis_B_ActlEpb 1;
BA_ "U_B479_MY17_Gas_Tx" SG_ 531 AccDis_B_ActlEpb 1;
BA_ "U_B562LC_MY15_Gas_Tx" SG_ 531 AccDis_B_ActlEpb 1;
BA_ "U_B562LC_MY15_Diesel_Tx" SG_ 531 AccDis_B_ActlEpb 1;
BA_ "U_CX482_CX483_MY20_Hev_Rx" SG_ 531 AccDis_B_ActlEpb 1;
BA_ "U_CX482_CX483_MY20_Gas_Rx" SG_ 531 AccDis_B_ActlEpb 1;
BA_ "U_CX482_CX483_MY20_Diesel_Rx" SG_ 531 AccDis_B_ActlEpb 1;
BA_ "U_U611_U625_MY20_Hev_Rx" SG_ 531 AccDis_B_ActlEpb 1;
BA_ "U_U611_U625_MY20_Gas_Rx" SG_ 531 AccDis_B_ActlEpb 1;
BA_ "U_U611_U625_MY20_Diesel_Rx" SG_ 531 AccDis_B_ActlEpb 1;
BA_ "U_C519_MY18_5_Gas_Rx" SG_ 531 AccDis_B_ActlEpb 1;
BA_ "U_C519_MY18_5_Diesel_Rx" SG_ 531 AccDis_B_ActlEpb 1;
BA_ "U_B479_MY17_Diesel_Rx" SG_ 531 AccDis_B_ActlEpb 1;
BA_ "U_B479_MY17_Gas_Rx" SG_ 531 AccDis_B_ActlEpb 1;
BA_ "CrossOver_InfoCAN" SG_ 531 AccDis_B_ActlEpb 1;
BA_ "GenSigTimeoutTime_GWM" SG_ 531 PrkBrkMsgTxt_D_Rq 60;
BA_ "U_CX482_CX483_MY20_Hev_Tx" SG_ 531 PrkBrkMsgTxt_D_Rq 1;
BA_ "U_CX482_CX483_MY20_Gas_Tx" SG_ 531 PrkBrkMsgTxt_D_Rq 1;
BA_ "U_CX482_CX483_MY20_Diesel_Tx" SG_ 531 PrkBrkMsgTxt_D_Rq 1;
BA_ "U_U611_U625_MY20_Hev_Tx" SG_ 531 PrkBrkMsgTxt_D_Rq 1;
BA_ "U_U611_U625_MY20_Gas_Tx" SG_ 531 PrkBrkMsgTxt_D_Rq 1;
BA_ "U_U611_U625_MY20_Diesel_Tx" SG_ 531 PrkBrkMsgTxt_D_Rq 1;
BA_ "U_C519_MY18_5_Gas_Tx" SG_ 531 PrkBrkMsgTxt_D_Rq 1;
BA_ "U_C519_MY18_5_Diesel_Tx" SG_ 531 PrkBrkMsgTxt_D_Rq 1;
BA_ "U_B562LC_MY15_Gas_Tx" SG_ 531 PrkBrkMsgTxt_D_Rq 1;
BA_ "U_B562LC_MY15_Diesel_Tx" SG_ 531 PrkBrkMsgTxt_D_Rq 1;
BA_ "U_B479_MY17_Gas_Rx" SG_ 531 PrkBrkMsgTxt_D_Rq 1;
BA_ "CrossOver_InfoCAN" SG_ 531 PrkBrkMsgTxt_D_Rq 1;
BA_ "WakeupSignal" SG_ 531 PrkBrkMsgTxt_D_Rq 1;
BA_ "GenSigTimeoutTime_GWM" SG_ 531 PrkBrkStatus 60;
BA_ "U_CX482_CX483_MY20_Hev_Tx" SG_ 531 PrkBrkStatus 1;
BA_ "U_CX482_CX483_MY20_Gas_Tx" SG_ 531 PrkBrkStatus 1;
BA_ "U_CX482_CX483_MY20_Diesel_Tx" SG_ 531 PrkBrkStatus 1;
BA_ "U_U611_U625_MY20_Hev_Tx" SG_ 531 PrkBrkStatus 1;
BA_ "U_U611_U625_MY20_Gas_Tx" SG_ 531 PrkBrkStatus 1;
BA_ "U_U611_U625_MY20_Diesel_Tx" SG_ 531 PrkBrkStatus 1;
BA_ "U_C519_MY18_5_Gas_Tx" SG_ 531 PrkBrkStatus 1;
BA_ "U_C519_MY18_5_Diesel_Tx" SG_ 531 PrkBrkStatus 1;
BA_ "U_B562LC_MY15_Gas_Tx" SG_ 531 PrkBrkStatus 1;
BA_ "U_B562LC_MY15_Diesel_Tx" SG_ 531 PrkBrkStatus 1;
BA_ "U_U611_U625_MY20_Phev_Rx" SG_ 531 PrkBrkStatus 1;
BA_ "U_CX482_CX483_MY20_Hev_Rx" SG_ 531 PrkBrkStatus 1;
BA_ "U_CX482_CX483_MY20_Gas_Rx" SG_ 531 PrkBrkStatus 1;
BA_ "U_CX482_CX483_MY20_Diesel_Rx" SG_ 531 PrkBrkStatus 1;
BA_ "U_U611_U625_MY20_Hev_Rx" SG_ 531 PrkBrkStatus 1;
BA_ "U_U611_U625_MY20_Gas_Rx" SG_ 531 PrkBrkStatus 1;
BA_ "U_U611_U625_MY20_Diesel_Rx" SG_ 531 PrkBrkStatus 1;
BA_ "U_C519_MY18_5_Gas_Rx" SG_ 531 PrkBrkStatus 1;
BA_ "U_C519_MY18_5_Diesel_Rx" SG_ 531 PrkBrkStatus 1;
BA_ "GenSigStartValue" SG_ 531 PrkBrkStatus 7;
BA_ "CrossOver_InfoCAN" SG_ 531 PrkBrkStatus 1;
BA_ "U_U611_U625_MY20_Hev_Tx" SG_ 137 SteWhlOffstRq_D_Stat 1;
BA_ "U_U611_U625_MY20_Gas_Tx" SG_ 137 SteWhlOffstRq_D_Stat 1;
BA_ "U_U611_U625_MY20_Diesel_Tx" SG_ 137 SteWhlOffstRq_D_Stat 1;
BA_ "U_U611_U625_MY20_Hev_Rx" SG_ 137 SteWhlOffstRq_D_Stat 1;
BA_ "U_U611_U625_MY20_Gas_Rx" SG_ 137 SteWhlOffstRq_D_Stat 1;
BA_ "U_U611_U625_MY20_Diesel_Rx" SG_ 137 SteWhlOffstRq_D_Stat 1;
BA_ "GenSigStartValue" SG_ 137 SteWhlOffstRq_D_Stat 2;
BA_ "U_U611_U625_MY20_Hev_Tx" SG_ 137 SteWhlOffst_An_TotActl 1;
BA_ "U_U611_U625_MY20_Gas_Tx" SG_ 137 SteWhlOffst_An_TotActl 1;
BA_ "U_U611_U625_MY20_Diesel_Tx" SG_ 137 SteWhlOffst_An_TotActl 1;
BA_ "U_U611_U625_MY20_Hev_Rx" SG_ 137 SteWhlOffst_An_TotActl 1;
BA_ "U_U611_U625_MY20_Gas_Rx" SG_ 137 SteWhlOffst_An_TotActl 1;
BA_ "U_U611_U625_MY20_Diesel_Rx" SG_ 137 SteWhlOffst_An_TotActl 1;
BA_ "GenSigStartValue" SG_ 137 SteWhlOffst_An_TotActl 32766;
BA_ "U_U611_U625_MY20_Hev_Tx" SG_ 137 SteWhlBrkOffst_An_Actl 1;
BA_ "U_U611_U625_MY20_Gas_Tx" SG_ 137 SteWhlBrkOffst_An_Actl 1;
BA_ "U_U611_U625_MY20_Diesel_Tx" SG_ 137 SteWhlBrkOffst_An_Actl 1;
BA_ "U_U611_U625_MY20_Hev_Rx" SG_ 137 SteWhlBrkOffst_An_Actl 1;
BA_ "U_U611_U625_MY20_Gas_Rx" SG_ 137 SteWhlBrkOffst_An_Actl 1;
BA_ "U_U611_U625_MY20_Diesel_Rx" SG_ 137 SteWhlBrkOffst_An_Actl 1;
BA_ "GenSigStartValue" SG_ 137 SteWhlBrkOffst_An_Actl 32766;
BA_ "U_U611_U625_MY20_Hev_Tx" SG_ 137 SteWhlBrkAnActl_No_Cs 1;
BA_ "U_U611_U625_MY20_Gas_Tx" SG_ 137 SteWhlBrkAnActl_No_Cs 1;
BA_ "U_U611_U625_MY20_Diesel_Tx" SG_ 137 SteWhlBrkAnActl_No_Cs 1;
BA_ "U_U611_U625_MY20_Hev_Rx" SG_ 137 SteWhlBrkAnActl_No_Cs 1;
BA_ "U_U611_U625_MY20_Gas_Rx" SG_ 137 SteWhlBrkAnActl_No_Cs 1;
BA_ "U_U611_U625_MY20_Diesel_Rx" SG_ 137 SteWhlBrkAnActl_No_Cs 1;
BA_ "CrossOver_InfoCAN" SG_ 137 SteWhlBrkAnActl_No_Cs 1;
BA_ "U_U611_U625_MY20_Hev_Tx" SG_ 137 SteWhlBrkAnActl_No_Cnt 1;
BA_ "U_U611_U625_MY20_Gas_Tx" SG_ 137 SteWhlBrkAnActl_No_Cnt 1;
BA_ "U_U611_U625_MY20_Diesel_Tx" SG_ 137 SteWhlBrkAnActl_No_Cnt 1;
BA_ "U_U611_U625_MY20_Hev_Rx" SG_ 137 SteWhlBrkAnActl_No_Cnt 1;
BA_ "U_U611_U625_MY20_Gas_Rx" SG_ 137 SteWhlBrkAnActl_No_Cnt 1;
BA_ "U_U611_U625_MY20_Diesel_Rx" SG_ 137 SteWhlBrkAnActl_No_Cnt 1;
BA_ "CrossOver_InfoCAN" SG_ 137 SteWhlBrkAnActl_No_Cnt 1;
BA_ "U_U611_U625_MY20_Hev_Tx" SG_ 136 SteWhlBrkOffst_An_Rq 1;
BA_ "U_U611_U625_MY20_Gas_Tx" SG_ 136 SteWhlBrkOffst_An_Rq 1;
BA_ "U_U611_U625_MY20_Diesel_Tx" SG_ 136 SteWhlBrkOffst_An_Rq 1;
BA_ "U_U611_U625_MY20_Hev_Rx" SG_ 136 SteWhlBrkOffst_An_Rq 1;
BA_ "U_U611_U625_MY20_Gas_Rx" SG_ 136 SteWhlBrkOffst_An_Rq 1;
BA_ "U_U611_U625_MY20_Diesel_Rx" SG_ 136 SteWhlBrkOffst_An_Rq 1;
BA_ "GenSigStartValue" SG_ 136 SteWhlBrkOffst_An_Rq 32766;
BA_ "U_U611_U625_MY20_Hev_Tx" SG_ 136 SteWhlBrkAnRq_No_Cs 1;
BA_ "U_U611_U625_MY20_Gas_Tx" SG_ 136 SteWhlBrkAnRq_No_Cs 1;
BA_ "U_U611_U625_MY20_Diesel_Tx" SG_ 136 SteWhlBrkAnRq_No_Cs 1;
BA_ "U_U611_U625_MY20_Hev_Rx" SG_ 136 SteWhlBrkAnRq_No_Cs 1;
BA_ "U_U611_U625_MY20_Gas_Rx" SG_ 136 SteWhlBrkAnRq_No_Cs 1;
BA_ "U_U611_U625_MY20_Diesel_Rx" SG_ 136 SteWhlBrkAnRq_No_Cs 1;
BA_ "CrossOver_InfoCAN" SG_ 136 SteWhlBrkAnRq_No_Cs 1;
BA_ "U_U611_U625_MY20_Hev_Tx" SG_ 136 SteWhlBrkAnRq_No_Cnt 1;
BA_ "U_U611_U625_MY20_Gas_Tx" SG_ 136 SteWhlBrkAnRq_No_Cnt 1;
BA_ "U_U611_U625_MY20_Diesel_Tx" SG_ 136 SteWhlBrkAnRq_No_Cnt 1;
BA_ "U_U611_U625_MY20_Hev_Rx" SG_ 136 SteWhlBrkAnRq_No_Cnt 1;
BA_ "U_U611_U625_MY20_Gas_Rx" SG_ 136 SteWhlBrkAnRq_No_Cnt 1;
BA_ "U_U611_U625_MY20_Diesel_Rx" SG_ 136 SteWhlBrkAnRq_No_Cnt 1;
BA_ "CrossOver_InfoCAN" SG_ 136 SteWhlBrkAnRq_No_Cnt 1;
BA_ "U_U611_U625_MY20_Hev_Rx" SG_ 604 WhlDirAvgDrv_D_Actl 1;
BA_ "U_U611_U625_MY20_Gas_Rx" SG_ 604 WhlDirAvgDrv_D_Actl 1;
BA_ "U_U611_U625_MY20_Diesel_Rx" SG_ 604 WhlDirAvgDrv_D_Actl 1;
BA_ "U_B515_MCA_MY17_Gas_Rx" SG_ 604 WhlDirAvgDrv_D_Actl 1;
BA_ "U_B515_MCA_MY17_Diesel_Rx" SG_ 604 WhlDirAvgDrv_D_Actl 1;
BA_ "U_B479_MY17_Diesel_Rx" SG_ 604 WhlDirAvgDrv_D_Actl 1;
BA_ "U_B479_MY17_Gas_Rx" SG_ 604 WhlDirAvgDrv_D_Actl 1;
BA_ "U_U611_U625_MY20_Hev_Rx" SG_ 604 PrplTqMnRgen_B_Actl 1;
BA_ "U_U611_U625_MY20_Gas_Rx" SG_ 604 PrplTqMnRgen_B_Actl 1;
BA_ "U_U611_U625_MY20_Diesel_Rx" SG_ 604 PrplTqMnRgen_B_Actl 1;
BA_ "U_U611_U625_MY20_Hev_Rx" SG_ 604 WhlDirAvgDrv_D_Actl_UB 1;
BA_ "U_U611_U625_MY20_Gas_Rx" SG_ 604 WhlDirAvgDrv_D_Actl_UB 1;
BA_ "U_U611_U625_MY20_Diesel_Rx" SG_ 604 WhlDirAvgDrv_D_Actl_UB 1;
BA_ "U_U611_U625_MY20_Hev_Rx" SG_ 604 PrplTqMnRgen_B_Actl_UB 1;
BA_ "U_U611_U625_MY20_Gas_Rx" SG_ 604 PrplTqMnRgen_B_Actl_UB 1;
BA_ "U_U611_U625_MY20_Diesel_Rx" SG_ 604 PrplTqMnRgen_B_Actl_UB 1;
BA_ "U_C490_MY18_Rx" SG_ 2015 TesterFunctionalReq 1;
BA_ "U_B562_MY18_Gas_Rx" SG_ 2015 TesterFunctionalReq 1;
BA_ "U_CX482_CX483_MY20_Hev_Rx" SG_ 2015 TesterFunctionalReq 1;
BA_ "U_CX482_CX483_MY20_Gas_Rx" SG_ 2015 TesterFunctionalReq 1;
BA_ "U_CX482_CX483_MY20_Diesel_Rx" SG_ 2015 TesterFunctionalReq 1;
BA_ "U_B500_MY18_Diesel_Rx" SG_ 2015 TesterFunctionalReq 1;
BA_ "U_B500_MY18_Gas_Rx" SG_ 2015 TesterFunctionalReq 1;
BA_ "U_B515_MCA_MY17_Gas_Rx" SG_ 2015 TesterFunctionalReq 1;
BA_ "U_B515_MCA_MY17_Diesel_Rx" SG_ 2015 TesterFunctionalReq 1;
BA_ "U_B479_MY17_Diesel_Rx" SG_ 2015 TesterFunctionalReq 1;
BA_ "U_B479_MY17_Gas_Rx" SG_ 2015 TesterFunctionalReq 1;
BA_ "U_U611_U625_MY20_Phev_Rx" SG_ 2015 TesterFunctionalReq 1;
BA_ "U_U611_U625_MY20_Hev_Rx" SG_ 2015 TesterFunctionalReq 1;
BA_ "U_U611_U625_MY20_Gas_Rx" SG_ 2015 TesterFunctionalReq 1;
BA_ "U_U611_U625_MY20_Diesel_Rx" SG_ 2015 TesterFunctionalReq 1;
BA_ "U_C519_MY18_5_Gas_Rx" SG_ 2015 TesterFunctionalReq 1;
BA_ "U_C519_MY18_5_Diesel_Rx" SG_ 2015 TesterFunctionalReq 1;
BA_ "GenSigSendType" SG_ 2015 TesterFunctionalReq 3;
BA_ "CrossOver_InfoCAN" SG_ 2015 TesterFunctionalReq 1;
BA_ "U_CX482_CX483_MY20_Hev_Tx" SG_ 125 VehRolComp_W_Actl 1;
BA_ "U_CX482_CX483_MY20_Gas_Tx" SG_ 125 VehRolComp_W_Actl 1;
BA_ "U_CX482_CX483_MY20_Diesel_Tx" SG_ 125 VehRolComp_W_Actl 1;
BA_ "U_U611_U625_MY20_Hev_Tx" SG_ 125 VehRolComp_W_Actl 1;
BA_ "U_U611_U625_MY20_Gas_Tx" SG_ 125 VehRolComp_W_Actl 1;
BA_ "U_U611_U625_MY20_Diesel_Tx" SG_ 125 VehRolComp_W_Actl 1;
BA_ "U_B500_MY18_Diesel_Tx" SG_ 125 VehRolComp_W_Actl 1;
BA_ "U_B500_MY18_Gas_Tx" SG_ 125 VehRolComp_W_Actl 1;
BA_ "U_C490_MY18_Tx" SG_ 125 VehRolComp_W_Actl 1;
BA_ "U_B562_MY18_Gas_Tx" SG_ 125 VehRolComp_W_Actl 1;
BA_ "U_C519_MY18_5_Gas_Tx" SG_ 125 VehRolComp_W_Actl 1;
BA_ "U_C519_MY18_5_Diesel_Tx" SG_ 125 VehRolComp_W_Actl 1;
BA_ "U_B515_MCA_MY17_Gas_Tx" SG_ 125 VehRolComp_W_Actl 1;
BA_ "U_B515_MCA_MY17_Diesel_Tx" SG_ 125 VehRolComp_W_Actl 1;
BA_ "U_B479_MY17_Diesel_Tx" SG_ 125 VehRolComp_W_Actl 1;
BA_ "U_B479_MY17_Gas_Tx" SG_ 125 VehRolComp_W_Actl 1;
BA_ "U_B562LC_MY15_Gas_Tx" SG_ 125 VehRolComp_W_Actl 1;
BA_ "U_B562LC_MY15_Diesel_Tx" SG_ 125 VehRolComp_W_Actl 1;
BA_ "U_U611_U625_MY20_Phev_Rx" SG_ 125 VehRolComp_W_Actl 1;
BA_ "U_U611_U625_MY20_Hev_Rx" SG_ 125 VehRolComp_W_Actl 1;
BA_ "U_U611_U625_MY20_Gas_Rx" SG_ 125 VehRolComp_W_Actl 1;
BA_ "U_U611_U625_MY20_Diesel_Rx" SG_ 125 VehRolComp_W_Actl 1;
BA_ "U_C519_MY18_5_Gas_Rx" SG_ 125 VehRolComp_W_Actl 1;
BA_ "U_C519_MY18_5_Diesel_Rx" SG_ 125 VehRolComp_W_Actl 1;
BA_ "GenSigStartValue" SG_ 125 VehRolComp_W_Actl 4094;
BA_ "U_CX482_CX483_MY20_Hev_Tx" SG_ 125 VehVertComp_A_Actl 1;
BA_ "U_CX482_CX483_MY20_Gas_Tx" SG_ 125 VehVertComp_A_Actl 1;
BA_ "U_CX482_CX483_MY20_Diesel_Tx" SG_ 125 VehVertComp_A_Actl 1;
BA_ "U_U611_U625_MY20_Hev_Tx" SG_ 125 VehVertComp_A_Actl 1;
BA_ "U_U611_U625_MY20_Gas_Tx" SG_ 125 VehVertComp_A_Actl 1;
BA_ "U_U611_U625_MY20_Diesel_Tx" SG_ 125 VehVertComp_A_Actl 1;
BA_ "U_B500_MY18_Diesel_Tx" SG_ 125 VehVertComp_A_Actl 1;
BA_ "U_B500_MY18_Gas_Tx" SG_ 125 VehVertComp_A_Actl 1;
BA_ "U_C490_MY18_Tx" SG_ 125 VehVertComp_A_Actl 1;
BA_ "U_B562_MY18_Gas_Tx" SG_ 125 VehVertComp_A_Actl 1;
BA_ "U_C519_MY18_5_Gas_Tx" SG_ 125 VehVertComp_A_Actl 1;
BA_ "U_C519_MY18_5_Diesel_Tx" SG_ 125 VehVertComp_A_Actl 1;
BA_ "U_B515_MCA_MY17_Gas_Tx" SG_ 125 VehVertComp_A_Actl 1;
BA_ "U_B515_MCA_MY17_Diesel_Tx" SG_ 125 VehVertComp_A_Actl 1;
BA_ "U_B479_MY17_Diesel_Tx" SG_ 125 VehVertComp_A_Actl 1;
BA_ "U_B479_MY17_Gas_Tx" SG_ 125 VehVertComp_A_Actl 1;
BA_ "U_B562LC_MY15_Gas_Tx" SG_ 125 VehVertComp_A_Actl 1;
BA_ "U_B562LC_MY15_Diesel_Tx" SG_ 125 VehVertComp_A_Actl 1;
BA_ "U_U611_U625_MY20_Phev_Rx" SG_ 125 VehVertComp_A_Actl 1;
BA_ "U_U611_U625_MY20_Hev_Rx" SG_ 125 VehVertComp_A_Actl 1;
BA_ "U_U611_U625_MY20_Gas_Rx" SG_ 125 VehVertComp_A_Actl 1;
BA_ "U_U611_U625_MY20_Diesel_Rx" SG_ 125 VehVertComp_A_Actl 1;
BA_ "U_C519_MY18_5_Gas_Rx" SG_ 125 VehVertComp_A_Actl 1;
BA_ "U_C519_MY18_5_Diesel_Rx" SG_ 125 VehVertComp_A_Actl 1;
BA_ "GenSigStartValue" SG_ 125 VehVertComp_A_Actl 1022;
BA_ "U_CX482_CX483_MY20_Hev_Tx" SG_ 125 BrkTotTqRqArb_No_Cs 1;
BA_ "U_CX482_CX483_MY20_Gas_Tx" SG_ 125 BrkTotTqRqArb_No_Cs 1;
BA_ "U_CX482_CX483_MY20_Diesel_Tx" SG_ 125 BrkTotTqRqArb_No_Cs 1;
BA_ "U_U611_U625_MY20_Hev_Tx" SG_ 125 BrkTotTqRqArb_No_Cs 1;
BA_ "U_U611_U625_MY20_Gas_Tx" SG_ 125 BrkTotTqRqArb_No_Cs 1;
BA_ "U_U611_U625_MY20_Diesel_Tx" SG_ 125 BrkTotTqRqArb_No_Cs 1;
BA_ "U_B500_MY18_Diesel_Tx" SG_ 125 BrkTotTqRqArb_No_Cs 1;
BA_ "U_B500_MY18_Gas_Tx" SG_ 125 BrkTotTqRqArb_No_Cs 1;
BA_ "U_C490_MY18_Tx" SG_ 125 BrkTotTqRqArb_No_Cs 1;
BA_ "U_B562_MY18_Gas_Tx" SG_ 125 BrkTotTqRqArb_No_Cs 1;
BA_ "U_C519_MY18_5_Gas_Tx" SG_ 125 BrkTotTqRqArb_No_Cs 1;
BA_ "U_C519_MY18_5_Diesel_Tx" SG_ 125 BrkTotTqRqArb_No_Cs 1;
BA_ "U_B515_MCA_MY17_Gas_Tx" SG_ 125 BrkTotTqRqArb_No_Cs 1;
BA_ "U_B515_MCA_MY17_Diesel_Tx" SG_ 125 BrkTotTqRqArb_No_Cs 1;
BA_ "U_B479_MY17_Diesel_Tx" SG_ 125 BrkTotTqRqArb_No_Cs 1;
BA_ "U_B479_MY17_Gas_Tx" SG_ 125 BrkTotTqRqArb_No_Cs 1;
BA_ "U_B562LC_MY15_Gas_Tx" SG_ 125 BrkTotTqRqArb_No_Cs 1;
BA_ "U_B562LC_MY15_Diesel_Tx" SG_ 125 BrkTotTqRqArb_No_Cs 1;
BA_ "U_CX482_CX483_MY20_Hev_Tx" SG_ 125 BrkTotTqRqArb_No_Cnt 1;
BA_ "U_CX482_CX483_MY20_Gas_Tx" SG_ 125 BrkTotTqRqArb_No_Cnt 1;
BA_ "U_CX482_CX483_MY20_Diesel_Tx" SG_ 125 BrkTotTqRqArb_No_Cnt 1;
BA_ "U_U611_U625_MY20_Hev_Tx" SG_ 125 BrkTotTqRqArb_No_Cnt 1;
BA_ "U_U611_U625_MY20_Gas_Tx" SG_ 125 BrkTotTqRqArb_No_Cnt 1;
BA_ "U_U611_U625_MY20_Diesel_Tx" SG_ 125 BrkTotTqRqArb_No_Cnt 1;
BA_ "U_B500_MY18_Diesel_Tx" SG_ 125 BrkTotTqRqArb_No_Cnt 1;
BA_ "U_B500_MY18_Gas_Tx" SG_ 125 BrkTotTqRqArb_No_Cnt 1;
BA_ "U_C490_MY18_Tx" SG_ 125 BrkTotTqRqArb_No_Cnt 1;
BA_ "U_B562_MY18_Gas_Tx" SG_ 125 BrkTotTqRqArb_No_Cnt 1;
BA_ "U_C519_MY18_5_Gas_Tx" SG_ 125 BrkTotTqRqArb_No_Cnt 1;
BA_ "U_C519_MY18_5_Diesel_Tx" SG_ 125 BrkTotTqRqArb_No_Cnt 1;
BA_ "U_B515_MCA_MY17_Gas_Tx" SG_ 125 BrkTotTqRqArb_No_Cnt 1;
BA_ "U_B515_MCA_MY17_Diesel_Tx" SG_ 125 BrkTotTqRqArb_No_Cnt 1;
BA_ "U_B479_MY17_Diesel_Tx" SG_ 125 BrkTotTqRqArb_No_Cnt 1;
BA_ "U_B479_MY17_Gas_Tx" SG_ 125 BrkTotTqRqArb_No_Cnt 1;
BA_ "U_B562LC_MY15_Gas_Tx" SG_ 125 BrkTotTqRqArb_No_Cnt 1;
BA_ "U_B562LC_MY15_Diesel_Tx" SG_ 125 BrkTotTqRqArb_No_Cnt 1;
BA_ "U_CX482_CX483_MY20_Hev_Tx" SG_ 125 BrkTot_Tq_RqArb 1;
BA_ "U_CX482_CX483_MY20_Gas_Tx" SG_ 125 BrkTot_Tq_RqArb 1;
BA_ "U_CX482_CX483_MY20_Diesel_Tx" SG_ 125 BrkTot_Tq_RqArb 1;
BA_ "U_U611_U625_MY20_Hev_Tx" SG_ 125 BrkTot_Tq_RqArb 1;
BA_ "U_U611_U625_MY20_Gas_Tx" SG_ 125 BrkTot_Tq_RqArb 1;
BA_ "U_U611_U625_MY20_Diesel_Tx" SG_ 125 BrkTot_Tq_RqArb 1;
BA_ "U_B500_MY18_Diesel_Tx" SG_ 125 BrkTot_Tq_RqArb 1;
BA_ "U_B500_MY18_Gas_Tx" SG_ 125 BrkTot_Tq_RqArb 1;
BA_ "U_C490_MY18_Tx" SG_ 125 BrkTot_Tq_RqArb 1;
BA_ "U_B562_MY18_Gas_Tx" SG_ 125 BrkTot_Tq_RqArb 1;
BA_ "U_C519_MY18_5_Gas_Tx" SG_ 125 BrkTot_Tq_RqArb 1;
BA_ "U_C519_MY18_5_Diesel_Tx" SG_ 125 BrkTot_Tq_RqArb 1;
BA_ "U_B515_MCA_MY17_Gas_Tx" SG_ 125 BrkTot_Tq_RqArb 1;
BA_ "U_B515_MCA_MY17_Diesel_Tx" SG_ 125 BrkTot_Tq_RqArb 1;
BA_ "U_B479_MY17_Diesel_Tx" SG_ 125 BrkTot_Tq_RqArb 1;
BA_ "U_B479_MY17_Gas_Tx" SG_ 125 BrkTot_Tq_RqArb 1;
BA_ "U_B562LC_MY15_Gas_Tx" SG_ 125 BrkTot_Tq_RqArb 1;
BA_ "U_B562LC_MY15_Diesel_Tx" SG_ 125 BrkTot_Tq_RqArb 1;
BA_ "U_CX482_CX483_MY20_Hev_Rx" SG_ 125 BrkTot_Tq_RqArb 1;
BA_ "U_CX482_CX483_MY20_Gas_Rx" SG_ 125 BrkTot_Tq_RqArb 1;
BA_ "U_CX482_CX483_MY20_Diesel_Rx" SG_ 125 BrkTot_Tq_RqArb 1;
BA_ "U_B479_MY17_Diesel_Rx" SG_ 125 BrkTot_Tq_RqArb 1;
BA_ "U_B479_MY17_Gas_Rx" SG_ 125 BrkTot_Tq_RqArb 1;
BA_ "U_U611_U625_MY20_Phev_Rx" SG_ 125 BrkTot_Tq_RqArb 1;
BA_ "U_U611_U625_MY20_Hev_Rx" SG_ 125 BrkTot_Tq_RqArb 1;
BA_ "U_U611_U625_MY20_Gas_Rx" SG_ 125 BrkTot_Tq_RqArb 1;
BA_ "U_U611_U625_MY20_Diesel_Rx" SG_ 125 BrkTot_Tq_RqArb 1;
BA_ "U_C519_MY18_5_Gas_Rx" SG_ 125 BrkTot_Tq_RqArb 1;
BA_ "U_C519_MY18_5_Diesel_Rx" SG_ 125 BrkTot_Tq_RqArb 1;
BA_ "U_CX482_CX483_MY20_Hev_Tx" SG_ 125 BrkTot_Tq_Actl 1;
BA_ "U_CX482_CX483_MY20_Gas_Tx" SG_ 125 BrkTot_Tq_Actl 1;
BA_ "U_CX482_CX483_MY20_Diesel_Tx" SG_ 125 BrkTot_Tq_Actl 1;
BA_ "U_U611_U625_MY20_Hev_Tx" SG_ 125 BrkTot_Tq_Actl 1;
BA_ "U_U611_U625_MY20_Gas_Tx" SG_ 125 BrkTot_Tq_Actl 1;
BA_ "U_U611_U625_MY20_Diesel_Tx" SG_ 125 BrkTot_Tq_Actl 1;
BA_ "U_B500_MY18_Diesel_Tx" SG_ 125 BrkTot_Tq_Actl 1;
BA_ "U_B500_MY18_Gas_Tx" SG_ 125 BrkTot_Tq_Actl 1;
BA_ "U_C490_MY18_Tx" SG_ 125 BrkTot_Tq_Actl 1;
BA_ "U_B562_MY18_Gas_Tx" SG_ 125 BrkTot_Tq_Actl 1;
BA_ "U_C519_MY18_5_Gas_Tx" SG_ 125 BrkTot_Tq_Actl 1;
BA_ "U_C519_MY18_5_Diesel_Tx" SG_ 125 BrkTot_Tq_Actl 1;
BA_ "U_B515_MCA_MY17_Gas_Tx" SG_ 125 BrkTot_Tq_Actl 1;
BA_ "U_B515_MCA_MY17_Diesel_Tx" SG_ 125 BrkTot_Tq_Actl 1;
BA_ "U_B479_MY17_Diesel_Tx" SG_ 125 BrkTot_Tq_Actl 1;
BA_ "U_B479_MY17_Gas_Tx" SG_ 125 BrkTot_Tq_Actl 1;
BA_ "U_B562LC_MY15_Gas_Tx" SG_ 125 BrkTot_Tq_Actl 1;
BA_ "U_B562LC_MY15_Diesel_Tx" SG_ 125 BrkTot_Tq_Actl 1;
BA_ "U_U611_U625_MY20_Phev_Rx" SG_ 125 BrkTot_Tq_Actl 1;
BA_ "U_CX482_CX483_MY20_Hev_Rx" SG_ 125 BrkTot_Tq_Actl 1;
BA_ "U_CX482_CX483_MY20_Gas_Rx" SG_ 125 BrkTot_Tq_Actl 1;
BA_ "U_CX482_CX483_MY20_Diesel_Rx" SG_ 125 BrkTot_Tq_Actl 1;
BA_ "U_U611_U625_MY20_Hev_Rx" SG_ 125 BrkTot_Tq_Actl 1;
BA_ "U_U611_U625_MY20_Gas_Rx" SG_ 125 BrkTot_Tq_Actl 1;
BA_ "U_U611_U625_MY20_Diesel_Rx" SG_ 125 BrkTot_Tq_Actl 1;
BA_ "U_C490_MY18_Rx" SG_ 125 BrkTot_Tq_Actl 1;
BA_ "U_B562_MY18_Gas_Rx" SG_ 125 BrkTot_Tq_Actl 1;
BA_ "U_C519_MY18_5_Gas_Rx" SG_ 125 BrkTot_Tq_Actl 1;
BA_ "U_C519_MY18_5_Diesel_Rx" SG_ 125 BrkTot_Tq_Actl 1;
BA_ "U_B515_MCA_MY17_Gas_Rx" SG_ 125 BrkTot_Tq_Actl 1;
BA_ "U_B515_MCA_MY17_Diesel_Rx" SG_ 125 BrkTot_Tq_Actl 1;
BA_ "U_B479_MY17_Diesel_Rx" SG_ 125 BrkTot_Tq_Actl 1;
BA_ "U_B479_MY17_Gas_Rx" SG_ 125 BrkTot_Tq_Actl 1;
BA_ "U_CX482_CX483_MY20_Hev_Tx" SG_ 125 HsaStat_D_Actl 1;
BA_ "U_CX482_CX483_MY20_Gas_Tx" SG_ 125 HsaStat_D_Actl 1;
BA_ "U_CX482_CX483_MY20_Diesel_Tx" SG_ 125 HsaStat_D_Actl 1;
BA_ "U_U611_U625_MY20_Hev_Tx" SG_ 125 HsaStat_D_Actl 1;
BA_ "U_U611_U625_MY20_Gas_Tx" SG_ 125 HsaStat_D_Actl 1;
BA_ "U_U611_U625_MY20_Diesel_Tx" SG_ 125 HsaStat_D_Actl 1;
BA_ "U_B500_MY18_Diesel_Tx" SG_ 125 HsaStat_D_Actl 1;
BA_ "U_B500_MY18_Gas_Tx" SG_ 125 HsaStat_D_Actl 1;
BA_ "U_C490_MY18_Tx" SG_ 125 HsaStat_D_Actl 1;
BA_ "U_B562_MY18_Gas_Tx" SG_ 125 HsaStat_D_Actl 1;
BA_ "U_C519_MY18_5_Gas_Tx" SG_ 125 HsaStat_D_Actl 1;
BA_ "U_C519_MY18_5_Diesel_Tx" SG_ 125 HsaStat_D_Actl 1;
BA_ "U_B515_MCA_MY17_Gas_Tx" SG_ 125 HsaStat_D_Actl 1;
BA_ "U_B515_MCA_MY17_Diesel_Tx" SG_ 125 HsaStat_D_Actl 1;
BA_ "U_B479_MY17_Diesel_Tx" SG_ 125 HsaStat_D_Actl 1;
BA_ "U_B479_MY17_Gas_Tx" SG_ 125 HsaStat_D_Actl 1;
BA_ "U_B562LC_MY15_Gas_Tx" SG_ 125 HsaStat_D_Actl 1;
BA_ "U_B562LC_MY15_Diesel_Tx" SG_ 125 HsaStat_D_Actl 1;
BA_ "CrossOver_InfoCAN" SG_ 125 HsaStat_D_Actl 1;
BA_ "U_U611_U625_MY20_Hev_Tx" SG_ 119 VehTrvlDir_D_Stat 1;
BA_ "U_U611_U625_MY20_Gas_Tx" SG_ 119 VehTrvlDir_D_Stat 1;
BA_ "U_U611_U625_MY20_Diesel_Tx" SG_ 119 VehTrvlDir_D_Stat 1;
BA_ "U_B562_MY18_Gas_Tx" SG_ 119 VehTrvlDir_D_Stat 1;
BA_ "U_U611_U625_MY20_Hev_Rx" SG_ 119 VehTrvlDir_D_Stat 1;
BA_ "U_U611_U625_MY20_Gas_Rx" SG_ 119 VehTrvlDir_D_Stat 1;
BA_ "U_U611_U625_MY20_Diesel_Rx" SG_ 119 VehTrvlDir_D_Stat 1;
BA_ "GenSigStartValue" SG_ 119 VehTrvlDir_D_Stat 6;
BA_ "U_CX482_CX483_MY20_Hev_Tx" SG_ 119 VehOverGnd_V_Est 1;
BA_ "U_CX482_CX483_MY20_Gas_Tx" SG_ 119 VehOverGnd_V_Est 1;
BA_ "U_CX482_CX483_MY20_Diesel_Tx" SG_ 119 VehOverGnd_V_Est 1;
BA_ "U_U611_U625_MY20_Hev_Tx" SG_ 119 VehOverGnd_V_Est 1;
BA_ "U_U611_U625_MY20_Gas_Tx" SG_ 119 VehOverGnd_V_Est 1;
BA_ "U_U611_U625_MY20_Diesel_Tx" SG_ 119 VehOverGnd_V_Est 1;
BA_ "U_B500_MY18_Diesel_Tx" SG_ 119 VehOverGnd_V_Est 1;
BA_ "U_B500_MY18_Gas_Tx" SG_ 119 VehOverGnd_V_Est 1;
BA_ "U_C490_MY18_Tx" SG_ 119 VehOverGnd_V_Est 1;
BA_ "U_B562_MY18_Gas_Tx" SG_ 119 VehOverGnd_V_Est 1;
BA_ "U_C519_MY18_5_Gas_Tx" SG_ 119 VehOverGnd_V_Est 1;
BA_ "U_C519_MY18_5_Diesel_Tx" SG_ 119 VehOverGnd_V_Est 1;
BA_ "U_B515_MCA_MY17_Gas_Tx" SG_ 119 VehOverGnd_V_Est 1;
BA_ "U_B515_MCA_MY17_Diesel_Tx" SG_ 119 VehOverGnd_V_Est 1;
BA_ "U_B479_MY17_Diesel_Tx" SG_ 119 VehOverGnd_V_Est 1;
BA_ "U_B479_MY17_Gas_Tx" SG_ 119 VehOverGnd_V_Est 1;
BA_ "U_B562LC_MY15_Gas_Tx" SG_ 119 VehOverGnd_V_Est 1;
BA_ "U_B562LC_MY15_Diesel_Tx" SG_ 119 VehOverGnd_V_Est 1;
BA_ "U_B479_MY17_Diesel_Rx" SG_ 119 VehOverGnd_V_Est 1;
BA_ "U_B479_MY17_Gas_Rx" SG_ 119 VehOverGnd_V_Est 1;
BA_ "U_U611_U625_MY20_Phev_Rx" SG_ 119 VehOverGnd_V_Est 1;
BA_ "U_CX482_CX483_MY20_Hev_Rx" SG_ 119 VehOverGnd_V_Est 1;
BA_ "U_CX482_CX483_MY20_Gas_Rx" SG_ 119 VehOverGnd_V_Est 1;
BA_ "U_CX482_CX483_MY20_Diesel_Rx" SG_ 119 VehOverGnd_V_Est 1;
BA_ "U_U611_U625_MY20_Hev_Rx" SG_ 119 VehOverGnd_V_Est 1;
BA_ "U_U611_U625_MY20_Gas_Rx" SG_ 119 VehOverGnd_V_Est 1;
BA_ "U_U611_U625_MY20_Diesel_Rx" SG_ 119 VehOverGnd_V_Est 1;
BA_ "U_C519_MY18_5_Gas_Rx" SG_ 119 VehOverGnd_V_Est 1;
BA_ "U_C519_MY18_5_Diesel_Rx" SG_ 119 VehOverGnd_V_Est 1;
BA_ "U_CX482_CX483_MY20_Hev_Tx" SG_ 119 VehLongComp_A_Actl 1;
BA_ "U_CX482_CX483_MY20_Gas_Tx" SG_ 119 VehLongComp_A_Actl 1;
BA_ "U_CX482_CX483_MY20_Diesel_Tx" SG_ 119 VehLongComp_A_Actl 1;
BA_ "U_U611_U625_MY20_Hev_Tx" SG_ 119 VehLongComp_A_Actl 1;
BA_ "U_U611_U625_MY20_Gas_Tx" SG_ 119 VehLongComp_A_Actl 1;
BA_ "U_U611_U625_MY20_Diesel_Tx" SG_ 119 VehLongComp_A_Actl 1;
BA_ "U_B500_MY18_Diesel_Tx" SG_ 119 VehLongComp_A_Actl 1;
BA_ "U_B500_MY18_Gas_Tx" SG_ 119 VehLongComp_A_Actl 1;
BA_ "U_C490_MY18_Tx" SG_ 119 VehLongComp_A_Actl 1;
BA_ "U_B562_MY18_Gas_Tx" SG_ 119 VehLongComp_A_Actl 1;
BA_ "U_C519_MY18_5_Gas_Tx" SG_ 119 VehLongComp_A_Actl 1;
BA_ "U_C519_MY18_5_Diesel_Tx" SG_ 119 VehLongComp_A_Actl 1;
BA_ "U_B515_MCA_MY17_Gas_Tx" SG_ 119 VehLongComp_A_Actl 1;
BA_ "U_B515_MCA_MY17_Diesel_Tx" SG_ 119 VehLongComp_A_Actl 1;
BA_ "U_B479_MY17_Diesel_Tx" SG_ 119 VehLongComp_A_Actl 1;
BA_ "U_B479_MY17_Gas_Tx" SG_ 119 VehLongComp_A_Actl 1;
BA_ "U_B562LC_MY15_Gas_Tx" SG_ 119 VehLongComp_A_Actl 1;
BA_ "U_B562LC_MY15_Diesel_Tx" SG_ 119 VehLongComp_A_Actl 1;
BA_ "U_CX482_CX483_MY20_Hev_Rx" SG_ 119 VehLongComp_A_Actl 1;
BA_ "U_CX482_CX483_MY20_Gas_Rx" SG_ 119 VehLongComp_A_Actl 1;
BA_ "U_CX482_CX483_MY20_Diesel_Rx" SG_ 119 VehLongComp_A_Actl 1;
BA_ "U_B500_MY18_Diesel_Rx" SG_ 119 VehLongComp_A_Actl 1;
BA_ "U_B500_MY18_Gas_Rx" SG_ 119 VehLongComp_A_Actl 1;
BA_ "U_B479_MY17_Diesel_Rx" SG_ 119 VehLongComp_A_Actl 1;
BA_ "U_B479_MY17_Gas_Rx" SG_ 119 VehLongComp_A_Actl 1;
BA_ "U_U611_U625_MY20_Phev_Rx" SG_ 119 VehLongComp_A_Actl 1;
BA_ "U_U611_U625_MY20_Hev_Rx" SG_ 119 VehLongComp_A_Actl 1;
BA_ "U_U611_U625_MY20_Gas_Rx" SG_ 119 VehLongComp_A_Actl 1;
BA_ "U_U611_U625_MY20_Diesel_Rx" SG_ 119 VehLongComp_A_Actl 1;
BA_ "U_C519_MY18_5_Gas_Rx" SG_ 119 VehLongComp_A_Actl 1;
BA_ "U_C519_MY18_5_Diesel_Rx" SG_ 119 VehLongComp_A_Actl 1;
BA_ "GenSigStartValue" SG_ 119 VehLongComp_A_Actl 1022;
BA_ "U_CX482_CX483_MY20_Hev_Tx" SG_ 119 VehLatComp_A_Actl 1;
BA_ "U_CX482_CX483_MY20_Gas_Tx" SG_ 119 VehLatComp_A_Actl 1;
BA_ "U_CX482_CX483_MY20_Diesel_Tx" SG_ 119 VehLatComp_A_Actl 1;
BA_ "U_U611_U625_MY20_Hev_Tx" SG_ 119 VehLatComp_A_Actl 1;
BA_ "U_U611_U625_MY20_Gas_Tx" SG_ 119 VehLatComp_A_Actl 1;
BA_ "U_U611_U625_MY20_Diesel_Tx" SG_ 119 VehLatComp_A_Actl 1;
BA_ "U_B500_MY18_Diesel_Tx" SG_ 119 VehLatComp_A_Actl 1;
BA_ "U_B500_MY18_Gas_Tx" SG_ 119 VehLatComp_A_Actl 1;
BA_ "U_C490_MY18_Tx" SG_ 119 VehLatComp_A_Actl 1;
BA_ "U_B562_MY18_Gas_Tx" SG_ 119 VehLatComp_A_Actl 1;
BA_ "U_C519_MY18_5_Gas_Tx" SG_ 119 VehLatComp_A_Actl 1;
BA_ "U_C519_MY18_5_Diesel_Tx" SG_ 119 VehLatComp_A_Actl 1;
BA_ "U_B515_MCA_MY17_Gas_Tx" SG_ 119 VehLatComp_A_Actl 1;
BA_ "U_B515_MCA_MY17_Diesel_Tx" SG_ 119 VehLatComp_A_Actl 1;
BA_ "U_B479_MY17_Diesel_Tx" SG_ 119 VehLatComp_A_Actl 1;
BA_ "U_B479_MY17_Gas_Tx" SG_ 119 VehLatComp_A_Actl 1;
BA_ "U_B562LC_MY15_Gas_Tx" SG_ 119 VehLatComp_A_Actl 1;
BA_ "U_B562LC_MY15_Diesel_Tx" SG_ 119 VehLatComp_A_Actl 1;
BA_ "U_CX482_CX483_MY20_Hev_Rx" SG_ 119 VehLatComp_A_Actl 1;
BA_ "U_CX482_CX483_MY20_Gas_Rx" SG_ 119 VehLatComp_A_Actl 1;
BA_ "U_CX482_CX483_MY20_Diesel_Rx" SG_ 119 VehLatComp_A_Actl 1;
BA_ "U_B500_MY18_Diesel_Rx" SG_ 119 VehLatComp_A_Actl 1;
BA_ "U_B500_MY18_Gas_Rx" SG_ 119 VehLatComp_A_Actl 1;
BA_ "U_B479_MY17_Diesel_Rx" SG_ 119 VehLatComp_A_Actl 1;
BA_ "U_B479_MY17_Gas_Rx" SG_ 119 VehLatComp_A_Actl 1;
BA_ "U_U611_U625_MY20_Phev_Rx" SG_ 119 VehLatComp_A_Actl 1;
BA_ "U_U611_U625_MY20_Hev_Rx" SG_ 119 VehLatComp_A_Actl 1;
BA_ "U_U611_U625_MY20_Gas_Rx" SG_ 119 VehLatComp_A_Actl 1;
BA_ "U_U611_U625_MY20_Diesel_Rx" SG_ 119 VehLatComp_A_Actl 1;
BA_ "U_C519_MY18_5_Gas_Rx" SG_ 119 VehLatComp_A_Actl 1;
BA_ "U_C519_MY18_5_Diesel_Rx" SG_ 119 VehLatComp_A_Actl 1;
BA_ "GenSigStartValue" SG_ 119 VehLatComp_A_Actl 1022;
BA_ "U_CX482_CX483_MY20_Hev_Tx" SG_ 119 VehYawComp_W_Actl 1;
BA_ "U_CX482_CX483_MY20_Gas_Tx" SG_ 119 VehYawComp_W_Actl 1;
BA_ "U_CX482_CX483_MY20_Diesel_Tx" SG_ 119 VehYawComp_W_Actl 1;
BA_ "U_U611_U625_MY20_Hev_Tx" SG_ 119 VehYawComp_W_Actl 1;
BA_ "U_U611_U625_MY20_Gas_Tx" SG_ 119 VehYawComp_W_Actl 1;
BA_ "U_U611_U625_MY20_Diesel_Tx" SG_ 119 VehYawComp_W_Actl 1;
BA_ "U_B500_MY18_Diesel_Tx" SG_ 119 VehYawComp_W_Actl 1;
BA_ "U_B500_MY18_Gas_Tx" SG_ 119 VehYawComp_W_Actl 1;
BA_ "U_C490_MY18_Tx" SG_ 119 VehYawComp_W_Actl 1;
BA_ "U_B562_MY18_Gas_Tx" SG_ 119 VehYawComp_W_Actl 1;
BA_ "U_C519_MY18_5_Gas_Tx" SG_ 119 VehYawComp_W_Actl 1;
BA_ "U_C519_MY18_5_Diesel_Tx" SG_ 119 VehYawComp_W_Actl 1;
BA_ "U_B515_MCA_MY17_Gas_Tx" SG_ 119 VehYawComp_W_Actl 1;
BA_ "U_B515_MCA_MY17_Diesel_Tx" SG_ 119 VehYawComp_W_Actl 1;
BA_ "U_B479_MY17_Diesel_Tx" SG_ 119 VehYawComp_W_Actl 1;
BA_ "U_B479_MY17_Gas_Tx" SG_ 119 VehYawComp_W_Actl 1;
BA_ "U_B562LC_MY15_Gas_Tx" SG_ 119 VehYawComp_W_Actl 1;
BA_ "U_B562LC_MY15_Diesel_Tx" SG_ 119 VehYawComp_W_Actl 1;
BA_ "U_U611_U625_MY20_Phev_Rx" SG_ 119 VehYawComp_W_Actl 1;
BA_ "U_CX482_CX483_MY20_Hev_Rx" SG_ 119 VehYawComp_W_Actl 1;
BA_ "U_CX482_CX483_MY20_Gas_Rx" SG_ 119 VehYawComp_W_Actl 1;
BA_ "U_CX482_CX483_MY20_Diesel_Rx" SG_ 119 VehYawComp_W_Actl 1;
BA_ "U_U611_U625_MY20_Hev_Rx" SG_ 119 VehYawComp_W_Actl 1;
BA_ "U_U611_U625_MY20_Gas_Rx" SG_ 119 VehYawComp_W_Actl 1;
BA_ "U_U611_U625_MY20_Diesel_Rx" SG_ 119 VehYawComp_W_Actl 1;
BA_ "U_B500_MY18_Diesel_Rx" SG_ 119 VehYawComp_W_Actl 1;
BA_ "U_B500_MY18_Gas_Rx" SG_ 119 VehYawComp_W_Actl 1;
BA_ "U_B479_MY17_Diesel_Rx" SG_ 119 VehYawComp_W_Actl 1;
BA_ "U_B479_MY17_Gas_Rx" SG_ 119 VehYawComp_W_Actl 1;
BA_ "U_C519_MY18_5_Gas_Rx" SG_ 119 VehYawComp_W_Actl 1;
BA_ "U_C519_MY18_5_Diesel_Rx" SG_ 119 VehYawComp_W_Actl 1;
BA_ "GenSigStartValue" SG_ 119 VehYawComp_W_Actl 4094;
BA_ "CrossOver_InfoCAN" SG_ 119 VehYawComp_W_Actl 1;
BA_ "U_CX482_CX483_MY20_Hev_Tx" SG_ 119 VehYaw_W_Rq 1;
BA_ "U_CX482_CX483_MY20_Gas_Tx" SG_ 119 VehYaw_W_Rq 1;
BA_ "U_CX482_CX483_MY20_Diesel_Tx" SG_ 119 VehYaw_W_Rq 1;
BA_ "U_U611_U625_MY20_Hev_Tx" SG_ 119 VehYaw_W_Rq 1;
BA_ "U_U611_U625_MY20_Gas_Tx" SG_ 119 VehYaw_W_Rq 1;
BA_ "U_U611_U625_MY20_Diesel_Tx" SG_ 119 VehYaw_W_Rq 1;
BA_ "U_B500_MY18_Diesel_Tx" SG_ 119 VehYaw_W_Rq 1;
BA_ "U_B500_MY18_Gas_Tx" SG_ 119 VehYaw_W_Rq 1;
BA_ "U_C490_MY18_Tx" SG_ 119 VehYaw_W_Rq 1;
BA_ "U_B562_MY18_Gas_Tx" SG_ 119 VehYaw_W_Rq 1;
BA_ "U_C519_MY18_5_Gas_Tx" SG_ 119 VehYaw_W_Rq 1;
BA_ "U_C519_MY18_5_Diesel_Tx" SG_ 119 VehYaw_W_Rq 1;
BA_ "U_B515_MCA_MY17_Gas_Tx" SG_ 119 VehYaw_W_Rq 1;
BA_ "U_B515_MCA_MY17_Diesel_Tx" SG_ 119 VehYaw_W_Rq 1;
BA_ "U_B479_MY17_Diesel_Tx" SG_ 119 VehYaw_W_Rq 1;
BA_ "U_B479_MY17_Gas_Tx" SG_ 119 VehYaw_W_Rq 1;
BA_ "U_B562LC_MY15_Gas_Tx" SG_ 119 VehYaw_W_Rq 1;
BA_ "U_B562LC_MY15_Diesel_Tx" SG_ 119 VehYaw_W_Rq 1;
BA_ "GenSigStartValue" SG_ 119 VehYaw_W_Rq 4094;
BA_ "CrossOver_InfoCAN" SG_ 119 VehYaw_W_Rq 1;
BA_ "U_B515_MCA_MY17_Gas_Tx" SG_ 118 BrkTerrMdeChng_D_Rdy 1;
BA_ "U_B515_MCA_MY17_Diesel_Tx" SG_ 118 BrkTerrMdeChng_D_Rdy 1;
BA_ "U_B515_MCA_MY17_Gas_Tx" SG_ 118 BrkTerrMde_D_Actl 1;
BA_ "U_B515_MCA_MY17_Diesel_Tx" SG_ 118 BrkTerrMde_D_Actl 1;
BA_ "U_U611_U625_MY20_Hev_Tx" SG_ 118 AwdLck_Tq_RqMx 1;
BA_ "U_U611_U625_MY20_Gas_Tx" SG_ 118 AwdLck_Tq_RqMx 1;
BA_ "U_U611_U625_MY20_Diesel_Tx" SG_ 118 AwdLck_Tq_RqMx 1;
BA_ "U_B515_MCA_MY17_Gas_Tx" SG_ 118 AwdLck_Tq_RqMx 1;
BA_ "U_B515_MCA_MY17_Diesel_Tx" SG_ 118 AwdLck_Tq_RqMx 1;
BA_ "U_U611_U625_MY20_Hev_Tx" SG_ 118 AwdLck_Tq_RqMn 1;
BA_ "U_U611_U625_MY20_Gas_Tx" SG_ 118 AwdLck_Tq_RqMn 1;
BA_ "U_U611_U625_MY20_Diesel_Tx" SG_ 118 AwdLck_Tq_RqMn 1;
BA_ "U_B515_MCA_MY17_Gas_Tx" SG_ 118 AwdLck_Tq_RqMn 1;
BA_ "U_B515_MCA_MY17_Diesel_Tx" SG_ 118 AwdLck_Tq_RqMn 1;
BA_ "U_U611_U625_MY20_Hev_Tx" SG_ 118 DrvSte_D_Stat 1;
BA_ "U_U611_U625_MY20_Gas_Tx" SG_ 118 DrvSte_D_Stat 1;
BA_ "U_U611_U625_MY20_Diesel_Tx" SG_ 118 DrvSte_D_Stat 1;
BA_ "U_B515_MCA_MY17_Gas_Tx" SG_ 118 DrvSte_D_Stat 1;
BA_ "U_B515_MCA_MY17_Diesel_Tx" SG_ 118 DrvSte_D_Stat 1;
BA_ "U_B479_MY17_Diesel_Tx" SG_ 118 DrvSte_D_Stat 1;
BA_ "U_B479_MY17_Gas_Tx" SG_ 118 DrvSte_D_Stat 1;
BA_ "GenSigSendType" SG_ 118 DrvSte_D_Stat 3;
BA_ "U_U611_U625_MY20_Hev_Tx" SG_ 118 DrvSte_Tq_Rq 1;
BA_ "U_U611_U625_MY20_Gas_Tx" SG_ 118 DrvSte_Tq_Rq 1;
BA_ "U_U611_U625_MY20_Diesel_Tx" SG_ 118 DrvSte_Tq_Rq 1;
BA_ "U_B515_MCA_MY17_Gas_Tx" SG_ 118 DrvSte_Tq_Rq 1;
BA_ "U_B515_MCA_MY17_Diesel_Tx" SG_ 118 DrvSte_Tq_Rq 1;
BA_ "U_B479_MY17_Diesel_Tx" SG_ 118 DrvSte_Tq_Rq 1;
BA_ "U_B479_MY17_Gas_Tx" SG_ 118 DrvSte_Tq_Rq 1;
BA_ "GenSigStartValue" SG_ 118 DrvSte_Tq_Rq 128;
BA_ "U_LC1_B500_MY18_Gas_Tx" SG_ 118 EmgcyBrkLamp_D_Rq 1;
BA_ "U_LC1_B500_MY18_Diesel_Tx" SG_ 118 EmgcyBrkLamp_D_Rq 1;
BA_ "U_CX482_CX483_MY20_Hev_Tx" SG_ 118 EmgcyBrkLamp_D_Rq 1;
BA_ "U_CX482_CX483_MY20_Gas_Tx" SG_ 118 EmgcyBrkLamp_D_Rq 1;
BA_ "U_CX482_CX483_MY20_Diesel_Tx" SG_ 118 EmgcyBrkLamp_D_Rq 1;
BA_ "U_U611_U625_MY20_Hev_Tx" SG_ 118 EmgcyBrkLamp_D_Rq 1;
BA_ "U_U611_U625_MY20_Gas_Tx" SG_ 118 EmgcyBrkLamp_D_Rq 1;
BA_ "U_U611_U625_MY20_Diesel_Tx" SG_ 118 EmgcyBrkLamp_D_Rq 1;
BA_ "U_B500_MY18_Diesel_Tx" SG_ 118 EmgcyBrkLamp_D_Rq 1;
BA_ "U_B500_MY18_Gas_Tx" SG_ 118 EmgcyBrkLamp_D_Rq 1;
BA_ "U_C490_MY18_Tx" SG_ 118 EmgcyBrkLamp_D_Rq 1;
BA_ "U_B562_MY18_Gas_Tx" SG_ 118 EmgcyBrkLamp_D_Rq 1;
BA_ "U_C519_MY18_5_Gas_Tx" SG_ 118 EmgcyBrkLamp_D_Rq 1;
BA_ "U_C519_MY18_5_Diesel_Tx" SG_ 118 EmgcyBrkLamp_D_Rq 1;
BA_ "U_B515_MCA_MY17_Gas_Tx" SG_ 118 EmgcyBrkLamp_D_Rq 1;
BA_ "U_B515_MCA_MY17_Diesel_Tx" SG_ 118 EmgcyBrkLamp_D_Rq 1;
BA_ "U_B479_MY17_Diesel_Tx" SG_ 118 EmgcyBrkLamp_D_Rq 1;
BA_ "U_B479_MY17_Gas_Tx" SG_ 118 EmgcyBrkLamp_D_Rq 1;
BA_ "GenSigSendType" SG_ 118 EmgcyBrkLamp_D_Rq 3;
BA_ "U_LC1_B500_MY18_Gas_Tx" SG_ 118 StopLamp_B_RqBrk 1;
BA_ "U_LC1_B500_MY18_Diesel_Tx" SG_ 118 StopLamp_B_RqBrk 1;
BA_ "U_CX482_CX483_MY20_Hev_Tx" SG_ 118 StopLamp_B_RqBrk 1;
BA_ "U_CX482_CX483_MY20_Gas_Tx" SG_ 118 StopLamp_B_RqBrk 1;
BA_ "U_CX482_CX483_MY20_Diesel_Tx" SG_ 118 StopLamp_B_RqBrk 1;
BA_ "U_U611_U625_MY20_Hev_Tx" SG_ 118 StopLamp_B_RqBrk 1;
BA_ "U_U611_U625_MY20_Gas_Tx" SG_ 118 StopLamp_B_RqBrk 1;
BA_ "U_U611_U625_MY20_Diesel_Tx" SG_ 118 StopLamp_B_RqBrk 1;
BA_ "U_B500_MY18_Diesel_Tx" SG_ 118 StopLamp_B_RqBrk 1;
BA_ "U_B500_MY18_Gas_Tx" SG_ 118 StopLamp_B_RqBrk 1;
BA_ "U_C490_MY18_Tx" SG_ 118 StopLamp_B_RqBrk 1;
BA_ "U_B562_MY18_Gas_Tx" SG_ 118 StopLamp_B_RqBrk 1;
BA_ "U_C519_MY18_5_Gas_Tx" SG_ 118 StopLamp_B_RqBrk 1;
BA_ "U_C519_MY18_5_Diesel_Tx" SG_ 118 StopLamp_B_RqBrk 1;
BA_ "U_B515_MCA_MY17_Gas_Tx" SG_ 118 StopLamp_B_RqBrk 1;
BA_ "U_B515_MCA_MY17_Diesel_Tx" SG_ 118 StopLamp_B_RqBrk 1;
BA_ "U_B479_MY17_Diesel_Tx" SG_ 118 StopLamp_B_RqBrk 1;
BA_ "U_B479_MY17_Gas_Tx" SG_ 118 StopLamp_B_RqBrk 1;
BA_ "GenSigSendType" SG_ 118 StopLamp_B_RqBrk 3;
BA_ "U_B515_MCA_MY17_Gas_Tx" SG_ 118 VehDynamicsSOS 1;
BA_ "U_B515_MCA_MY17_Diesel_Tx" SG_ 118 VehDynamicsSOS 1;
BA_ "U_B479_MY17_Diesel_Tx" SG_ 118 VehDynamicsSOS 1;
BA_ "U_B479_MY17_Gas_Tx" SG_ 118 VehDynamicsSOS 1;
BA_ "GenSigSendType" SG_ 118 VehDynamicsSOS 3;
BA_ "CrossOver_InfoCAN" SG_ 118 VehDynamicsSOS 1;
BA_ "U_U611_U625_MY20_Hev_Tx" SG_ 118 SteWhlCompAnEst_D_Qf 1;
BA_ "U_U611_U625_MY20_Gas_Tx" SG_ 118 SteWhlCompAnEst_D_Qf 1;
BA_ "U_U611_U625_MY20_Diesel_Tx" SG_ 118 SteWhlCompAnEst_D_Qf 1;
BA_ "U_B479_MY17_Diesel_Tx" SG_ 118 SteWhlCompAnEst_D_Qf 1;
BA_ "U_B479_MY17_Gas_Tx" SG_ 118 SteWhlCompAnEst_D_Qf 1;
BA_ "U_CX482_CX483_MY20_Hev_Rx" SG_ 118 SteWhlCompAnEst_D_Qf 1;
BA_ "U_CX482_CX483_MY20_Gas_Rx" SG_ 118 SteWhlCompAnEst_D_Qf 1;
BA_ "U_CX482_CX483_MY20_Diesel_Rx" SG_ 118 SteWhlCompAnEst_D_Qf 1;
BA_ "U_U611_U625_MY20_Hev_Rx" SG_ 118 SteWhlCompAnEst_D_Qf 1;
BA_ "U_U611_U625_MY20_Gas_Rx" SG_ 118 SteWhlCompAnEst_D_Qf 1;
BA_ "U_U611_U625_MY20_Diesel_Rx" SG_ 118 SteWhlCompAnEst_D_Qf 1;
BA_ "U_C519_MY18_5_Gas_Rx" SG_ 118 SteWhlCompAnEst_D_Qf 1;
BA_ "U_C519_MY18_5_Diesel_Rx" SG_ 118 SteWhlCompAnEst_D_Qf 1;
BA_ "U_B479_MY17_Diesel_Rx" SG_ 118 SteWhlCompAnEst_D_Qf 1;
BA_ "U_B479_MY17_Gas_Rx" SG_ 118 SteWhlCompAnEst_D_Qf 1;
BA_ "U_U611_U625_MY20_Hev_Tx" SG_ 118 SteWhlComp_An_Est 1;
BA_ "U_U611_U625_MY20_Gas_Tx" SG_ 118 SteWhlComp_An_Est 1;
BA_ "U_U611_U625_MY20_Diesel_Tx" SG_ 118 SteWhlComp_An_Est 1;
BA_ "U_B479_MY17_Diesel_Tx" SG_ 118 SteWhlComp_An_Est 1;
BA_ "U_B479_MY17_Gas_Tx" SG_ 118 SteWhlComp_An_Est 1;
BA_ "U_CX482_CX483_MY20_Hev_Rx" SG_ 118 SteWhlComp_An_Est 1;
BA_ "U_CX482_CX483_MY20_Gas_Rx" SG_ 118 SteWhlComp_An_Est 1;
BA_ "U_CX482_CX483_MY20_Diesel_Rx" SG_ 118 SteWhlComp_An_Est 1;
BA_ "U_U611_U625_MY20_Hev_Rx" SG_ 118 SteWhlComp_An_Est 1;
BA_ "U_U611_U625_MY20_Gas_Rx" SG_ 118 SteWhlComp_An_Est 1;
BA_ "U_U611_U625_MY20_Diesel_Rx" SG_ 118 SteWhlComp_An_Est 1;
BA_ "U_C519_MY18_5_Gas_Rx" SG_ 118 SteWhlComp_An_Est 1;
BA_ "U_C519_MY18_5_Diesel_Rx" SG_ 118 SteWhlComp_An_Est 1;
BA_ "U_B479_MY17_Diesel_Rx" SG_ 118 SteWhlComp_An_Est 1;
BA_ "U_B479_MY17_Gas_Rx" SG_ 118 SteWhlComp_An_Est 1;
BA_ "U_CX482_CX483_MY20_Hev_Tx" SG_ 1713 UUDTABSResponse2 1;
BA_ "U_CX482_CX483_MY20_Gas_Tx" SG_ 1713 UUDTABSResponse2 1;
BA_ "U_CX482_CX483_MY20_Diesel_Tx" SG_ 1713 UUDTABSResponse2 1;
BA_ "U_U611_U625_MY20_Hev_Tx" SG_ 1713 UUDTABSResponse2 1;
BA_ "U_U611_U625_MY20_Gas_Tx" SG_ 1713 UUDTABSResponse2 1;
BA_ "U_U611_U625_MY20_Diesel_Tx" SG_ 1713 UUDTABSResponse2 1;
BA_ "U_B500_MY18_Diesel_Tx" SG_ 1713 UUDTABSResponse2 1;
BA_ "U_B500_MY18_Gas_Tx" SG_ 1713 UUDTABSResponse2 1;
BA_ "U_C490_MY18_Tx" SG_ 1713 UUDTABSResponse2 1;
BA_ "U_B562_MY18_Gas_Tx" SG_ 1713 UUDTABSResponse2 1;
BA_ "U_C519_MY18_5_Gas_Tx" SG_ 1713 UUDTABSResponse2 1;
BA_ "U_C519_MY18_5_Diesel_Tx" SG_ 1713 UUDTABSResponse2 1;
BA_ "U_B515_MCA_MY17_Gas_Tx" SG_ 1713 UUDTABSResponse2 1;
BA_ "U_B515_MCA_MY17_Diesel_Tx" SG_ 1713 UUDTABSResponse2 1;
BA_ "U_B479_MY17_Diesel_Tx" SG_ 1713 UUDTABSResponse2 1;
BA_ "U_B479_MY17_Gas_Tx" SG_ 1713 UUDTABSResponse2 1;
BA_ "U_B562LC_MY15_Gas_Tx" SG_ 1713 UUDTABSResponse2 1;
BA_ "U_B562LC_MY15_Diesel_Tx" SG_ 1713 UUDTABSResponse2 1;
BA_ "GenSigSendType" SG_ 1713 UUDTABSResponse2 3;
BA_ "U_CX482_CX483_MY20_Hev_Tx" SG_ 1712 UUDTABSResponse1 1;
BA_ "U_CX482_CX483_MY20_Gas_Tx" SG_ 1712 UUDTABSResponse1 1;
BA_ "U_CX482_CX483_MY20_Diesel_Tx" SG_ 1712 UUDTABSResponse1 1;
BA_ "U_U611_U625_MY20_Hev_Tx" SG_ 1712 UUDTABSResponse1 1;
BA_ "U_U611_U625_MY20_Gas_Tx" SG_ 1712 UUDTABSResponse1 1;
BA_ "U_U611_U625_MY20_Diesel_Tx" SG_ 1712 UUDTABSResponse1 1;
BA_ "U_B500_MY18_Diesel_Tx" SG_ 1712 UUDTABSResponse1 1;
BA_ "U_B500_MY18_Gas_Tx" SG_ 1712 UUDTABSResponse1 1;
BA_ "U_C490_MY18_Tx" SG_ 1712 UUDTABSResponse1 1;
BA_ "U_B562_MY18_Gas_Tx" SG_ 1712 UUDTABSResponse1 1;
BA_ "U_C519_MY18_5_Gas_Tx" SG_ 1712 UUDTABSResponse1 1;
BA_ "U_C519_MY18_5_Diesel_Tx" SG_ 1712 UUDTABSResponse1 1;
BA_ "U_B515_MCA_MY17_Gas_Tx" SG_ 1712 UUDTABSResponse1 1;
BA_ "U_B515_MCA_MY17_Diesel_Tx" SG_ 1712 UUDTABSResponse1 1;
BA_ "U_B479_MY17_Diesel_Tx" SG_ 1712 UUDTABSResponse1 1;
BA_ "U_B479_MY17_Gas_Tx" SG_ 1712 UUDTABSResponse1 1;
BA_ "U_B562LC_MY15_Gas_Tx" SG_ 1712 UUDTABSResponse1 1;
BA_ "U_B562LC_MY15_Diesel_Tx" SG_ 1712 UUDTABSResponse1 1;
BA_ "GenSigSendType" SG_ 1712 UUDTABSResponse1 3;
BA_ "GenSigTimeoutTime_GWM" SG_ 75 VedsPasKneeBag_D_Ltchd 300;
BA_ "U_CX482_CX483_MY20_Hev_Tx" SG_ 75 VedsPasKneeBag_D_Ltchd 1;
BA_ "U_CX482_CX483_MY20_Gas_Tx" SG_ 75 VedsPasKneeBag_D_Ltchd 1;
BA_ "U_CX482_CX483_MY20_Diesel_Tx" SG_ 75 VedsPasKneeBag_D_Ltchd 1;
BA_ "U_U611_U625_MY20_Hev_Tx" SG_ 75 VedsPasKneeBag_D_Ltchd 1;
BA_ "U_U611_U625_MY20_Gas_Tx" SG_ 75 VedsPasKneeBag_D_Ltchd 1;
BA_ "U_U611_U625_MY20_Diesel_Tx" SG_ 75 VedsPasKneeBag_D_Ltchd 1;
BA_ "U_B500_MY18_Diesel_Tx" SG_ 75 VedsPasKneeBag_D_Ltchd 1;
BA_ "U_B500_MY18_Gas_Tx" SG_ 75 VedsPasKneeBag_D_Ltchd 1;
BA_ "U_C490_MY18_Tx" SG_ 75 VedsPasKneeBag_D_Ltchd 1;
BA_ "U_B562_MY18_Gas_Tx" SG_ 75 VedsPasKneeBag_D_Ltchd 1;
BA_ "U_C519_MY18_5_Gas_Tx" SG_ 75 VedsPasKneeBag_D_Ltchd 1;
BA_ "U_C519_MY18_5_Diesel_Tx" SG_ 75 VedsPasKneeBag_D_Ltchd 1;
BA_ "U_B515_MCA_MY17_Gas_Tx" SG_ 75 VedsPasKneeBag_D_Ltchd 1;
BA_ "U_B515_MCA_MY17_Diesel_Tx" SG_ 75 VedsPasKneeBag_D_Ltchd 1;
BA_ "U_B479_MY17_Diesel_Tx" SG_ 75 VedsPasKneeBag_D_Ltchd 1;
BA_ "U_B479_MY17_Gas_Tx" SG_ 75 VedsPasKneeBag_D_Ltchd 1;
BA_ "GenSigSendType" SG_ 75 VedsPasKneeBag_D_Ltchd 3;
BA_ "GenSigTimeoutTime_GWM" SG_ 75 VedsRw3pRib_D_Ltchd 300;
BA_ "U_CX482_CX483_MY20_Hev_Tx" SG_ 75 VedsRw3pRib_D_Ltchd 1;
BA_ "U_CX482_CX483_MY20_Gas_Tx" SG_ 75 VedsRw3pRib_D_Ltchd 1;
BA_ "U_CX482_CX483_MY20_Diesel_Tx" SG_ 75 VedsRw3pRib_D_Ltchd 1;
BA_ "U_U611_U625_MY20_Hev_Tx" SG_ 75 VedsRw3pRib_D_Ltchd 1;
BA_ "U_U611_U625_MY20_Gas_Tx" SG_ 75 VedsRw3pRib_D_Ltchd 1;
BA_ "U_U611_U625_MY20_Diesel_Tx" SG_ 75 VedsRw3pRib_D_Ltchd 1;
BA_ "U_B500_MY18_Diesel_Tx" SG_ 75 VedsRw3pRib_D_Ltchd 1;
BA_ "U_B500_MY18_Gas_Tx" SG_ 75 VedsRw3pRib_D_Ltchd 1;
BA_ "U_C490_MY18_Tx" SG_ 75 VedsRw3pRib_D_Ltchd 1;
BA_ "U_B562_MY18_Gas_Tx" SG_ 75 VedsRw3pRib_D_Ltchd 1;
BA_ "U_C519_MY18_5_Gas_Tx" SG_ 75 VedsRw3pRib_D_Ltchd 1;
BA_ "U_C519_MY18_5_Diesel_Tx" SG_ 75 VedsRw3pRib_D_Ltchd 1;
BA_ "U_B515_MCA_MY17_Gas_Tx" SG_ 75 VedsRw3pRib_D_Ltchd 1;
BA_ "U_B515_MCA_MY17_Diesel_Tx" SG_ 75 VedsRw3pRib_D_Ltchd 1;
BA_ "GenSigSendType" SG_ 75 VedsRw3pRib_D_Ltchd 3;
BA_ "GenSigTimeoutTime_GWM" SG_ 75 VedsRw3dRib_D_Ltchd 300;
BA_ "U_CX482_CX483_MY20_Hev_Tx" SG_ 75 VedsRw3dRib_D_Ltchd 1;
BA_ "U_CX482_CX483_MY20_Gas_Tx" SG_ 75 VedsRw3dRib_D_Ltchd 1;
BA_ "U_CX482_CX483_MY20_Diesel_Tx" SG_ 75 VedsRw3dRib_D_Ltchd 1;
BA_ "U_U611_U625_MY20_Hev_Tx" SG_ 75 VedsRw3dRib_D_Ltchd 1;
BA_ "U_U611_U625_MY20_Gas_Tx" SG_ 75 VedsRw3dRib_D_Ltchd 1;
BA_ "U_U611_U625_MY20_Diesel_Tx" SG_ 75 VedsRw3dRib_D_Ltchd 1;
BA_ "U_B500_MY18_Diesel_Tx" SG_ 75 VedsRw3dRib_D_Ltchd 1;
BA_ "U_B500_MY18_Gas_Tx" SG_ 75 VedsRw3dRib_D_Ltchd 1;
BA_ "U_C490_MY18_Tx" SG_ 75 VedsRw3dRib_D_Ltchd 1;
BA_ "U_B562_MY18_Gas_Tx" SG_ 75 VedsRw3dRib_D_Ltchd 1;
BA_ "U_C519_MY18_5_Gas_Tx" SG_ 75 VedsRw3dRib_D_Ltchd 1;
BA_ "U_C519_MY18_5_Diesel_Tx" SG_ 75 VedsRw3dRib_D_Ltchd 1;
BA_ "U_B515_MCA_MY17_Gas_Tx" SG_ 75 VedsRw3dRib_D_Ltchd 1;
BA_ "U_B515_MCA_MY17_Diesel_Tx" SG_ 75 VedsRw3dRib_D_Ltchd 1;
BA_ "GenSigSendType" SG_ 75 VedsRw3dRib_D_Ltchd 3;
BA_ "GenSigTimeoutTime_GWM" SG_ 75 VedsRw1mBckl_D_Ltchd 300;
BA_ "U_CX482_CX483_MY20_Hev_Tx" SG_ 75 VedsRw1mBckl_D_Ltchd 1;
BA_ "U_CX482_CX483_MY20_Gas_Tx" SG_ 75 VedsRw1mBckl_D_Ltchd 1;
BA_ "U_CX482_CX483_MY20_Diesel_Tx" SG_ 75 VedsRw1mBckl_D_Ltchd 1;
BA_ "U_U611_U625_MY20_Hev_Tx" SG_ 75 VedsRw1mBckl_D_Ltchd 1;
BA_ "U_U611_U625_MY20_Gas_Tx" SG_ 75 VedsRw1mBckl_D_Ltchd 1;
BA_ "U_U611_U625_MY20_Diesel_Tx" SG_ 75 VedsRw1mBckl_D_Ltchd 1;
BA_ "U_B500_MY18_Diesel_Tx" SG_ 75 VedsRw1mBckl_D_Ltchd 1;
BA_ "U_B500_MY18_Gas_Tx" SG_ 75 VedsRw1mBckl_D_Ltchd 1;
BA_ "U_C490_MY18_Tx" SG_ 75 VedsRw1mBckl_D_Ltchd 1;
BA_ "U_B562_MY18_Gas_Tx" SG_ 75 VedsRw1mBckl_D_Ltchd 1;
BA_ "U_C519_MY18_5_Gas_Tx" SG_ 75 VedsRw1mBckl_D_Ltchd 1;
BA_ "U_C519_MY18_5_Diesel_Tx" SG_ 75 VedsRw1mBckl_D_Ltchd 1;
BA_ "U_B515_MCA_MY17_Gas_Tx" SG_ 75 VedsRw1mBckl_D_Ltchd 1;
BA_ "U_B515_MCA_MY17_Diesel_Tx" SG_ 75 VedsRw1mBckl_D_Ltchd 1;
BA_ "U_B479_MY17_Diesel_Tx" SG_ 75 VedsRw1mBckl_D_Ltchd 1;
BA_ "U_B479_MY17_Gas_Tx" SG_ 75 VedsRw1mBckl_D_Ltchd 1;
BA_ "GenSigSendType" SG_ 75 VedsRw1mBckl_D_Ltchd 3;
BA_ "GenSigTimeoutTime_GWM" SG_ 75 VedsRw1mBelt_D_Ltchd 300;
BA_ "U_CX482_CX483_MY20_Hev_Tx" SG_ 75 VedsRw1mBelt_D_Ltchd 1;
BA_ "U_CX482_CX483_MY20_Gas_Tx" SG_ 75 VedsRw1mBelt_D_Ltchd 1;
BA_ "U_CX482_CX483_MY20_Diesel_Tx" SG_ 75 VedsRw1mBelt_D_Ltchd 1;
BA_ "U_U611_U625_MY20_Hev_Tx" SG_ 75 VedsRw1mBelt_D_Ltchd 1;
BA_ "U_U611_U625_MY20_Gas_Tx" SG_ 75 VedsRw1mBelt_D_Ltchd 1;
BA_ "U_U611_U625_MY20_Diesel_Tx" SG_ 75 VedsRw1mBelt_D_Ltchd 1;
BA_ "U_B500_MY18_Diesel_Tx" SG_ 75 VedsRw1mBelt_D_Ltchd 1;
BA_ "U_B500_MY18_Gas_Tx" SG_ 75 VedsRw1mBelt_D_Ltchd 1;
BA_ "U_C490_MY18_Tx" SG_ 75 VedsRw1mBelt_D_Ltchd 1;
BA_ "U_B562_MY18_Gas_Tx" SG_ 75 VedsRw1mBelt_D_Ltchd 1;
BA_ "U_C519_MY18_5_Gas_Tx" SG_ 75 VedsRw1mBelt_D_Ltchd 1;
BA_ "U_C519_MY18_5_Diesel_Tx" SG_ 75 VedsRw1mBelt_D_Ltchd 1;
BA_ "U_B515_MCA_MY17_Gas_Tx" SG_ 75 VedsRw1mBelt_D_Ltchd 1;
BA_ "U_B515_MCA_MY17_Diesel_Tx" SG_ 75 VedsRw1mBelt_D_Ltchd 1;
BA_ "U_B479_MY17_Diesel_Tx" SG_ 75 VedsRw1mBelt_D_Ltchd 1;
BA_ "U_B479_MY17_Gas_Tx" SG_ 75 VedsRw1mBelt_D_Ltchd 1;
BA_ "GenSigSendType" SG_ 75 VedsRw1mBelt_D_Ltchd 3;
BA_ "GenSigTimeoutTime_GWM" SG_ 75 VedsRw2pRib_D_Ltchd 300;
BA_ "U_CX482_CX483_MY20_Hev_Tx" SG_ 75 VedsRw2pRib_D_Ltchd 1;
BA_ "U_CX482_CX483_MY20_Gas_Tx" SG_ 75 VedsRw2pRib_D_Ltchd 1;
BA_ "U_CX482_CX483_MY20_Diesel_Tx" SG_ 75 VedsRw2pRib_D_Ltchd 1;
BA_ "U_U611_U625_MY20_Hev_Tx" SG_ 75 VedsRw2pRib_D_Ltchd 1;
BA_ "U_U611_U625_MY20_Gas_Tx" SG_ 75 VedsRw2pRib_D_Ltchd 1;
BA_ "U_U611_U625_MY20_Diesel_Tx" SG_ 75 VedsRw2pRib_D_Ltchd 1;
BA_ "U_B500_MY18_Diesel_Tx" SG_ 75 VedsRw2pRib_D_Ltchd 1;
BA_ "U_B500_MY18_Gas_Tx" SG_ 75 VedsRw2pRib_D_Ltchd 1;
BA_ "U_C490_MY18_Tx" SG_ 75 VedsRw2pRib_D_Ltchd 1;
BA_ "U_B562_MY18_Gas_Tx" SG_ 75 VedsRw2pRib_D_Ltchd 1;
BA_ "U_C519_MY18_5_Gas_Tx" SG_ 75 VedsRw2pRib_D_Ltchd 1;
BA_ "U_C519_MY18_5_Diesel_Tx" SG_ 75 VedsRw2pRib_D_Ltchd 1;
BA_ "U_B515_MCA_MY17_Gas_Tx" SG_ 75 VedsRw2pRib_D_Ltchd 1;
BA_ "U_B515_MCA_MY17_Diesel_Tx" SG_ 75 VedsRw2pRib_D_Ltchd 1;
BA_ "U_B479_MY17_Diesel_Tx" SG_ 75 VedsRw2pRib_D_Ltchd 1;
BA_ "U_B479_MY17_Gas_Tx" SG_ 75 VedsRw2pRib_D_Ltchd 1;
BA_ "GenSigSendType" SG_ 75 VedsRw2pRib_D_Ltchd 3;
BA_ "GenSigTimeoutTime_GWM" SG_ 75 VedsRw2dRib_D_Ltchd 300;
BA_ "U_CX482_CX483_MY20_Hev_Tx" SG_ 75 VedsRw2dRib_D_Ltchd 1;
BA_ "U_CX482_CX483_MY20_Gas_Tx" SG_ 75 VedsRw2dRib_D_Ltchd 1;
BA_ "U_CX482_CX483_MY20_Diesel_Tx" SG_ 75 VedsRw2dRib_D_Ltchd 1;
BA_ "U_U611_U625_MY20_Hev_Tx" SG_ 75 VedsRw2dRib_D_Ltchd 1;
BA_ "U_U611_U625_MY20_Gas_Tx" SG_ 75 VedsRw2dRib_D_Ltchd 1;
BA_ "U_U611_U625_MY20_Diesel_Tx" SG_ 75 VedsRw2dRib_D_Ltchd 1;
BA_ "U_B500_MY18_Diesel_Tx" SG_ 75 VedsRw2dRib_D_Ltchd 1;
BA_ "U_B500_MY18_Gas_Tx" SG_ 75 VedsRw2dRib_D_Ltchd 1;
BA_ "U_C490_MY18_Tx" SG_ 75 VedsRw2dRib_D_Ltchd 1;
BA_ "U_B562_MY18_Gas_Tx" SG_ 75 VedsRw2dRib_D_Ltchd 1;
BA_ "U_C519_MY18_5_Gas_Tx" SG_ 75 VedsRw2dRib_D_Ltchd 1;
BA_ "U_C519_MY18_5_Diesel_Tx" SG_ 75 VedsRw2dRib_D_Ltchd 1;
BA_ "U_B515_MCA_MY17_Gas_Tx" SG_ 75 VedsRw2dRib_D_Ltchd 1;
BA_ "U_B515_MCA_MY17_Diesel_Tx" SG_ 75 VedsRw2dRib_D_Ltchd 1;
BA_ "U_B479_MY17_Diesel_Tx" SG_ 75 VedsRw2dRib_D_Ltchd 1;
BA_ "U_B479_MY17_Gas_Tx" SG_ 75 VedsRw2dRib_D_Ltchd 1;
BA_ "GenSigSendType" SG_ 75 VedsRw2dRib_D_Ltchd 3;
BA_ "GenSigTimeoutTime_GWM" SG_ 75 VedsRw3pBckl_D_Ltchd 300;
BA_ "U_CX482_CX483_MY20_Hev_Tx" SG_ 75 VedsRw3pBckl_D_Ltchd 1;
BA_ "U_CX482_CX483_MY20_Gas_Tx" SG_ 75 VedsRw3pBckl_D_Ltchd 1;
BA_ "U_CX482_CX483_MY20_Diesel_Tx" SG_ 75 VedsRw3pBckl_D_Ltchd 1;
BA_ "U_U611_U625_MY20_Hev_Tx" SG_ 75 VedsRw3pBckl_D_Ltchd 1;
BA_ "U_U611_U625_MY20_Gas_Tx" SG_ 75 VedsRw3pBckl_D_Ltchd 1;
BA_ "U_U611_U625_MY20_Diesel_Tx" SG_ 75 VedsRw3pBckl_D_Ltchd 1;
BA_ "U_B500_MY18_Diesel_Tx" SG_ 75 VedsRw3pBckl_D_Ltchd 1;
BA_ "U_B500_MY18_Gas_Tx" SG_ 75 VedsRw3pBckl_D_Ltchd 1;
BA_ "U_C490_MY18_Tx" SG_ 75 VedsRw3pBckl_D_Ltchd 1;
BA_ "U_B562_MY18_Gas_Tx" SG_ 75 VedsRw3pBckl_D_Ltchd 1;
BA_ "U_C519_MY18_5_Gas_Tx" SG_ 75 VedsRw3pBckl_D_Ltchd 1;
BA_ "U_C519_MY18_5_Diesel_Tx" SG_ 75 VedsRw3pBckl_D_Ltchd 1;
BA_ "U_B515_MCA_MY17_Gas_Tx" SG_ 75 VedsRw3pBckl_D_Ltchd 1;
BA_ "U_B515_MCA_MY17_Diesel_Tx" SG_ 75 VedsRw3pBckl_D_Ltchd 1;
BA_ "U_B479_MY17_Diesel_Tx" SG_ 75 VedsRw3pBckl_D_Ltchd 1;
BA_ "U_B479_MY17_Gas_Tx" SG_ 75 VedsRw3pBckl_D_Ltchd 1;
BA_ "GenSigSendType" SG_ 75 VedsRw3pBckl_D_Ltchd 3;
BA_ "GenSigTimeoutTime_GWM" SG_ 75 VedsRw3mBckl_D_Ltchd 300;
BA_ "U_CX482_CX483_MY20_Hev_Tx" SG_ 75 VedsRw3mBckl_D_Ltchd 1;
BA_ "U_CX482_CX483_MY20_Gas_Tx" SG_ 75 VedsRw3mBckl_D_Ltchd 1;
BA_ "U_CX482_CX483_MY20_Diesel_Tx" SG_ 75 VedsRw3mBckl_D_Ltchd 1;
BA_ "U_U611_U625_MY20_Hev_Tx" SG_ 75 VedsRw3mBckl_D_Ltchd 1;
BA_ "U_U611_U625_MY20_Gas_Tx" SG_ 75 VedsRw3mBckl_D_Ltchd 1;
BA_ "U_U611_U625_MY20_Diesel_Tx" SG_ 75 VedsRw3mBckl_D_Ltchd 1;
BA_ "U_B500_MY18_Diesel_Tx" SG_ 75 VedsRw3mBckl_D_Ltchd 1;
BA_ "U_B500_MY18_Gas_Tx" SG_ 75 VedsRw3mBckl_D_Ltchd 1;
BA_ "U_C490_MY18_Tx" SG_ 75 VedsRw3mBckl_D_Ltchd 1;
BA_ "U_B562_MY18_Gas_Tx" SG_ 75 VedsRw3mBckl_D_Ltchd 1;
BA_ "U_C519_MY18_5_Gas_Tx" SG_ 75 VedsRw3mBckl_D_Ltchd 1;
BA_ "U_C519_MY18_5_Diesel_Tx" SG_ 75 VedsRw3mBckl_D_Ltchd 1;
BA_ "U_B515_MCA_MY17_Gas_Tx" SG_ 75 VedsRw3mBckl_D_Ltchd 1;
BA_ "U_B515_MCA_MY17_Diesel_Tx" SG_ 75 VedsRw3mBckl_D_Ltchd 1;
BA_ "U_B479_MY17_Diesel_Tx" SG_ 75 VedsRw3mBckl_D_Ltchd 1;
BA_ "U_B479_MY17_Gas_Tx" SG_ 75 VedsRw3mBckl_D_Ltchd 1;
BA_ "GenSigSendType" SG_ 75 VedsRw3mBckl_D_Ltchd 3;
BA_ "GenSigTimeoutTime_GWM" SG_ 75 VedsRw3dBckl_D_Ltchd 300;
BA_ "U_CX482_CX483_MY20_Hev_Tx" SG_ 75 VedsRw3dBckl_D_Ltchd 1;
BA_ "U_CX482_CX483_MY20_Gas_Tx" SG_ 75 VedsRw3dBckl_D_Ltchd 1;
BA_ "U_CX482_CX483_MY20_Diesel_Tx" SG_ 75 VedsRw3dBckl_D_Ltchd 1;
BA_ "U_U611_U625_MY20_Hev_Tx" SG_ 75 VedsRw3dBckl_D_Ltchd 1;
BA_ "U_U611_U625_MY20_Gas_Tx" SG_ 75 VedsRw3dBckl_D_Ltchd 1;
BA_ "U_U611_U625_MY20_Diesel_Tx" SG_ 75 VedsRw3dBckl_D_Ltchd 1;
BA_ "U_B500_MY18_Diesel_Tx" SG_ 75 VedsRw3dBckl_D_Ltchd 1;
BA_ "U_B500_MY18_Gas_Tx" SG_ 75 VedsRw3dBckl_D_Ltchd 1;
BA_ "U_C490_MY18_Tx" SG_ 75 VedsRw3dBckl_D_Ltchd 1;
BA_ "U_B562_MY18_Gas_Tx" SG_ 75 VedsRw3dBckl_D_Ltchd 1;
BA_ "U_C519_MY18_5_Gas_Tx" SG_ 75 VedsRw3dBckl_D_Ltchd 1;
BA_ "U_C519_MY18_5_Diesel_Tx" SG_ 75 VedsRw3dBckl_D_Ltchd 1;
BA_ "U_B515_MCA_MY17_Gas_Tx" SG_ 75 VedsRw3dBckl_D_Ltchd 1;
BA_ "U_B515_MCA_MY17_Diesel_Tx" SG_ 75 VedsRw3dBckl_D_Ltchd 1;
BA_ "U_B479_MY17_Diesel_Tx" SG_ 75 VedsRw3dBckl_D_Ltchd 1;
BA_ "U_B479_MY17_Gas_Tx" SG_ 75 VedsRw3dBckl_D_Ltchd 1;
BA_ "GenSigSendType" SG_ 75 VedsRw3dBckl_D_Ltchd 3;
BA_ "GenSigTimeoutTime_GWM" SG_ 75 VedsRw2pBckl_D_Ltchd 300;
BA_ "U_CX482_CX483_MY20_Hev_Tx" SG_ 75 VedsRw2pBckl_D_Ltchd 1;
BA_ "U_CX482_CX483_MY20_Gas_Tx" SG_ 75 VedsRw2pBckl_D_Ltchd 1;
BA_ "U_CX482_CX483_MY20_Diesel_Tx" SG_ 75 VedsRw2pBckl_D_Ltchd 1;
BA_ "U_U611_U625_MY20_Hev_Tx" SG_ 75 VedsRw2pBckl_D_Ltchd 1;
BA_ "U_U611_U625_MY20_Gas_Tx" SG_ 75 VedsRw2pBckl_D_Ltchd 1;
BA_ "U_U611_U625_MY20_Diesel_Tx" SG_ 75 VedsRw2pBckl_D_Ltchd 1;
BA_ "U_B500_MY18_Diesel_Tx" SG_ 75 VedsRw2pBckl_D_Ltchd 1;
BA_ "U_B500_MY18_Gas_Tx" SG_ 75 VedsRw2pBckl_D_Ltchd 1;
BA_ "U_C490_MY18_Tx" SG_ 75 VedsRw2pBckl_D_Ltchd 1;
BA_ "U_B562_MY18_Gas_Tx" SG_ 75 VedsRw2pBckl_D_Ltchd 1;
BA_ "U_C519_MY18_5_Gas_Tx" SG_ 75 VedsRw2pBckl_D_Ltchd 1;
BA_ "U_C519_MY18_5_Diesel_Tx" SG_ 75 VedsRw2pBckl_D_Ltchd 1;
BA_ "U_B515_MCA_MY17_Gas_Tx" SG_ 75 VedsRw2pBckl_D_Ltchd 1;
BA_ "U_B515_MCA_MY17_Diesel_Tx" SG_ 75 VedsRw2pBckl_D_Ltchd 1;
BA_ "U_B479_MY17_Diesel_Tx" SG_ 75 VedsRw2pBckl_D_Ltchd 1;
BA_ "U_B479_MY17_Gas_Tx" SG_ 75 VedsRw2pBckl_D_Ltchd 1;
BA_ "GenSigSendType" SG_ 75 VedsRw2pBckl_D_Ltchd 3;
BA_ "GenSigTimeoutTime_GWM" SG_ 75 VedsRw2mBckl_D_Ltchd 300;
BA_ "U_CX482_CX483_MY20_Hev_Tx" SG_ 75 VedsRw2mBckl_D_Ltchd 1;
BA_ "U_CX482_CX483_MY20_Gas_Tx" SG_ 75 VedsRw2mBckl_D_Ltchd 1;
BA_ "U_CX482_CX483_MY20_Diesel_Tx" SG_ 75 VedsRw2mBckl_D_Ltchd 1;
BA_ "U_U611_U625_MY20_Hev_Tx" SG_ 75 VedsRw2mBckl_D_Ltchd 1;
BA_ "U_U611_U625_MY20_Gas_Tx" SG_ 75 VedsRw2mBckl_D_Ltchd 1;
BA_ "U_U611_U625_MY20_Diesel_Tx" SG_ 75 VedsRw2mBckl_D_Ltchd 1;
BA_ "U_B500_MY18_Diesel_Tx" SG_ 75 VedsRw2mBckl_D_Ltchd 1;
BA_ "U_B500_MY18_Gas_Tx" SG_ 75 VedsRw2mBckl_D_Ltchd 1;
BA_ "U_C490_MY18_Tx" SG_ 75 VedsRw2mBckl_D_Ltchd 1;
BA_ "U_B562_MY18_Gas_Tx" SG_ 75 VedsRw2mBckl_D_Ltchd 1;
BA_ "U_C519_MY18_5_Gas_Tx" SG_ 75 VedsRw2mBckl_D_Ltchd 1;
BA_ "U_C519_MY18_5_Diesel_Tx" SG_ 75 VedsRw2mBckl_D_Ltchd 1;
BA_ "U_B515_MCA_MY17_Gas_Tx" SG_ 75 VedsRw2mBckl_D_Ltchd 1;
BA_ "U_B515_MCA_MY17_Diesel_Tx" SG_ 75 VedsRw2mBckl_D_Ltchd 1;
BA_ "U_B479_MY17_Diesel_Tx" SG_ 75 VedsRw2mBckl_D_Ltchd 1;
BA_ "U_B479_MY17_Gas_Tx" SG_ 75 VedsRw2mBckl_D_Ltchd 1;
BA_ "GenSigSendType" SG_ 75 VedsRw2mBckl_D_Ltchd 3;
BA_ "GenSigTimeoutTime_GWM" SG_ 75 VedsRw2dBckl_D_Ltchd 300;
BA_ "U_CX482_CX483_MY20_Hev_Tx" SG_ 75 VedsRw2dBckl_D_Ltchd 1;
BA_ "U_CX482_CX483_MY20_Gas_Tx" SG_ 75 VedsRw2dBckl_D_Ltchd 1;
BA_ "U_CX482_CX483_MY20_Diesel_Tx" SG_ 75 VedsRw2dBckl_D_Ltchd 1;
BA_ "U_U611_U625_MY20_Hev_Tx" SG_ 75 VedsRw2dBckl_D_Ltchd 1;
BA_ "U_U611_U625_MY20_Gas_Tx" SG_ 75 VedsRw2dBckl_D_Ltchd 1;
BA_ "U_U611_U625_MY20_Diesel_Tx" SG_ 75 VedsRw2dBckl_D_Ltchd 1;
BA_ "U_B500_MY18_Diesel_Tx" SG_ 75 VedsRw2dBckl_D_Ltchd 1;
BA_ "U_B500_MY18_Gas_Tx" SG_ 75 VedsRw2dBckl_D_Ltchd 1;
BA_ "U_C490_MY18_Tx" SG_ 75 VedsRw2dBckl_D_Ltchd 1;
BA_ "U_B562_MY18_Gas_Tx" SG_ 75 VedsRw2dBckl_D_Ltchd 1;
BA_ "U_C519_MY18_5_Gas_Tx" SG_ 75 VedsRw2dBckl_D_Ltchd 1;
BA_ "U_C519_MY18_5_Diesel_Tx" SG_ 75 VedsRw2dBckl_D_Ltchd 1;
BA_ "U_B515_MCA_MY17_Gas_Tx" SG_ 75 VedsRw2dBckl_D_Ltchd 1;
BA_ "U_B515_MCA_MY17_Diesel_Tx" SG_ 75 VedsRw2dBckl_D_Ltchd 1;
BA_ "U_B479_MY17_Diesel_Tx" SG_ 75 VedsRw2dBckl_D_Ltchd 1;
BA_ "U_B479_MY17_Gas_Tx" SG_ 75 VedsRw2dBckl_D_Ltchd 1;
BA_ "GenSigSendType" SG_ 75 VedsRw2dBckl_D_Ltchd 3;
BA_ "GenSigTimeoutTime_GWM" SG_ 75 VedsRw1PasChld_D_Ltchd 300;
BA_ "U_CX482_CX483_MY20_Hev_Tx" SG_ 75 VedsRw1PasChld_D_Ltchd 1;
BA_ "U_CX482_CX483_MY20_Gas_Tx" SG_ 75 VedsRw1PasChld_D_Ltchd 1;
BA_ "U_CX482_CX483_MY20_Diesel_Tx" SG_ 75 VedsRw1PasChld_D_Ltchd 1;
BA_ "U_U611_U625_MY20_Hev_Tx" SG_ 75 VedsRw1PasChld_D_Ltchd 1;
BA_ "U_U611_U625_MY20_Gas_Tx" SG_ 75 VedsRw1PasChld_D_Ltchd 1;
BA_ "U_U611_U625_MY20_Diesel_Tx" SG_ 75 VedsRw1PasChld_D_Ltchd 1;
BA_ "U_B500_MY18_Diesel_Tx" SG_ 75 VedsRw1PasChld_D_Ltchd 1;
BA_ "U_B500_MY18_Gas_Tx" SG_ 75 VedsRw1PasChld_D_Ltchd 1;
BA_ "U_C490_MY18_Tx" SG_ 75 VedsRw1PasChld_D_Ltchd 1;
BA_ "U_B562_MY18_Gas_Tx" SG_ 75 VedsRw1PasChld_D_Ltchd 1;
BA_ "U_C519_MY18_5_Gas_Tx" SG_ 75 VedsRw1PasChld_D_Ltchd 1;
BA_ "U_C519_MY18_5_Diesel_Tx" SG_ 75 VedsRw1PasChld_D_Ltchd 1;
BA_ "U_B515_MCA_MY17_Gas_Tx" SG_ 75 VedsRw1PasChld_D_Ltchd 1;
BA_ "U_B515_MCA_MY17_Diesel_Tx" SG_ 75 VedsRw1PasChld_D_Ltchd 1;
BA_ "U_B479_MY17_Diesel_Tx" SG_ 75 VedsRw1PasChld_D_Ltchd 1;
BA_ "U_B479_MY17_Gas_Tx" SG_ 75 VedsRw1PasChld_D_Ltchd 1;
BA_ "GenSigSendType" SG_ 75 VedsRw1PasChld_D_Ltchd 3;
BA_ "GenSigTimeoutTime_GWM" SG_ 75 VedsRw1PasBckl_D_Ltchd 300;
BA_ "U_CX482_CX483_MY20_Hev_Tx" SG_ 75 VedsRw1PasBckl_D_Ltchd 1;
BA_ "U_CX482_CX483_MY20_Gas_Tx" SG_ 75 VedsRw1PasBckl_D_Ltchd 1;
BA_ "U_CX482_CX483_MY20_Diesel_Tx" SG_ 75 VedsRw1PasBckl_D_Ltchd 1;
BA_ "U_U611_U625_MY20_Hev_Tx" SG_ 75 VedsRw1PasBckl_D_Ltchd 1;
BA_ "U_U611_U625_MY20_Gas_Tx" SG_ 75 VedsRw1PasBckl_D_Ltchd 1;
BA_ "U_U611_U625_MY20_Diesel_Tx" SG_ 75 VedsRw1PasBckl_D_Ltchd 1;
BA_ "U_B500_MY18_Diesel_Tx" SG_ 75 VedsRw1PasBckl_D_Ltchd 1;
BA_ "U_B500_MY18_Gas_Tx" SG_ 75 VedsRw1PasBckl_D_Ltchd 1;
BA_ "U_C490_MY18_Tx" SG_ 75 VedsRw1PasBckl_D_Ltchd 1;
BA_ "U_B562_MY18_Gas_Tx" SG_ 75 VedsRw1PasBckl_D_Ltchd 1;
BA_ "U_C519_MY18_5_Gas_Tx" SG_ 75 VedsRw1PasBckl_D_Ltchd 1;
BA_ "U_C519_MY18_5_Diesel_Tx" SG_ 75 VedsRw1PasBckl_D_Ltchd 1;
BA_ "U_B515_MCA_MY17_Gas_Tx" SG_ 75 VedsRw1PasBckl_D_Ltchd 1;
BA_ "U_B515_MCA_MY17_Diesel_Tx" SG_ 75 VedsRw1PasBckl_D_Ltchd 1;
BA_ "U_B479_MY17_Diesel_Tx" SG_ 75 VedsRw1PasBckl_D_Ltchd 1;
BA_ "U_B479_MY17_Gas_Tx" SG_ 75 VedsRw1PasBckl_D_Ltchd 1;
BA_ "GenSigSendType" SG_ 75 VedsRw1PasBckl_D_Ltchd 3;
BA_ "GenSigTimeoutTime_GWM" SG_ 75 VedsRw1DrvBckl_D_Ltchd 300;
BA_ "U_CX482_CX483_MY20_Hev_Tx" SG_ 75 VedsRw1DrvBckl_D_Ltchd 1;
BA_ "U_CX482_CX483_MY20_Gas_Tx" SG_ 75 VedsRw1DrvBckl_D_Ltchd 1;
BA_ "U_CX482_CX483_MY20_Diesel_Tx" SG_ 75 VedsRw1DrvBckl_D_Ltchd 1;
BA_ "U_U611_U625_MY20_Hev_Tx" SG_ 75 VedsRw1DrvBckl_D_Ltchd 1;
BA_ "U_U611_U625_MY20_Gas_Tx" SG_ 75 VedsRw1DrvBckl_D_Ltchd 1;
BA_ "U_U611_U625_MY20_Diesel_Tx" SG_ 75 VedsRw1DrvBckl_D_Ltchd 1;
BA_ "U_B500_MY18_Diesel_Tx" SG_ 75 VedsRw1DrvBckl_D_Ltchd 1;
BA_ "U_B500_MY18_Gas_Tx" SG_ 75 VedsRw1DrvBckl_D_Ltchd 1;
BA_ "U_C490_MY18_Tx" SG_ 75 VedsRw1DrvBckl_D_Ltchd 1;
BA_ "U_B562_MY18_Gas_Tx" SG_ 75 VedsRw1DrvBckl_D_Ltchd 1;
BA_ "U_C519_MY18_5_Gas_Tx" SG_ 75 VedsRw1DrvBckl_D_Ltchd 1;
BA_ "U_C519_MY18_5_Diesel_Tx" SG_ 75 VedsRw1DrvBckl_D_Ltchd 1;
BA_ "U_B515_MCA_MY17_Gas_Tx" SG_ 75 VedsRw1DrvBckl_D_Ltchd 1;
BA_ "U_B515_MCA_MY17_Diesel_Tx" SG_ 75 VedsRw1DrvBckl_D_Ltchd 1;
BA_ "U_B479_MY17_Diesel_Tx" SG_ 75 VedsRw1DrvBckl_D_Ltchd 1;
BA_ "U_B479_MY17_Gas_Tx" SG_ 75 VedsRw1DrvBckl_D_Ltchd 1;
BA_ "GenSigSendType" SG_ 75 VedsRw1DrvBckl_D_Ltchd 3;
BA_ "GenSigTimeoutTime_GWM" SG_ 74 VedsPasSideBag_D_Ltchd 300;
BA_ "U_CX482_CX483_MY20_Hev_Tx" SG_ 74 VedsPasSideBag_D_Ltchd 1;
BA_ "U_CX482_CX483_MY20_Gas_Tx" SG_ 74 VedsPasSideBag_D_Ltchd 1;
BA_ "U_CX482_CX483_MY20_Diesel_Tx" SG_ 74 VedsPasSideBag_D_Ltchd 1;
BA_ "U_U611_U625_MY20_Hev_Tx" SG_ 74 VedsPasSideBag_D_Ltchd 1;
BA_ "U_U611_U625_MY20_Gas_Tx" SG_ 74 VedsPasSideBag_D_Ltchd 1;
BA_ "U_U611_U625_MY20_Diesel_Tx" SG_ 74 VedsPasSideBag_D_Ltchd 1;
BA_ "U_B500_MY18_Diesel_Tx" SG_ 74 VedsPasSideBag_D_Ltchd 1;
BA_ "U_B500_MY18_Gas_Tx" SG_ 74 VedsPasSideBag_D_Ltchd 1;
BA_ "U_C490_MY18_Tx" SG_ 74 VedsPasSideBag_D_Ltchd 1;
BA_ "U_B562_MY18_Gas_Tx" SG_ 74 VedsPasSideBag_D_Ltchd 1;
BA_ "U_C519_MY18_5_Gas_Tx" SG_ 74 VedsPasSideBag_D_Ltchd 1;
BA_ "U_C519_MY18_5_Diesel_Tx" SG_ 74 VedsPasSideBag_D_Ltchd 1;
BA_ "U_B515_MCA_MY17_Gas_Tx" SG_ 74 VedsPasSideBag_D_Ltchd 1;
BA_ "U_B515_MCA_MY17_Diesel_Tx" SG_ 74 VedsPasSideBag_D_Ltchd 1;
BA_ "U_B479_MY17_Diesel_Tx" SG_ 74 VedsPasSideBag_D_Ltchd 1;
BA_ "U_B479_MY17_Gas_Tx" SG_ 74 VedsPasSideBag_D_Ltchd 1;
BA_ "GenSigSendType" SG_ 74 VedsPasSideBag_D_Ltchd 3;
BA_ "GenSigTimeoutTime_GWM" SG_ 74 VedsPasCrtnBag_D_Ltchd 300;
BA_ "U_CX482_CX483_MY20_Hev_Tx" SG_ 74 VedsPasCrtnBag_D_Ltchd 1;
BA_ "U_CX482_CX483_MY20_Gas_Tx" SG_ 74 VedsPasCrtnBag_D_Ltchd 1;
BA_ "U_CX482_CX483_MY20_Diesel_Tx" SG_ 74 VedsPasCrtnBag_D_Ltchd 1;
BA_ "U_U611_U625_MY20_Hev_Tx" SG_ 74 VedsPasCrtnBag_D_Ltchd 1;
BA_ "U_U611_U625_MY20_Gas_Tx" SG_ 74 VedsPasCrtnBag_D_Ltchd 1;
BA_ "U_U611_U625_MY20_Diesel_Tx" SG_ 74 VedsPasCrtnBag_D_Ltchd 1;
BA_ "U_B500_MY18_Diesel_Tx" SG_ 74 VedsPasCrtnBag_D_Ltchd 1;
BA_ "U_B500_MY18_Gas_Tx" SG_ 74 VedsPasCrtnBag_D_Ltchd 1;
BA_ "U_C490_MY18_Tx" SG_ 74 VedsPasCrtnBag_D_Ltchd 1;
BA_ "U_B562_MY18_Gas_Tx" SG_ 74 VedsPasCrtnBag_D_Ltchd 1;
BA_ "U_C519_MY18_5_Gas_Tx" SG_ 74 VedsPasCrtnBag_D_Ltchd 1;
BA_ "U_C519_MY18_5_Diesel_Tx" SG_ 74 VedsPasCrtnBag_D_Ltchd 1;
BA_ "U_B515_MCA_MY17_Gas_Tx" SG_ 74 VedsPasCrtnBag_D_Ltchd 1;
BA_ "U_B515_MCA_MY17_Diesel_Tx" SG_ 74 VedsPasCrtnBag_D_Ltchd 1;
BA_ "U_B479_MY17_Diesel_Tx" SG_ 74 VedsPasCrtnBag_D_Ltchd 1;
BA_ "U_B479_MY17_Gas_Tx" SG_ 74 VedsPasCrtnBag_D_Ltchd 1;
BA_ "GenSigSendType" SG_ 74 VedsPasCrtnBag_D_Ltchd 3;
BA_ "GenSigTimeoutTime_GWM" SG_ 74 VedsPasBelt_D_Ltchd 300;
BA_ "U_CX482_CX483_MY20_Hev_Tx" SG_ 74 VedsPasBelt_D_Ltchd 1;
BA_ "U_CX482_CX483_MY20_Gas_Tx" SG_ 74 VedsPasBelt_D_Ltchd 1;
BA_ "U_CX482_CX483_MY20_Diesel_Tx" SG_ 74 VedsPasBelt_D_Ltchd 1;
BA_ "U_U611_U625_MY20_Hev_Tx" SG_ 74 VedsPasBelt_D_Ltchd 1;
BA_ "U_U611_U625_MY20_Gas_Tx" SG_ 74 VedsPasBelt_D_Ltchd 1;
BA_ "U_U611_U625_MY20_Diesel_Tx" SG_ 74 VedsPasBelt_D_Ltchd 1;
BA_ "U_B500_MY18_Diesel_Tx" SG_ 74 VedsPasBelt_D_Ltchd 1;
BA_ "U_B500_MY18_Gas_Tx" SG_ 74 VedsPasBelt_D_Ltchd 1;
BA_ "U_C490_MY18_Tx" SG_ 74 VedsPasBelt_D_Ltchd 1;
BA_ "U_B562_MY18_Gas_Tx" SG_ 74 VedsPasBelt_D_Ltchd 1;
BA_ "U_C519_MY18_5_Gas_Tx" SG_ 74 VedsPasBelt_D_Ltchd 1;
BA_ "U_C519_MY18_5_Diesel_Tx" SG_ 74 VedsPasBelt_D_Ltchd 1;
BA_ "U_B515_MCA_MY17_Gas_Tx" SG_ 74 VedsPasBelt_D_Ltchd 1;
BA_ "U_B515_MCA_MY17_Diesel_Tx" SG_ 74 VedsPasBelt_D_Ltchd 1;
BA_ "U_B479_MY17_Diesel_Tx" SG_ 74 VedsPasBelt_D_Ltchd 1;
BA_ "U_B479_MY17_Gas_Tx" SG_ 74 VedsPasBelt_D_Ltchd 1;
BA_ "GenSigSendType" SG_ 74 VedsPasBelt_D_Ltchd 3;
BA_ "GenSigTimeoutTime_GWM" SG_ 74 VedsPasBag_D_Ltchd 300;
BA_ "U_CX482_CX483_MY20_Hev_Tx" SG_ 74 VedsPasBag_D_Ltchd 1;
BA_ "U_CX482_CX483_MY20_Gas_Tx" SG_ 74 VedsPasBag_D_Ltchd 1;
BA_ "U_CX482_CX483_MY20_Diesel_Tx" SG_ 74 VedsPasBag_D_Ltchd 1;
BA_ "U_U611_U625_MY20_Hev_Tx" SG_ 74 VedsPasBag_D_Ltchd 1;
BA_ "U_U611_U625_MY20_Gas_Tx" SG_ 74 VedsPasBag_D_Ltchd 1;
BA_ "U_U611_U625_MY20_Diesel_Tx" SG_ 74 VedsPasBag_D_Ltchd 1;
BA_ "U_B500_MY18_Diesel_Tx" SG_ 74 VedsPasBag_D_Ltchd 1;
BA_ "U_B500_MY18_Gas_Tx" SG_ 74 VedsPasBag_D_Ltchd 1;
BA_ "U_C490_MY18_Tx" SG_ 74 VedsPasBag_D_Ltchd 1;
BA_ "U_B562_MY18_Gas_Tx" SG_ 74 VedsPasBag_D_Ltchd 1;
BA_ "U_C519_MY18_5_Gas_Tx" SG_ 74 VedsPasBag_D_Ltchd 1;
BA_ "U_C519_MY18_5_Diesel_Tx" SG_ 74 VedsPasBag_D_Ltchd 1;
BA_ "U_B515_MCA_MY17_Gas_Tx" SG_ 74 VedsPasBag_D_Ltchd 1;
BA_ "U_B515_MCA_MY17_Diesel_Tx" SG_ 74 VedsPasBag_D_Ltchd 1;
BA_ "U_B479_MY17_Diesel_Tx" SG_ 74 VedsPasBag_D_Ltchd 1;
BA_ "U_B479_MY17_Gas_Tx" SG_ 74 VedsPasBag_D_Ltchd 1;
BA_ "GenSigSendType" SG_ 74 VedsPasBag_D_Ltchd 3;
BA_ "GenSigTimeoutTime_GWM" SG_ 74 VedsMultiEvnt_D_Ltchd 300;
BA_ "U_CX482_CX483_MY20_Hev_Tx" SG_ 74 VedsMultiEvnt_D_Ltchd 1;
BA_ "U_CX482_CX483_MY20_Gas_Tx" SG_ 74 VedsMultiEvnt_D_Ltchd 1;
BA_ "U_CX482_CX483_MY20_Diesel_Tx" SG_ 74 VedsMultiEvnt_D_Ltchd 1;
BA_ "U_U611_U625_MY20_Hev_Tx" SG_ 74 VedsMultiEvnt_D_Ltchd 1;
BA_ "U_U611_U625_MY20_Gas_Tx" SG_ 74 VedsMultiEvnt_D_Ltchd 1;
BA_ "U_U611_U625_MY20_Diesel_Tx" SG_ 74 VedsMultiEvnt_D_Ltchd 1;
BA_ "U_B500_MY18_Diesel_Tx" SG_ 74 VedsMultiEvnt_D_Ltchd 1;
BA_ "U_B500_MY18_Gas_Tx" SG_ 74 VedsMultiEvnt_D_Ltchd 1;
BA_ "U_C490_MY18_Tx" SG_ 74 VedsMultiEvnt_D_Ltchd 1;
BA_ "U_B562_MY18_Gas_Tx" SG_ 74 VedsMultiEvnt_D_Ltchd 1;
BA_ "U_C519_MY18_5_Gas_Tx" SG_ 74 VedsMultiEvnt_D_Ltchd 1;
BA_ "U_C519_MY18_5_Diesel_Tx" SG_ 74 VedsMultiEvnt_D_Ltchd 1;
BA_ "U_B515_MCA_MY17_Gas_Tx" SG_ 74 VedsMultiEvnt_D_Ltchd 1;
BA_ "U_B515_MCA_MY17_Diesel_Tx" SG_ 74 VedsMultiEvnt_D_Ltchd 1;
BA_ "U_B479_MY17_Diesel_Tx" SG_ 74 VedsMultiEvnt_D_Ltchd 1;
BA_ "U_B479_MY17_Gas_Tx" SG_ 74 VedsMultiEvnt_D_Ltchd 1;
BA_ "GenSigSendType" SG_ 74 VedsMultiEvnt_D_Ltchd 3;
BA_ "GenSigTimeoutTime_GWM" SG_ 74 VedsMaxDeltaV_D_Ltchd 300;
BA_ "U_CX482_CX483_MY20_Hev_Tx" SG_ 74 VedsMaxDeltaV_D_Ltchd 1;
BA_ "U_CX482_CX483_MY20_Gas_Tx" SG_ 74 VedsMaxDeltaV_D_Ltchd 1;
BA_ "U_CX482_CX483_MY20_Diesel_Tx" SG_ 74 VedsMaxDeltaV_D_Ltchd 1;
BA_ "U_U611_U625_MY20_Hev_Tx" SG_ 74 VedsMaxDeltaV_D_Ltchd 1;
BA_ "U_U611_U625_MY20_Gas_Tx" SG_ 74 VedsMaxDeltaV_D_Ltchd 1;
BA_ "U_U611_U625_MY20_Diesel_Tx" SG_ 74 VedsMaxDeltaV_D_Ltchd 1;
BA_ "U_B500_MY18_Diesel_Tx" SG_ 74 VedsMaxDeltaV_D_Ltchd 1;
BA_ "U_B500_MY18_Gas_Tx" SG_ 74 VedsMaxDeltaV_D_Ltchd 1;
BA_ "U_C490_MY18_Tx" SG_ 74 VedsMaxDeltaV_D_Ltchd 1;
BA_ "U_B562_MY18_Gas_Tx" SG_ 74 VedsMaxDeltaV_D_Ltchd 1;
BA_ "U_C519_MY18_5_Gas_Tx" SG_ 74 VedsMaxDeltaV_D_Ltchd 1;
BA_ "U_C519_MY18_5_Diesel_Tx" SG_ 74 VedsMaxDeltaV_D_Ltchd 1;
BA_ "U_B515_MCA_MY17_Gas_Tx" SG_ 74 VedsMaxDeltaV_D_Ltchd 1;
BA_ "U_B515_MCA_MY17_Diesel_Tx" SG_ 74 VedsMaxDeltaV_D_Ltchd 1;
BA_ "U_B479_MY17_Diesel_Tx" SG_ 74 VedsMaxDeltaV_D_Ltchd 1;
BA_ "U_B479_MY17_Gas_Tx" SG_ 74 VedsMaxDeltaV_D_Ltchd 1;
BA_ "GenSigSendType" SG_ 74 VedsMaxDeltaV_D_Ltchd 3;
BA_ "GenSigTimeoutTime_GWM" SG_ 74 VedsDrvKneeBag_D_Ltchd 300;
BA_ "U_CX482_CX483_MY20_Hev_Tx" SG_ 74 VedsDrvKneeBag_D_Ltchd 1;
BA_ "U_CX482_CX483_MY20_Gas_Tx" SG_ 74 VedsDrvKneeBag_D_Ltchd 1;
BA_ "U_CX482_CX483_MY20_Diesel_Tx" SG_ 74 VedsDrvKneeBag_D_Ltchd 1;
BA_ "U_U611_U625_MY20_Hev_Tx" SG_ 74 VedsDrvKneeBag_D_Ltchd 1;
BA_ "U_U611_U625_MY20_Gas_Tx" SG_ 74 VedsDrvKneeBag_D_Ltchd 1;
BA_ "U_U611_U625_MY20_Diesel_Tx" SG_ 74 VedsDrvKneeBag_D_Ltchd 1;
BA_ "U_B500_MY18_Diesel_Tx" SG_ 74 VedsDrvKneeBag_D_Ltchd 1;
BA_ "U_B500_MY18_Gas_Tx" SG_ 74 VedsDrvKneeBag_D_Ltchd 1;
BA_ "U_C490_MY18_Tx" SG_ 74 VedsDrvKneeBag_D_Ltchd 1;
BA_ "U_B562_MY18_Gas_Tx" SG_ 74 VedsDrvKneeBag_D_Ltchd 1;
BA_ "U_C519_MY18_5_Gas_Tx" SG_ 74 VedsDrvKneeBag_D_Ltchd 1;
BA_ "U_C519_MY18_5_Diesel_Tx" SG_ 74 VedsDrvKneeBag_D_Ltchd 1;
BA_ "U_B515_MCA_MY17_Gas_Tx" SG_ 74 VedsDrvKneeBag_D_Ltchd 1;
BA_ "U_B515_MCA_MY17_Diesel_Tx" SG_ 74 VedsDrvKneeBag_D_Ltchd 1;
BA_ "U_B479_MY17_Diesel_Tx" SG_ 74 VedsDrvKneeBag_D_Ltchd 1;
BA_ "U_B479_MY17_Gas_Tx" SG_ 74 VedsDrvKneeBag_D_Ltchd 1;
BA_ "GenSigSendType" SG_ 74 VedsDrvKneeBag_D_Ltchd 3;
BA_ "GenSigTimeoutTime_GWM" SG_ 74 VedsEvntType_D_Ltchd 300;
BA_ "U_CX482_CX483_MY20_Hev_Tx" SG_ 74 VedsEvntType_D_Ltchd 1;
BA_ "U_CX482_CX483_MY20_Gas_Tx" SG_ 74 VedsEvntType_D_Ltchd 1;
BA_ "U_CX482_CX483_MY20_Diesel_Tx" SG_ 74 VedsEvntType_D_Ltchd 1;
BA_ "U_U611_U625_MY20_Hev_Tx" SG_ 74 VedsEvntType_D_Ltchd 1;
BA_ "U_U611_U625_MY20_Gas_Tx" SG_ 74 VedsEvntType_D_Ltchd 1;
BA_ "U_U611_U625_MY20_Diesel_Tx" SG_ 74 VedsEvntType_D_Ltchd 1;
BA_ "U_B500_MY18_Diesel_Tx" SG_ 74 VedsEvntType_D_Ltchd 1;
BA_ "U_B500_MY18_Gas_Tx" SG_ 74 VedsEvntType_D_Ltchd 1;
BA_ "U_C490_MY18_Tx" SG_ 74 VedsEvntType_D_Ltchd 1;
BA_ "U_B562_MY18_Gas_Tx" SG_ 74 VedsEvntType_D_Ltchd 1;
BA_ "U_C519_MY18_5_Gas_Tx" SG_ 74 VedsEvntType_D_Ltchd 1;
BA_ "U_C519_MY18_5_Diesel_Tx" SG_ 74 VedsEvntType_D_Ltchd 1;
BA_ "U_B515_MCA_MY17_Gas_Tx" SG_ 74 VedsEvntType_D_Ltchd 1;
BA_ "U_B515_MCA_MY17_Diesel_Tx" SG_ 74 VedsEvntType_D_Ltchd 1;
BA_ "U_B479_MY17_Diesel_Tx" SG_ 74 VedsEvntType_D_Ltchd 1;
BA_ "U_B479_MY17_Gas_Tx" SG_ 74 VedsEvntType_D_Ltchd 1;
BA_ "GenSigSendType" SG_ 74 VedsEvntType_D_Ltchd 3;
BA_ "GenSigTimeoutTime_GWM" SG_ 74 VedsEvntRoll_D_Ltchd 300;
BA_ "U_CX482_CX483_MY20_Hev_Tx" SG_ 74 VedsEvntRoll_D_Ltchd 1;
BA_ "U_CX482_CX483_MY20_Gas_Tx" SG_ 74 VedsEvntRoll_D_Ltchd 1;
BA_ "U_CX482_CX483_MY20_Diesel_Tx" SG_ 74 VedsEvntRoll_D_Ltchd 1;
BA_ "U_U611_U625_MY20_Hev_Tx" SG_ 74 VedsEvntRoll_D_Ltchd 1;
BA_ "U_U611_U625_MY20_Gas_Tx" SG_ 74 VedsEvntRoll_D_Ltchd 1;
BA_ "U_U611_U625_MY20_Diesel_Tx" SG_ 74 VedsEvntRoll_D_Ltchd 1;
BA_ "U_B500_MY18_Diesel_Tx" SG_ 74 VedsEvntRoll_D_Ltchd 1;
BA_ "U_B500_MY18_Gas_Tx" SG_ 74 VedsEvntRoll_D_Ltchd 1;
BA_ "U_C490_MY18_Tx" SG_ 74 VedsEvntRoll_D_Ltchd 1;
BA_ "U_B562_MY18_Gas_Tx" SG_ 74 VedsEvntRoll_D_Ltchd 1;
BA_ "U_C519_MY18_5_Gas_Tx" SG_ 74 VedsEvntRoll_D_Ltchd 1;
BA_ "U_C519_MY18_5_Diesel_Tx" SG_ 74 VedsEvntRoll_D_Ltchd 1;
BA_ "U_B515_MCA_MY17_Gas_Tx" SG_ 74 VedsEvntRoll_D_Ltchd 1;
BA_ "U_B515_MCA_MY17_Diesel_Tx" SG_ 74 VedsEvntRoll_D_Ltchd 1;
BA_ "U_B479_MY17_Diesel_Tx" SG_ 74 VedsEvntRoll_D_Ltchd 1;
BA_ "U_B479_MY17_Gas_Tx" SG_ 74 VedsEvntRoll_D_Ltchd 1;
BA_ "GenSigSendType" SG_ 74 VedsEvntRoll_D_Ltchd 3;
BA_ "GenSigTimeoutTime_GWM" SG_ 74 VedsDrvSideBag_D_Ltchd 300;
BA_ "U_CX482_CX483_MY20_Hev_Tx" SG_ 74 VedsDrvSideBag_D_Ltchd 1;
BA_ "U_CX482_CX483_MY20_Gas_Tx" SG_ 74 VedsDrvSideBag_D_Ltchd 1;
BA_ "U_CX482_CX483_MY20_Diesel_Tx" SG_ 74 VedsDrvSideBag_D_Ltchd 1;
BA_ "U_U611_U625_MY20_Hev_Tx" SG_ 74 VedsDrvSideBag_D_Ltchd 1;
BA_ "U_U611_U625_MY20_Gas_Tx" SG_ 74 VedsDrvSideBag_D_Ltchd 1;
BA_ "U_U611_U625_MY20_Diesel_Tx" SG_ 74 VedsDrvSideBag_D_Ltchd 1;
BA_ "U_B500_MY18_Diesel_Tx" SG_ 74 VedsDrvSideBag_D_Ltchd 1;
BA_ "U_B500_MY18_Gas_Tx" SG_ 74 VedsDrvSideBag_D_Ltchd 1;
BA_ "U_C490_MY18_Tx" SG_ 74 VedsDrvSideBag_D_Ltchd 1;
BA_ "U_B562_MY18_Gas_Tx" SG_ 74 VedsDrvSideBag_D_Ltchd 1;
BA_ "U_C519_MY18_5_Gas_Tx" SG_ 74 VedsDrvSideBag_D_Ltchd 1;
BA_ "U_C519_MY18_5_Diesel_Tx" SG_ 74 VedsDrvSideBag_D_Ltchd 1;
BA_ "U_B515_MCA_MY17_Gas_Tx" SG_ 74 VedsDrvSideBag_D_Ltchd 1;
BA_ "U_B515_MCA_MY17_Diesel_Tx" SG_ 74 VedsDrvSideBag_D_Ltchd 1;
BA_ "U_B479_MY17_Diesel_Tx" SG_ 74 VedsDrvSideBag_D_Ltchd 1;
BA_ "U_B479_MY17_Gas_Tx" SG_ 74 VedsDrvSideBag_D_Ltchd 1;
BA_ "GenSigSendType" SG_ 74 VedsDrvSideBag_D_Ltchd 3;
BA_ "GenSigTimeoutTime_GWM" SG_ 74 VedsDrvCrtnBag_D_Ltchd 300;
BA_ "U_CX482_CX483_MY20_Hev_Tx" SG_ 74 VedsDrvCrtnBag_D_Ltchd 1;
BA_ "U_CX482_CX483_MY20_Gas_Tx" SG_ 74 VedsDrvCrtnBag_D_Ltchd 1;
BA_ "U_CX482_CX483_MY20_Diesel_Tx" SG_ 74 VedsDrvCrtnBag_D_Ltchd 1;
BA_ "U_U611_U625_MY20_Hev_Tx" SG_ 74 VedsDrvCrtnBag_D_Ltchd 1;
BA_ "U_U611_U625_MY20_Gas_Tx" SG_ 74 VedsDrvCrtnBag_D_Ltchd 1;
BA_ "U_U611_U625_MY20_Diesel_Tx" SG_ 74 VedsDrvCrtnBag_D_Ltchd 1;
BA_ "U_B500_MY18_Diesel_Tx" SG_ 74 VedsDrvCrtnBag_D_Ltchd 1;
BA_ "U_B500_MY18_Gas_Tx" SG_ 74 VedsDrvCrtnBag_D_Ltchd 1;
BA_ "U_C490_MY18_Tx" SG_ 74 VedsDrvCrtnBag_D_Ltchd 1;
BA_ "U_B562_MY18_Gas_Tx" SG_ 74 VedsDrvCrtnBag_D_Ltchd 1;
BA_ "U_C519_MY18_5_Gas_Tx" SG_ 74 VedsDrvCrtnBag_D_Ltchd 1;
BA_ "U_C519_MY18_5_Diesel_Tx" SG_ 74 VedsDrvCrtnBag_D_Ltchd 1;
BA_ "U_B515_MCA_MY17_Gas_Tx" SG_ 74 VedsDrvCrtnBag_D_Ltchd 1;
BA_ "U_B515_MCA_MY17_Diesel_Tx" SG_ 74 VedsDrvCrtnBag_D_Ltchd 1;
BA_ "U_B479_MY17_Diesel_Tx" SG_ 74 VedsDrvCrtnBag_D_Ltchd 1;
BA_ "U_B479_MY17_Gas_Tx" SG_ 74 VedsDrvCrtnBag_D_Ltchd 1;
BA_ "GenSigSendType" SG_ 74 VedsDrvCrtnBag_D_Ltchd 3;
BA_ "GenSigTimeoutTime_GWM" SG_ 74 VedsDrvBelt_D_Ltchd 300;
BA_ "U_CX482_CX483_MY20_Hev_Tx" SG_ 74 VedsDrvBelt_D_Ltchd 1;
BA_ "U_CX482_CX483_MY20_Gas_Tx" SG_ 74 VedsDrvBelt_D_Ltchd 1;
BA_ "U_CX482_CX483_MY20_Diesel_Tx" SG_ 74 VedsDrvBelt_D_Ltchd 1;
BA_ "U_U611_U625_MY20_Hev_Tx" SG_ 74 VedsDrvBelt_D_Ltchd 1;
BA_ "U_U611_U625_MY20_Gas_Tx" SG_ 74 VedsDrvBelt_D_Ltchd 1;
BA_ "U_U611_U625_MY20_Diesel_Tx" SG_ 74 VedsDrvBelt_D_Ltchd 1;
BA_ "U_B500_MY18_Diesel_Tx" SG_ 74 VedsDrvBelt_D_Ltchd 1;
BA_ "U_B500_MY18_Gas_Tx" SG_ 74 VedsDrvBelt_D_Ltchd 1;
BA_ "U_C490_MY18_Tx" SG_ 74 VedsDrvBelt_D_Ltchd 1;
BA_ "U_B562_MY18_Gas_Tx" SG_ 74 VedsDrvBelt_D_Ltchd 1;
BA_ "U_C519_MY18_5_Gas_Tx" SG_ 74 VedsDrvBelt_D_Ltchd 1;
BA_ "U_C519_MY18_5_Diesel_Tx" SG_ 74 VedsDrvBelt_D_Ltchd 1;
BA_ "U_B515_MCA_MY17_Gas_Tx" SG_ 74 VedsDrvBelt_D_Ltchd 1;
BA_ "U_B515_MCA_MY17_Diesel_Tx" SG_ 74 VedsDrvBelt_D_Ltchd 1;
BA_ "U_B479_MY17_Diesel_Tx" SG_ 74 VedsDrvBelt_D_Ltchd 1;
BA_ "U_B479_MY17_Gas_Tx" SG_ 74 VedsDrvBelt_D_Ltchd 1;
BA_ "GenSigSendType" SG_ 74 VedsDrvBelt_D_Ltchd 3;
BA_ "GenSigTimeoutTime_GWM" SG_ 74 VedsDrvBag_D_Ltchd 300;
BA_ "U_CX482_CX483_MY20_Hev_Tx" SG_ 74 VedsDrvBag_D_Ltchd 1;
BA_ "U_CX482_CX483_MY20_Gas_Tx" SG_ 74 VedsDrvBag_D_Ltchd 1;
BA_ "U_CX482_CX483_MY20_Diesel_Tx" SG_ 74 VedsDrvBag_D_Ltchd 1;
BA_ "U_U611_U625_MY20_Hev_Tx" SG_ 74 VedsDrvBag_D_Ltchd 1;
BA_ "U_U611_U625_MY20_Gas_Tx" SG_ 74 VedsDrvBag_D_Ltchd 1;
BA_ "U_U611_U625_MY20_Diesel_Tx" SG_ 74 VedsDrvBag_D_Ltchd 1;
BA_ "U_B500_MY18_Diesel_Tx" SG_ 74 VedsDrvBag_D_Ltchd 1;
BA_ "U_B500_MY18_Gas_Tx" SG_ 74 VedsDrvBag_D_Ltchd 1;
BA_ "U_C490_MY18_Tx" SG_ 74 VedsDrvBag_D_Ltchd 1;
BA_ "U_B562_MY18_Gas_Tx" SG_ 74 VedsDrvBag_D_Ltchd 1;
BA_ "U_C519_MY18_5_Gas_Tx" SG_ 74 VedsDrvBag_D_Ltchd 1;
BA_ "U_C519_MY18_5_Diesel_Tx" SG_ 74 VedsDrvBag_D_Ltchd 1;
BA_ "U_B515_MCA_MY17_Gas_Tx" SG_ 74 VedsDrvBag_D_Ltchd 1;
BA_ "U_B515_MCA_MY17_Diesel_Tx" SG_ 74 VedsDrvBag_D_Ltchd 1;
BA_ "U_B479_MY17_Diesel_Tx" SG_ 74 VedsDrvBag_D_Ltchd 1;
BA_ "U_B479_MY17_Gas_Tx" SG_ 74 VedsDrvBag_D_Ltchd 1;
BA_ "GenSigSendType" SG_ 74 VedsDrvBag_D_Ltchd 3;
BA_ "GenSigTimeoutTime_GWM" SG_ 74 eCallNotification 300;
BA_ "U_CX482_CX483_MY20_Hev_Tx" SG_ 74 eCallNotification 1;
BA_ "U_CX482_CX483_MY20_Gas_Tx" SG_ 74 eCallNotification 1;
BA_ "U_CX482_CX483_MY20_Diesel_Tx" SG_ 74 eCallNotification 1;
BA_ "U_U611_U625_MY20_Hev_Tx" SG_ 74 eCallNotification 1;
BA_ "U_U611_U625_MY20_Gas_Tx" SG_ 74 eCallNotification 1;
BA_ "U_U611_U625_MY20_Diesel_Tx" SG_ 74 eCallNotification 1;
BA_ "U_B500_MY18_Diesel_Tx" SG_ 74 eCallNotification 1;
BA_ "U_B500_MY18_Gas_Tx" SG_ 74 eCallNotification 1;
BA_ "U_C490_MY18_Tx" SG_ 74 eCallNotification 1;
BA_ "U_B562_MY18_Gas_Tx" SG_ 74 eCallNotification 1;
BA_ "U_C519_MY18_5_Gas_Tx" SG_ 74 eCallNotification 1;
BA_ "U_C519_MY18_5_Diesel_Tx" SG_ 74 eCallNotification 1;
BA_ "U_B515_MCA_MY17_Gas_Tx" SG_ 74 eCallNotification 1;
BA_ "U_B515_MCA_MY17_Diesel_Tx" SG_ 74 eCallNotification 1;
BA_ "U_B479_MY17_Diesel_Tx" SG_ 74 eCallNotification 1;
BA_ "U_B479_MY17_Gas_Tx" SG_ 74 eCallNotification 1;
BA_ "GenSigSendType" SG_ 74 eCallNotification 3;
BA_ "GenSigStartValue" SG_ 74 eCallNotification 1;
VAL_ 963 Illuminated_Entry_Stat 3 "Invalid" 2 "Unknown" 1 "On" 0 "Off" ;
VAL_ 963 Dr_Courtesy_Light_Stat 3 "Invalid" 2 "Unknown" 1 "On" 0 "Off" ;
VAL_ 963 Courtesy_Delay_Status 3 "Invalid" 2 "Unknown" 1 "On" 0 "Off" ;
VAL_ 963 ImpactEvntFdbck_D_Stat 3 "NotUsed" 2 "EventComplete" 1 "EventInProgress" 0 "Normal" ;
VAL_ 963 WrlssAcsyChrgInhbt_B_Rq 1 "Yes" 0 "No" ;
VAL_ 963 DrTgateLck_D_Stat 3 "NotUsed" 2 "Unlock" 1 "Lock" 0 "Null" ;
VAL_ 963 PudLampPsngr_D_Rq 3 "Ramp_Down" 2 "Ramp_Up" 1 "On" 0 "Off" ;
VAL_ 963 HeadLampLoOut_B_Stat 1 "Out" 0 "Null" ;
VAL_ 963 HeadLghtHiFdbck_D_Stat 3 "NotUsed" 2 "Cancel" 1 "Hold" 0 "Allow_Change" ;
VAL_ 963 PrkLightChime_B_Rq 1 "On" 0 "Off" ;
VAL_ 963 TrnNotInPrkChime_B_Rq 1 "On" 0 "Off" ;
VAL_ 963 KeyInIgnWarn_B_Cmd 1 "On" 0 "Off" ;
VAL_ 963 HomeSafeLtChime_B_Rq 1 "On" 0 "Off" ;
VAL_ 963 StopLghtOn_B_Stat 1 "On" 0 "Off" ;
VAL_ 963 RvrseLghtOn_B_Stat 1 "On" 0 "Off" ;
VAL_ 963 PrkLght_D_Stat 3 "Park_Both" 2 "Park_Right" 1 "Park_Left" 0 "Off" ;
VAL_ 963 HeadLghtSwtch_D_Stat 3 "Autolamp" 2 "Headlamp" 1 "Parklamp" 0 "Off" ;
VAL_ 963 HeadLampLoFrOn_B_Stat 1 "Low" 0 "Not_Low" ;
VAL_ 963 HeadLampLoFlOn_B_Stat 1 "Low" 0 "Not_Low" ;
VAL_ 963 HeadLampLoActv_B_Stat 1 "On" 0 "Off" ;
VAL_ 963 Headlamp_On_Wrning_Cmd 1 "On" 0 "Off" ;
VAL_ 963 HeadLghtHiOn_B_Stat 1 "On" 0 "Off" ;
VAL_ 963 Park_Brake_Chime_Rqst 1 "On" 0 "Off" ;
VAL_ 963 BrkWarnInd_B_Rq 1 "On" 0 "Off" ;
VAL_ 963 Brk_Fluid_Lvl_Low 3 "Invalid" 2 "Unknown" 1 "Low" 0 "OK" ;
VAL_ 963 ReducedGuard_D_Stat 3 "NotUsed" 2 "Alarm_On" 1 "Alarm_Off_Previously_On" 0 "Alarm_Off" ;
VAL_ 963 Perimeter_Alarm_Status 3 "Activated" 2 "Armed" 1 "Prearmed" 0 "Disarmed" ;
VAL_ 963 PudLampDrv_D_Rq 3 "Ramp_Down" 2 "Ramp_Up" 1 "On" 0 "Off" ;
VAL_ 963 Courtesy_BSave_Stat 3 "Invalid" 2 "Unknown" 1 "No_Effect" 0 "Off" ;
VAL_ 963 DayRnngLampOn_B_Stat 1 "On" 0 "Off" ;
VAL_ 963 WndwGlbl_D_Cmd 7 "NotUsed3" 6 "NotUsed2" 5 "NotUsed1" 4 "GLEARN" 3 "GCLOSE" 2 "GOPEN" 1 "GSTOP" 0 "Null" ;
VAL_ 963 PudLamp_D_Rq 3 "RAMP_DOWN" 2 "RAMP_UP" 1 "ON" 0 "OFF" ;
VAL_ 963 PerimeterAlarmChimeRq 1 "On" 0 "Off" ;
VAL_ 972 LsmcBrkDecelEnbl_D_Rq 3 "NotUsed2" 2 "NotUsed1" 1 "On" 0 "Off" ;
VAL_ 972 TjaHandsOnCnfdnc_B_Est 1 "High_Confidence" 0 "Low_Confidence" ;
VAL_ 972 LaHandsOff_B_Actl 1 "Hands_Off" 0 "Hands_On" ;
VAL_ 972 LaActDeny_B_Actl 1 "LA_Denied" 0 "LA_Not_Denied" ;
VAL_ 972 LaActAvail_D_Actl 3 "LKA_LCA_LDW_Avail" 2 "LCA_LKA_Avail_LDW_Suppress" 1 "LCA_LKA_Suppress_LDW_Avail" 0 "LCA_LKA_LDW_Suppress" ;
VAL_ 991 PersIndexVdm_D_Actl 7 "Unused_3" 6 "Unused_2" 5 "Unused_1" 4 "Vehicle" 3 "PERS_4" 2 "PERS_3" 1 "PERS_2" 0 "PERS_1" ;
VAL_ 391 CadsRadarStat_D_Qf 3 "OK" 2 "Not_Within_Specifications" 1 "No_Data_Exists" 0 "Faulty" ;
VAL_ 391 CadsAudioMute_D_Rq 3 "Reserved" 2 "Partial_Audio_Mute" 1 "Full_Audio_Mute" 0 "No_Audio_Mute" ;
VAL_ 391 HudBlk3_B_Rq 1 "Yes" 0 "No" ;
VAL_ 391 HudBlk2_B_Rq 1 "Yes" 0 "No" ;
VAL_ 391 HudBlk1_B_Rq 1 "Yes" 0 "No" ;
VAL_ 391 HudFlashRate_D_Actl 3 "Unused" 2 "Flash_4Hz_50Prct_DutyCycle" 1 "On" 0 "Off" ;
VAL_ 391 CmbbBrkPrchg_D_Rq 3 "Undefined" 2 "Level_2_PreCharge_Request" 1 "Level_1_PreCharge_Request" 0 "No_PreCharge_Request" ;
VAL_ 391 CmbbBrkDecel_B_Rq 1 "Yes" 0 "No" ;
VAL_ 391 CmbbBaSens_D_Rq 3 "Level_3" 2 "Level_2" 1 "Level_1" 0 "Normal" ;
VAL_ 535 WhlRr_W_Meas 32767 "Fault" 32766 "Unknown" ;
VAL_ 535 WhlRl_W_Meas 32767 "Fault" 32766 "Unknown" ;
VAL_ 535 WhlFr_W_Meas 32767 "Fault" 32766 "Unknown" ;
VAL_ 535 WhlFl_W_Meas 32767 "Fault" 32766 "Unknown" ;
VAL_ 532 RgenTqFalt_B_Actl 1 "Fault" 0 "No_Fault" ;
VAL_ 532 RgenBrkDynoMde_B_Actl 1 "TwoWheelDyno" 0 "NormalOperation" ;
VAL_ 531 VehStop_D_Stat 3 "Faulty" 2 "NoDataExists" 1 "Yes" 0 "No" ;
VAL_ 531 TracCtlPtActv_B_Actl 1 "Active" 0 "Inactive" ;
VAL_ 531 LscmbbMntr_B_Err 1 "DisplayMessage" 0 "NoMessage" ;
VAL_ 531 LscmbbBrkDis_B_Actl 1 "Yes" 0 "No" ;
VAL_ 531 LscmbbDeny_B_ActlBrk 1 "Yes" 0 "No" ;
VAL_ 531 PrkBrkYwLamp_D_Rq 3 "Fast_Flash" 2 "Slow_Flash" 1 "On" 0 "Off" ;
VAL_ 531 PrkBrkRedLamp_D_Rq 3 "Fast_Flash" 2 "Slow_Flash" 1 "On" 0 "Off" ;
VAL_ 531 VehicleStationary 1 "Yes" 0 "No" ;
VAL_ 531 LscmbbBrkDecel_B_Actl 1 "Yes" 0 "No" ;
VAL_ 531 AbsActv_B_Actl 1 "Yes" 0 "No" ;
VAL_ 531 StabCtlBrkActv_B_Actl 1 "Yes" 0 "No" ;
VAL_ 531 CmbbBrkPrchg_B_Actl 1 "Yes" 0 "No" ;
VAL_ 531 CmbbBrkDecel_B_Actl 1 "Yes" 0 "No" ;
VAL_ 531 CmbbBaSensInc_B_Actl 1 "Yes" 0 "No" ;
VAL_ 531 AccBrkWarm_B_Actl 1 "Yes" 0 "No" ;
VAL_ 531 AccBrkTotTqMn_B_Actl 1 "Yes" 0 "No" ;
VAL_ 531 AccBrkPrchgActv_B_Actl 1 "Yes" 0 "No" ;
VAL_ 531 AccBrkDis_B_Actl 1 "Yes" 0 "No" ;
VAL_ 531 AccBrkDeny_B_Actl 1 "Yes" 0 "No" ;
VAL_ 531 AccBrkActv_B_Actl 1 "Yes" 0 "No" ;
VAL_ 531 PrplDrgCtlActv_B_Actl 1 "Active" 0 "Inactive" ;
VAL_ 531 LscmbbBaSensInc_B_Actl 1 "Yes" 0 "No" ;
VAL_ 531 CmbbBrkDis_B_Actl 1 "Yes" 0 "No" ;
VAL_ 531 CmbbDeny_B_ActlBrk 1 "Yes" 0 "No" ;
VAL_ 531 CcDis_B_Cmd 1 "Yes" 0 "No" ;
VAL_ 531 VehLongOvrGnd_A_Est 1023 "Fault" 1022 "Unknown" ;
VAL_ 531 LscmbBrkPrchg_B_Actl 1 "Active" 0 "Inactive" ;
VAL_ 531 AccStopActv_B_ActlBrk 1 "Yes" 0 "No" ;
VAL_ 531 AccDis_B_ActlEpb 1 "Yes" 0 "No" ;
VAL_ 531 PrkBrkMsgTxt_D_Rq 15 "Message15" 14 "Message14" 13 "Message13" 12 "Message12" 11 "Message11" 10 "Message10" 9 "Message9" 8 "Message8" 7 "Message7" 6 "Message6" 5 "Message5" 4 "Message4" 3 "Message3" 2 "Message2" 1 "Message1" 0 "No_Message" ;
VAL_ 531 PrkBrkStatus 7 "GeneralFault_MaintenceMode" 6 "ECD_by_Brake_ECU_Active" 5 "EPB_Limphome_Active" 4 "Rear_Caliper_Open" 3 "RWU_By_EPB_Active" 2 "Rear_Caliper_Transition" 1 "Rear_Caliper_Closed" 0 "Not_Supported" ;
VAL_ 137 SteWhlOffstRq_D_Stat 3 "Faulty" 2 "NoDataExists" 1 "Allow_External_Angle_Req" 0 "Deny_External_Angle_Req" ;
VAL_ 137 SteWhlOffst_An_TotActl 32767 "Faulty" 32766 "NoDataExists" ;
VAL_ 137 SteWhlBrkOffst_An_Actl 32767 "Faulty" 32766 "NoDataExists" ;
VAL_ 136 SteWhlBrkOffst_An_Rq 32767 "Faulty" 32766 "NoDataExists" ;
VAL_ 604 WhlDirAvgDrv_D_Actl 3 "Failed" 2 "Unknown" 1 "Backward" 0 "Forward" ;
VAL_ 604 PrplTqMnRgen_B_Actl 1 "Yes" 0 "No" ;
VAL_ 604 WhlDirAvgDrv_D_Actl_UB 1 "Fresh_data" 0 "Unchanged_data" ;
VAL_ 604 PrplTqMnRgen_B_Actl_UB 1 "Fresh_data" 0 "Unchanged_data" ;
VAL_ 125 VehRolComp_W_Actl 4094 "NoDataExists" 4095 "Fault" ;
VAL_ 125 VehVertComp_A_Actl 1022 "NoDataExists" 1023 "Fault" ;
VAL_ 125 BrkTot_Tq_RqArb 8191 "Fault" 8190 "Unknown" ;
VAL_ 125 BrkTot_Tq_Actl 8191 "Fault" 8190 "Unknown" ;
VAL_ 125 HsaStat_D_Actl 7 "Faulty" 6 "FaultyWithDriverIndication" 5 "SlowRelease" 4 "FastRelease" 3 "ActiveBrakePedalReleased" 2 "ActiveBrakePedalPressed" 1 "FindingGradient" 0 "Inactive" ;
VAL_ 119 VehTrvlDir_D_Stat 7 "Faulty" 6 "NoDataExists" 5 "NotUsed2" 4 "NotUsed1" 3 "Reverse" 2 "LikelyReverse" 1 "Forward" 0 "LikelyForward" ;
VAL_ 119 VehOverGnd_V_Est 65535 "Invalid" 65534 "Unknown" ;
VAL_ 119 VehLongComp_A_Actl 1023 "Fault" 1022 "NoDataExists" ;
VAL_ 119 VehLatComp_A_Actl 1023 "Fault" 1022 "NoDataExists" ;
VAL_ 119 VehYawComp_W_Actl 4095 "Fault" 4094 "NoDataExists" ;
VAL_ 119 VehYaw_W_Rq 4095 "Fault" 4094 "NoDataExists" ;
VAL_ 118 BrkCtrFnd_B_Stat 1 "Yes" 0 "No" ;
VAL_ 118 BrkTerrMdeChng_D_Rdy 7 "Fault" 6 "Undefined_2" 5 "Undefined_1" 4 "ModeUnavailDrInputRqd" 3 "SpOpModes_NotSupported" 2 "ModeUnavailDynamicCond" 1 "Module_In_Initialization" 0 "Mode_Change_Available" ;
VAL_ 118 BrkTerrMde_D_Actl 7 "Fail_Safe_Default" 6 "Dynamic_Mode" 5 "Rock_Crawl_Mode" 4 "Mud_Ruts_Mode" 3 "Sand_Mode" 2 "Undefined" 1 "Low_Mu_Mode" 0 "Special_Operating_Mode_Off" ;
VAL_ 118 DrvSte_D_Stat 15 "NotUsed10" 14 "NotUsed9" 13 "NotUsed8" 12 "NotUsed7" 11 "NotUsed6" 10 "NotUsed5" 9 "NotUsed4" 8 "NotUsed3" 7 "NotUsed2" 6 "NotUsed1" 5 "Request_Active" 4 "Ignition_Off" 3 "DSR_in_Normal_Idle_Mode" 2 "EPAS_Comm_Disturbed" 1 "DSR_Request_Not_Applicable" 0 "DSR_Deactivated" ;
VAL_ 118 DrvSte_Tq_Rq 255 "Invalid" 254 "Unknown" ;
VAL_ 118 EmgcyBrkLamp_D_Rq 3 "NotUsed" 2 "Active_at_standstill" 1 "Active_at_speed" 0 "Inactive" ;
VAL_ 118 StopLamp_B_RqBrk 1 "Active" 0 "Inactive" ;
VAL_ 118 VehDynamicsSOS 1 "Yes" 0 "No" ;
VAL_ 118 SteWhlCompAnEst_D_Qf 3 "OK" 2 "Not_Within_Specifications" 1 "No_Data_Exists" 0 "Faulty" ;
VAL_ 75 VedsPasKneeBag_D_Ltchd 7 "Fault" 6 "NotSupported" 5 "Unused_3" 4 "Unused_2" 3 "Unused_1" 2 "NotDeployed" 1 "Deployed" 0 "NoEvent" ;
VAL_ 75 VedsRw3pRib_D_Ltchd 7 "Fault" 6 "NotSupported" 5 "Unused_3" 4 "Unused_2" 3 "Unused_1" 2 "NotDeployed" 1 "Deployed" 0 "NoEvent" ;
VAL_ 75 VedsRw3dRib_D_Ltchd 7 "Fault" 6 "NotSupported" 5 "Unused_3" 4 "Unused_2" 3 "Unused_1" 2 "NotDeployed" 1 "Deployed" 0 "NoEvent" ;
VAL_ 75 VedsRw1mBckl_D_Ltchd 5 "Unused_3" 4 "Unused_2" 3 "Unused_1" 2 "NotBelted" 1 "Belted" 0 "NoEvent" 7 "Fault" 6 "NotSupported" ;
VAL_ 75 VedsRw1mBelt_D_Ltchd 7 "Fault" 6 "NotSupported" 5 "Unused_3" 4 "Unused_2" 3 "Unused_1" 2 "NotDeployed" 1 "Deployed" 0 "NoEvent" ;
VAL_ 75 VedsRw2pRib_D_Ltchd 7 "Fault" 6 "NotSupported" 5 "Unused_3" 4 "Unused_2" 3 "Unused_1" 2 "NotDeployed" 1 "Deployed" 0 "NoEvent" ;
VAL_ 75 VedsRw2dRib_D_Ltchd 7 "Fault" 6 "NotSupported" 5 "Unused_3" 4 "Unused_2" 3 "Unused_1" 2 "NotDeployed" 1 "Deployed" 0 "NoEvent" ;
VAL_ 75 VedsRw3pBckl_D_Ltchd 5 "Unused_3" 4 "Unused_2" 3 "Unused_1" 2 "NotBelted" 1 "Belted" 0 "NoEvent" 7 "Fault" 6 "NotSupported" ;
VAL_ 75 VedsRw3mBckl_D_Ltchd 5 "Unused_3" 4 "Unused_2" 3 "Unused_1" 2 "NotBelted" 1 "Belted" 0 "NoEvent" 7 "Fault" 6 "NotSupported" ;
VAL_ 75 VedsRw3dBckl_D_Ltchd 5 "Unused_3" 4 "Unused_2" 3 "Unused_1" 2 "NotBelted" 1 "Belted" 0 "NoEvent" 7 "Fault" 6 "NotSupported" ;
VAL_ 75 VedsRw2pBckl_D_Ltchd 5 "Unused_3" 4 "Unused_2" 3 "Unused_1" 2 "NotBelted" 1 "Belted" 0 "NoEvent" 7 "Fault" 6 "NotSupported" ;
VAL_ 75 VedsRw2mBckl_D_Ltchd 5 "Unused_3" 4 "Unused_2" 3 "Unused_1" 2 "NotBelted" 1 "Belted" 0 "NoEvent" 7 "Fault" 6 "NotSupported" ;
VAL_ 75 VedsRw2dBckl_D_Ltchd 5 "Unused_3" 4 "Unused_2" 3 "Unused_1" 2 "NotBelted" 1 "Belted" 0 "NoEvent" 7 "Fault" 6 "NotSupported" ;
VAL_ 75 VedsRw1PasChld_D_Ltchd 7 "Fault" 6 "NotSupported" 5 "Unused_3" 4 "Unused_2" 3 "Unused_1" 2 "ChildNotDetected" 1 "ChildDetected" 0 "NoEvent" ;
VAL_ 75 VedsRw1PasBckl_D_Ltchd 5 "Unused_3" 4 "Unused_2" 3 "Unused_1" 2 "NotBelted" 1 "Belted" 0 "NoEvent" 7 "Fault" 6 "NotSupported" ;
VAL_ 75 VedsRw1DrvBckl_D_Ltchd 5 "Unused_3" 4 "Unused_2" 3 "Unused_1" 2 "NotBelted" 1 "Belted" 0 "NoEvent" 7 "Fault" 6 "NotSupported" ;
VAL_ 74 VedsPasSideBag_D_Ltchd 7 "Fault" 6 "NotSupported" 5 "Unused_3" 4 "Unused_2" 3 "Unused_1" 2 "NotDeployed" 1 "Deployed" 0 "NoEvent" ;
VAL_ 74 VedsPasCrtnBag_D_Ltchd 7 "Fault" 6 "NotSupported" 5 "Unused_3" 4 "Unused_2" 3 "Unused_1" 2 "NotDeployed" 1 "Deployed" 0 "NoEvent" ;
VAL_ 74 VedsPasBelt_D_Ltchd 7 "Fault" 6 "NotSupported" 5 "Unused_3" 4 "Unused_2" 3 "Unused_1" 2 "NotDeployed" 1 "Deployed" 0 "NoEvent" ;
VAL_ 74 VedsPasBag_D_Ltchd 7 "Fault" 6 "NotSupported" 5 "Unused_3" 4 "Unused_2" 3 "Unused_1" 2 "NotDeployed" 1 "Deployed" 0 "NoEvent" ;
VAL_ 74 VedsMultiEvnt_D_Ltchd 7 "Fault" 6 "NotSupported" 5 "Unused_3" 4 "Unused_2" 3 "Unused_1" 2 "Yes" 1 "No" 0 "NoEvent" ;
VAL_ 74 VedsMaxDeltaV_D_Ltchd 0 "NoEvent" 255 "Fault" 254 "NotSupported" ;
VAL_ 74 VedsDrvKneeBag_D_Ltchd 7 "Fault" 6 "NotSupported" 5 "Unused_3" 4 "Unused_2" 3 "Unused_1" 2 "NotDeployed" 1 "Deployed" 0 "NoEvent" ;
VAL_ 74 VedsEvntType_D_Ltchd 7 "Fault" 6 "NotSupported" 5 "Unused" 4 "Rolllover" 3 "Rear" 2 "Side" 1 "Frontal" 0 "NoEvent" ;
VAL_ 74 VedsEvntRoll_D_Ltchd 7 "Fault" 6 "NotSupported" 5 "Unused_3" 4 "Unused_2" 3 "Unused_1" 2 "Yes" 1 "No" 0 "NoEvent" ;
VAL_ 74 VedsDrvSideBag_D_Ltchd 7 "Fault" 6 "NotSupported" 5 "Unused_3" 4 "Unused_2" 3 "Unused_1" 2 "NotDeployed" 1 "Deployed" 0 "NoEvent" ;
VAL_ 74 VedsDrvCrtnBag_D_Ltchd 7 "Fault" 6 "NotSupported" 5 "Unused_3" 4 "Unused_2" 3 "Unused_1" 2 "NotDeployed" 1 "Deployed" 0 "NoEvent" ;
VAL_ 74 VedsDrvBelt_D_Ltchd 7 "Fault" 6 "NotSupported" 5 "Unused_3" 4 "Unused_2" 3 "Unused_1" 2 "NotDeployed" 1 "Deployed" 0 "NoEvent" ;
VAL_ 74 VedsDrvBag_D_Ltchd 7 "Fault" 6 "NotSupported" 5 "Unused_3" 4 "Unused_2" 3 "Unused_1" 2 "NotDeployed" 1 "Deployed" 0 "NoEvent" ;
VAL_ 74 eCallNotification 3 "Not_Used" 2 "Active" 1 "Normal" 0 "Not_Supported" ;
